VERSION ""

NS_ :

BS_:

BU_: MCTM_LS TIM_LS EOCM2cp_K2_LS EOCM2cp_K1_LS ADIMa_LS BCM_LS SAM_SR_LS SAM_SL_LS SAM_PR_LS SAM_PL_LS CGM3a_LS Dummy_LS VICM_LS ECC_LS PEPS_LS AOS_LS SDM_PR_LS AOS2_LS DLM_LS SCCM_2_LS SCCM_1_LS UPA_LS ADIMb_LS

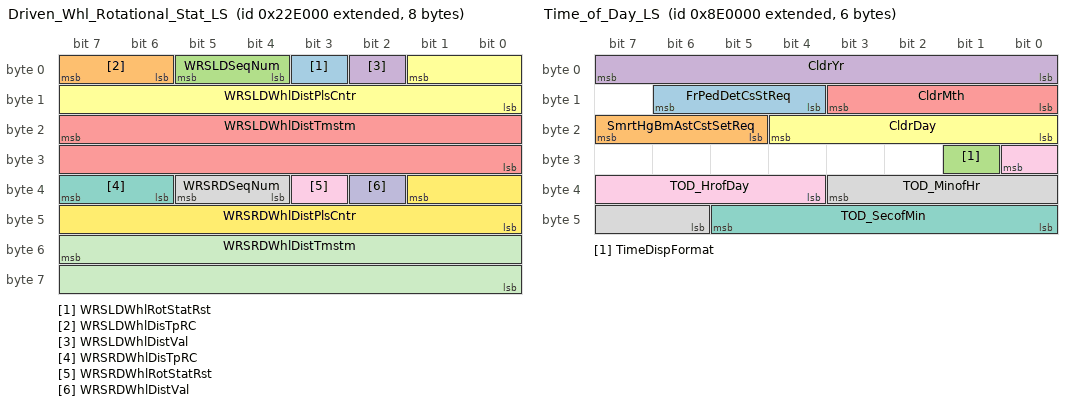
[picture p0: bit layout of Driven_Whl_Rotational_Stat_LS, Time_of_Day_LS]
BO_ 2149769216 Driven_Whl_Rotational_Stat_LS: 8 BCM_LS
 SG_ WRSLDWhlRotStatRst : 3|1@0+ (1,0) [0|1] ""  CGM3a_LS,UPA_LS
 SG_ WRSLDWhlDisTpRC : 7|2@0+ (1,0) [0|3] "counts"  CGM3a_LS,UPA_LS
 SG_ WRSLDSeqNum : 5|2@0+ (1,0) [0|3] "counts"  CGM3a_LS,UPA_LS
 SG_ WRSLDWhlDistVal : 2|1@0+ (1,0) [0|1] ""  CGM3a_LS,UPA_LS
 SG_ WRSLDWhlDistTmstm : 23|16@0+ (1,0) [0|65535] "counts"  CGM3a_LS,UPA_LS
 SG_ WRSLDWhlDistPlsCntr : 1|10@0+ (1,0) [0|1023] "counts"  CGM3a_LS,UPA_LS
 SG_ WRSRDWhlDisTpRC : 39|2@0+ (1,0) [0|3] "counts"  CGM3a_LS,UPA_LS
 SG_ WRSRDSeqNum : 37|2@0+ (1,0) [0|3] "counts"  CGM3a_LS,UPA_LS
 SG_ WRSRDWhlRotStatRst : 35|1@0+ (1,0) [0|1] ""  CGM3a_LS,UPA_LS
 SG_ WRSRDWhlDistVal : 34|1@0+ (1,0) [0|1] ""  CGM3a_LS,UPA_LS
 SG_ WRSRDWhlDistTmstm : 55|16@0+ (1,0) [0|65535] "counts"  CGM3a_LS,UPA_LS
 SG_ WRSRDWhlDistPlsCntr : 33|10@0+ (1,0) [0|1023] "counts"  CGM3a_LS,UPA_LS

BO_ 2156789760 Time_of_Day_LS: 6 CGM3a_LS
 SG_ FrPedDetCsStReq : 14|3@0+ (1,0) [0|7] ""  EOCM2cp_K1_LS
 SG_ SmrtHgBmAstCstSetReq : 23|3@0+ (1,0) [0|7] ""  EOCM2cp_K2_LS
 SG_ TimeDispFormat : 25|1@0+ (1,0) [0|1] ""  VICM_LS,EOCM2cp_K1_LS
 SG_ CldrYr : 7|8@0+ (1,2000) [2000|2255] "year"  EOCM2cp_K1_LS,VICM_LS,BCM_LS
 SG_ CldrMth : 11|4@0+ (1,0) [0|15] ""  EOCM2cp_K1_LS,ECC_LS,VICM_LS,BCM_LS
 SG_ CldrDay : 20|5@0+ (1,0) [0|31] "days"  EOCM2cp_K1_LS,ECC_LS,VICM_LS,BCM_LS
 SG_ TOD_SecofMin : 45|6@0+ (1,0) [0|63] "s"  VICM_LS,EOCM2cp_K1_LS,ECC_LS,BCM_LS
 SG_ TOD_MinofHr : 35|6@0+ (1,0) [0|63] "min"  VICM_LS,EOCM2cp_K1_LS,ECC_LS,BCM_LS
 SG_ TOD_HrofDay : 24|5@0+ (1,0) [0|31] "hr"  VICM_LS,EOCM2cp_K1_LS,ECC_LS,BCM_LS

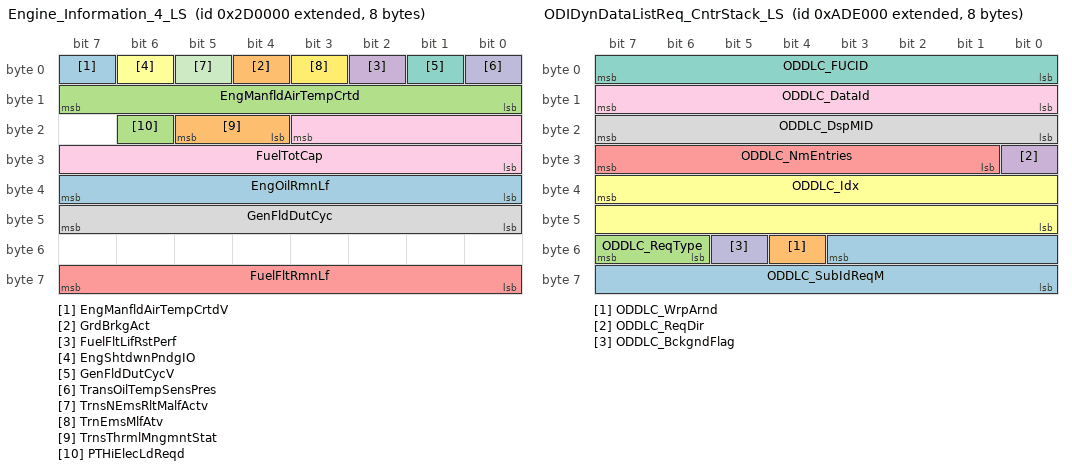
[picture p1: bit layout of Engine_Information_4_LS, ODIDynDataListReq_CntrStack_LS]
BO_ 2150432768 Engine_Information_4_LS: 8 BCM_LS
 SG_ EngManfldAirTempCrtdV : 7|1@0+ (1,0) [0|1] ""  CGM3a_LS,ECC_LS
 SG_ GrdBrkgAct : 4|1@0+ (1,0) [0|1] ""  CGM3a_LS
 SG_ EngManfldAirTempCrtd : 15|8@0+ (1,-40) [-40|215] "deg C"  CGM3a_LS,ECC_LS
 SG_ FuelFltLifRstPerf : 2|1@0+ (1,0) [0|1] ""  CGM3a_LS
 SG_ FuelFltRmnLf : 63|8@0+ (0.392157,0) [0|100.000035] "%"  CGM3a_LS
 SG_ EngShtdwnPndgIO : 6|1@0+ (1,0) [0|1] ""  CGM3a_LS
 SG_ GenFldDutCycV : 1|1@0+ (1,0) [0|1] ""  CGM3a_LS,ECC_LS
 SG_ GenFldDutCyc : 47|8@0+ (0.392157,0) [0|100.000035] "%"  CGM3a_LS,ECC_LS
 SG_ FuelTotCap : 19|12@0+ (0.125,0) [0|511.875] "liters"  CGM3a_LS
 SG_ TransOilTempSensPres : 0|1@0+ (1,0) [0|1] ""  CGM3a_LS
 SG_ TrnsNEmsRltMalfActv : 5|1@0+ (1,0) [0|1] ""  CGM3a_LS
 SG_ TrnEmsMlfAtv : 3|1@0+ (1,0) [0|1] ""  CGM3a_LS
 SG_ EngOilRmnLf : 39|8@0+ (0.392157,0) [0|100.000035] "%"  CGM3a_LS
 SG_ TrnsThrmlMngmntStat : 21|2@0+ (1,0) [0|3] ""  CGM3a_LS
 SG_ PTHiElecLdReqd : 22|1@0+ (1,0) [0|1] ""  CGM3a_LS,ECC_LS

BO_ 2155298816 Tire_Pressure_Sensor_Prog_Req_LS: 1 CGM3a_LS
 SG_ TrPrsMntrTrLdRstRqstd : 2|2@0+ (1,0) [0|3] ""  BCM_LS
 SG_ TrPrsSnsProgEvntRqd : 0|1@0+ (1,0) [0|1] ""  BCM_LS

BO_ 2158878720 ODIDynDataListReq_CntrStack_LS: 8 CGM3a_LS
 SG_ ODDLC_SubIdReqM : 51|12@0+ (1,0) [0|4095] ""  BCM_LS,CGM3a_LS
 SG_ ODDLC_WrpArnd : 52|1@0+ (1,0) [0|1] ""  BCM_LS,CGM3a_LS
 SG_ ODDLC_ReqType : 55|2@0+ (1,0) [0|3] ""  BCM_LS,CGM3a_LS
 SG_ ODDLC_ReqDir : 24|1@0+ (1,0) [0|1] ""  BCM_LS,CGM3a_LS
 SG_ ODDLC_NmEntries : 31|7@0+ (1,0) [0|127] ""  BCM_LS,CGM3a_LS
 SG_ ODDLC_Idx : 39|16@0+ (1,0) [0|65535] ""  BCM_LS,CGM3a_LS
 SG_ ODDLC_FUCID : 7|8@0+ (1,0) [0|255] ""  BCM_LS,CGM3a_LS
 SG_ ODDLC_DspMID : 23|8@0+ (1,0) [0|255] ""  BCM_LS,CGM3a_LS
 SG_ ODDLC_DataId : 15|8@0+ (1,0) [0|255] ""  BCM_LS,CGM3a_LS
 SG_ ODDLC_BckgndFlag : 53|1@0+ (1,0) [0|1] ""  BCM_LS,CGM3a_LS

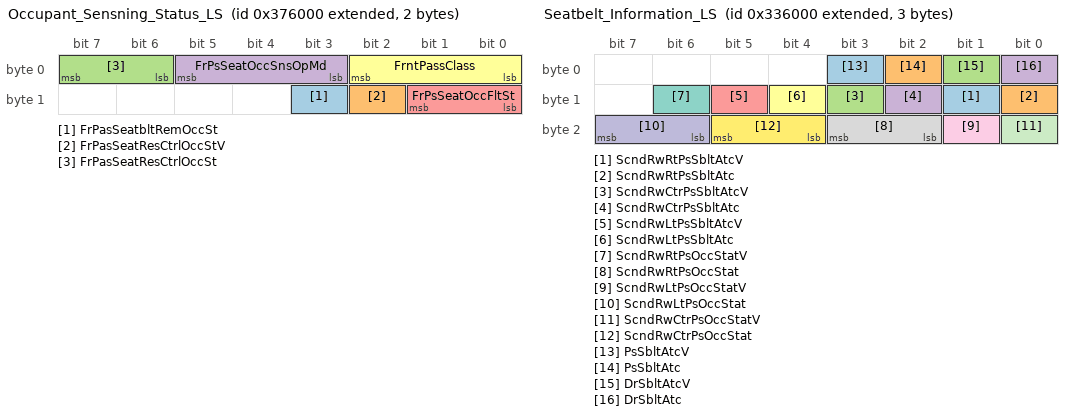
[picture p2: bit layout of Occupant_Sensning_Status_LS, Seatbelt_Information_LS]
BO_ 2151112704 Occupant_Sensning_Status_LS: 2 AOS_LS
 SG_ FrPasSeatbltRemOccSt : 11|1@0+ (1,0) [0|1] ""  MCTM_LS,CGM3a_LS,ADIMb_LS,SDM_PR_LS
 SG_ FrPasSeatResCtrlOccStV : 10|1@0+ (1,0) [0|1] ""  MCTM_LS,CGM3a_LS,ECC_LS,SDM_PR_LS
 SG_ FrPasSeatResCtrlOccSt : 7|2@0+ (1,0) [0|3] ""  MCTM_LS,CGM3a_LS,ECC_LS,SDM_PR_LS
 SG_ FrPsSeatOccSnsOpMd : 5|3@0+ (1,0) [0|7] "N/A"  CGM3a_LS,SDM_PR_LS
 SG_ FrPsSeatOccFltSt : 9|2@0+ (1,0) [0|3] "N/A"  MCTM_LS,CGM3a_LS,SDM_PR_LS
 SG_ FrntPassClass : 2|3@0+ (1,0) [0|7] ""  MCTM_LS,CGM3a_LS,SDM_PR_LS

BO_ 1367 UUDT_Resp_From_ADIMa_LS: 8 ADIMa_LS
 SG_ DgnInf_LS557 : 7|64@0+ (1,0) [0|1.84467440737096E+019] ""  CGM3a_LS

BO_ 2153947136 Remote_Reflash_Stat_LS: 1 BCM_LS
 SG_ RmtRflshMdAct : 7|1@0+ (1,0) [0|1] ""  CGM3a_LS

BO_ 2153938944 Remote_Reflash_Req_LS: 1 CGM3a_LS
 SG_ RmtRflshMdReqtd : 7|1@0+ (1,0) [0|1] ""  BCM_LS

BO_ 2028 USDT_Resp_From_VICM_LS: 8 VICM_LS
 SG_ DgnInf : 7|64@0+ (1,0) [0|1.84467440737096E+019] ""  CGM3a_LS

BO_ 2150662144 Environment_Id_Resp_3_LS: 3 CGM3a_LS
 SG_ EnvIdRsp3 : 7|16@0+ (1,0) [0|65535] ""  BCM_LS
 SG_ EnvIdRspSt3 : 17|2@0+ (1,0) [0|3] ""  BCM_LS

BO_ 2150653952 Environment_Id_Resp_2_LS: 3 ECC_LS
 SG_ EnvIdRspSt2 : 17|2@0+ (1,0) [0|3] ""  CGM3a_LS,BCM_LS
 SG_ EnvIdRsp2 : 7|16@0+ (1,0) [0|65535] ""  CGM3a_LS,BCM_LS

BO_ 2150850560 Seatbelt_Information_LS: 3 SDM_PR_LS
 SG_ ScndRwRtPsSbltAtcV : 9|1@0+ (1,0) [0|1] ""  ADIMa_LS,MCTM_LS,EOCM2cp_K2_LS,ADIMb_LS,BCM_LS,ECC_LS,CGM3a_LS
 SG_ ScndRwRtPsSbltAtc : 8|1@0+ (1,0) [0|1] ""  ADIMa_LS,MCTM_LS,EOCM2cp_K2_LS,ADIMb_LS,BCM_LS,ECC_LS,CGM3a_LS
 SG_ ScndRwCtrPsSbltAtcV : 11|1@0+ (1,0) [0|1] ""  ADIMa_LS,MCTM_LS,EOCM2cp_K2_LS,ADIMb_LS,BCM_LS,ECC_LS,CGM3a_LS
 SG_ ScndRwCtrPsSbltAtc : 10|1@0+ (1,0) [0|1] ""  ADIMa_LS,MCTM_LS,EOCM2cp_K2_LS,ADIMb_LS,BCM_LS,ECC_LS,CGM3a_LS
 SG_ ScndRwLtPsSbltAtcV : 13|1@0+ (1,0) [0|1] ""  ADIMa_LS,MCTM_LS,EOCM2cp_K2_LS,ADIMb_LS,BCM_LS,ECC_LS,CGM3a_LS
 SG_ ScndRwLtPsSbltAtc : 12|1@0+ (1,0) [0|1] ""  ADIMa_LS,MCTM_LS,EOCM2cp_K2_LS,ADIMb_LS,BCM_LS,ECC_LS,CGM3a_LS
 SG_ ScndRwRtPsOccStatV : 14|1@0+ (1,0) [0|1] ""  ADIMa_LS,ADIMb_LS,MCTM_LS,CGM3a_LS
 SG_ ScndRwRtPsOccStat : 19|2@0+ (1,0) [0|3] ""  ADIMa_LS,ADIMb_LS,MCTM_LS,CGM3a_LS
 SG_ ScndRwLtPsOccStatV : 17|1@0+ (1,0) [0|1] ""  ADIMa_LS,ADIMb_LS,MCTM_LS,CGM3a_LS
 SG_ ScndRwLtPsOccStat : 23|2@0+ (1,0) [0|3] ""  ADIMa_LS,ADIMb_LS,MCTM_LS,CGM3a_LS
 SG_ ScndRwCtrPsOccStatV : 16|1@0+ (1,0) [0|1] ""  ADIMa_LS,ADIMb_LS,MCTM_LS,CGM3a_LS
 SG_ ScndRwCtrPsOccStat : 21|2@0+ (1,0) [0|3] ""  ADIMa_LS,ADIMb_LS,MCTM_LS,CGM3a_LS
 SG_ PsSbltAtcV : 3|1@0+ (1,0) [0|1] ""  ADIMa_LS,ADIMb_LS,MCTM_LS,CGM3a_LS,ECC_LS,BCM_LS,AOS_LS
 SG_ PsSbltAtc : 2|1@0+ (1,0) [0|1] ""  ADIMa_LS,ADIMb_LS,MCTM_LS,CGM3a_LS,ECC_LS,BCM_LS,AOS_LS
 SG_ DrSbltAtcV : 1|1@0+ (1,0) [0|1] ""  AOS2_LS,ADIMa_LS,ADIMb_LS,MCTM_LS,CGM3a_LS,BCM_LS
 SG_ DrSbltAtc : 0|1@0+ (1,0) [0|1] ""  AOS2_LS,ADIMa_LS,ADIMb_LS,MCTM_LS,CGM3a_LS,BCM_LS

BO_ 2154938368 Fob_Programming_Mode_Status_LS: 1 BCM_LS
 SG_ FobProgMdStat : 1|2@0+ (1,0) [0|3] ""  CGM3a_LS

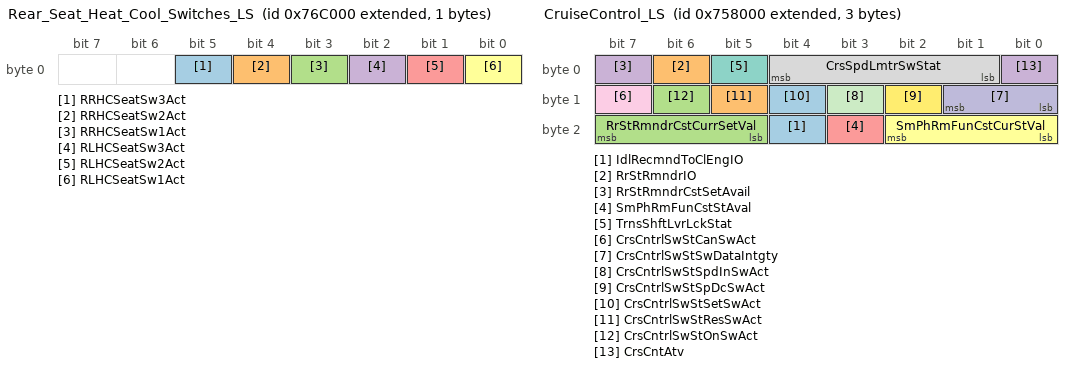
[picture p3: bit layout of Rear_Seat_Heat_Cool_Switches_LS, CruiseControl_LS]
BO_ 2155266048 Rear_Seat_Heat_Cool_Switches_LS: 1 ECC_LS
 SG_ RRHCSeatSw3Act : 5|1@0+ (1,0) [0|1] ""  CGM3a_LS,BCM_LS
 SG_ RRHCSeatSw2Act : 4|1@0+ (1,0) [0|1] ""  CGM3a_LS,BCM_LS
 SG_ RRHCSeatSw1Act : 3|1@0+ (1,0) [0|1] ""  CGM3a_LS,BCM_LS
 SG_ RLHCSeatSw3Act : 2|1@0+ (1,0) [0|1] ""  CGM3a_LS,BCM_LS
 SG_ RLHCSeatSw2Act : 1|1@0+ (1,0) [0|1] ""  CGM3a_LS,BCM_LS
 SG_ RLHCSeatSw1Act : 0|1@0+ (1,0) [0|1] ""  CGM3a_LS,BCM_LS

BO_ 2155249664 Rear_Seat_Heat_Cool_Control_LS: 4 BCM_LS
 SG_ RRHCSMInd3 : 8|1@0+ (1,0) [0|1] ""  CGM3a_LS,BCM_LS,ECC_LS
 SG_ RRHCSMInd2 : 9|1@0+ (1,0) [0|1] ""  CGM3a_LS,BCM_LS,ECC_LS
 SG_ RRHCSMInd1 : 10|1@0+ (1,0) [0|1] ""  CGM3a_LS,BCM_LS,ECC_LS
 SG_ RRHCSMIndReq : 12|2@0+ (1,0) [0|3] ""  CGM3a_LS,BCM_LS,ECC_LS
 SG_ RRHCSLSeatLev5 : 24|1@0+ (1,0) [0|1] ""  CGM3a_LS,BCM_LS,ECC_LS
 SG_ RRHCSLSeatLev4 : 25|1@0+ (1,0) [0|1] ""  CGM3a_LS,BCM_LS,ECC_LS
 SG_ RRHCSLSeatLev3 : 26|1@0+ (1,0) [0|1] ""  CGM3a_LS,BCM_LS,ECC_LS
 SG_ RRHCSLSeatLev2 : 27|1@0+ (1,0) [0|1] ""  CGM3a_LS,BCM_LS,ECC_LS
 SG_ RRHCSLSeatLev1 : 28|1@0+ (1,0) [0|1] ""  CGM3a_LS,BCM_LS,ECC_LS
 SG_ RRHCSLIndReq : 30|2@0+ (1,0) [0|3] ""  CGM3a_LS,BCM_LS,ECC_LS
 SG_ RLHCSMInd3 : 0|1@0+ (1,0) [0|1] ""  CGM3a_LS,BCM_LS,ECC_LS
 SG_ RLHCSMInd2 : 1|1@0+ (1,0) [0|1] ""  CGM3a_LS,BCM_LS,ECC_LS
 SG_ RLHCSMInd1 : 2|1@0+ (1,0) [0|1] ""  CGM3a_LS,BCM_LS,ECC_LS
 SG_ RLHCSMIndReq : 4|2@0+ (1,0) [0|3] ""  CGM3a_LS,BCM_LS,ECC_LS
 SG_ RLHCSLSeatLev5 : 16|1@0+ (1,0) [0|1] ""  CGM3a_LS,BCM_LS,ECC_LS
 SG_ RLHCSLSeatLev4 : 17|1@0+ (1,0) [0|1] ""  CGM3a_LS,BCM_LS,ECC_LS
 SG_ RLHCSLSeatLev3 : 18|1@0+ (1,0) [0|1] ""  CGM3a_LS,BCM_LS,ECC_LS
 SG_ RLHCSLSeatLev2 : 19|1@0+ (1,0) [0|1] ""  CGM3a_LS,BCM_LS,ECC_LS
 SG_ RLHCSLSeatLev1 : 20|1@0+ (1,0) [0|1] ""  CGM3a_LS,BCM_LS,ECC_LS
 SG_ RLHCSLIndReq : 22|2@0+ (1,0) [0|3] ""  CGM3a_LS,BCM_LS,ECC_LS

BO_ 2155184128 CruiseControl_LS: 3 BCM_LS
 SG_ IdlRecmndToClEngIO : 20|1@0+ (1,0) [0|1] ""  CGM3a_LS
 SG_ RrStRmndrIO : 6|1@0+ (1,0) [0|1] ""  CGM3a_LS
 SG_ RrStRmndrCstCurrSetVal : 23|3@0+ (1,0) [0|7] ""  CGM3a_LS
 SG_ RrStRmndrCstSetAvail : 7|1@0+ (1,0) [0|1] ""  CGM3a_LS
 SG_ SmPhRmFunCstStAval : 19|1@0+ (1,0) [0|1] ""  CGM3a_LS
 SG_ SmPhRmFunCstCurStVal : 18|3@0+ (1,0) [0|7] ""  CGM3a_LS
 SG_ TrnsShftLvrLckStat : 5|1@0+ (1,0) [0|1] ""  CGM3a_LS
 SG_ CrsSpdLmtrSwStat : 4|4@0+ (1,0) [0|15] ""  CGM3a_LS,SDM_PR_LS
 SG_ CrsCntrlSwStCanSwAct : 15|1@0+ (1,0) [0|1] ""  CGM3a_LS,SDM_PR_LS
 SG_ CrsCntrlSwStSwDataIntgty : 9|2@0+ (1,0) [0|3] ""  CGM3a_LS,SDM_PR_LS
 SG_ CrsCntrlSwStSpdInSwAct : 11|1@0+ (1,0) [0|1] ""  CGM3a_LS,SDM_PR_LS
 SG_ CrsCntrlSwStSpDcSwAct : 10|1@0+ (1,0) [0|1] ""  CGM3a_LS,SDM_PR_LS
 SG_ CrsCntrlSwStSetSwAct : 12|1@0+ (1,0) [0|1] ""  CGM3a_LS,SDM_PR_LS
 SG_ CrsCntrlSwStResSwAct : 13|1@0+ (1,0) [0|1] ""  CGM3a_LS,SDM_PR_LS
 SG_ CrsCntrlSwStOnSwAct : 14|1@0+ (1,0) [0|1] ""  CGM3a_LS,SDM_PR_LS
 SG_ CrsCntAtv : 0|1@0+ (1,0) [0|1] ""  CGM3a_LS,SDM_PR_LS

BO_ 2155167744 Power_Mode_Info_LS: 3 BCM_LS
 SG_ ShftToNtrlIO : 1|1@0+ (1,0) [0|1] ""  SAM_SR_LS,SAM_SL_LS,SAM_PR_LS,SAM_PL_LS,CGM3a_LS
 SG_ AppPrkBrkIO : 12|1@0+ (1,0) [0|1] ""  SAM_SR_LS,SAM_SL_LS,SAM_PR_LS,SAM_PL_LS,CGM3a_LS
 SG_ NRmtDtctdRstrtAllwd : 20|1@0+ (1,0) [0|1] ""  SAM_SR_LS,SAM_SL_LS,SAM_PR_LS,SAM_PL_LS,CGM3a_LS
 SG_ NRmtDtdPsCluRstIO : 13|1@0+ (1,0) [0|1] ""  SAM_SR_LS,SAM_SL_LS,SAM_PR_LS,SAM_PL_LS,CGM3a_LS
 SG_ SecPwrMdPshBtnAtv : 3|1@0+ (1,0) [0|1] ""  SAM_SR_LS,SAM_SL_LS,SAM_PR_LS,SAM_PL_LS,CGM3a_LS,PEPS_LS
 SG_ TSLgMdPwrCtOWAtv : 19|1@0+ (1,0) [0|1] ""  SAM_SR_LS,SAM_SL_LS,SAM_PR_LS,SAM_PL_LS,CGM3a_LS
 SG_ PrsBtnAgnTTrnEngOffIO : 18|1@0+ (1,0) [0|1] ""  SAM_SR_LS,SAM_SL_LS,SAM_PR_LS,SAM_PL_LS,CGM3a_LS
 SG_ NRmtDtdPsBrkRstIO : 17|1@0+ (1,0) [0|1] ""  SAM_SR_LS,SAM_SL_LS,SAM_PR_LS,SAM_PL_LS,CGM3a_LS
 SG_ NoReDetInOn : 16|1@0+ (1,0) [0|1] ""  SAM_SR_LS,SAM_SL_LS,SAM_PR_LS,SAM_PL_LS,CGM3a_LS
 SG_ ApplyCltPdlIO : 15|1@0+ (1,0) [0|1] ""  SAM_SR_LS,SAM_SL_LS,SAM_PR_LS,SAM_PL_LS,CGM3a_LS
 SG_ VehMovState : 10|3@0+ (1,0) [0|7] ""  SAM_SR_LS,SAM_SL_LS,SAM_PR_LS,SAM_PL_LS,PEPS_LS,CGM3a_LS,MCTM_LS,UPA_LS
 SG_ TrStLgMdAtv : 7|1@0+ (1,0) [0|1] ""  SAM_SR_LS,SAM_SL_LS,SAM_PR_LS,SAM_PL_LS,AOS2_LS,SCCM_2_LS,SCCM_1_LS,CGM3a_LS,TIM_LS,PEPS_LS,AOS_LS,SDM_PR_LS,UPA_LS,ECC_LS
 SG_ TransModInactIO : 5|1@0+ (1,0) [0|1] ""  SAM_SR_LS,SAM_SL_LS,SAM_PR_LS,SAM_PL_LS,CGM3a_LS
 SG_ TransModActIO : 4|1@0+ (1,0) [0|1] ""  SAM_SR_LS,SAM_SL_LS,SAM_PR_LS,SAM_PL_LS,CGM3a_LS
 SG_ ApplyBrkPdlIO : 14|1@0+ (1,0) [0|1] ""  SAM_SR_LS,SAM_SL_LS,SAM_PR_LS,SAM_PL_LS,CGM3a_LS
 SG_ Ky_IdDevPr : 2|1@0+ (1,0) [0|1] ""  SAM_SR_LS,SAM_SL_LS,SAM_PR_LS,SAM_PL_LS,CGM3a_LS
 SG_ KylsStrtUseTxPckIO : 6|1@0+ (1,0) [0|1] ""  SAM_SR_LS,SAM_SL_LS,SAM_PR_LS,SAM_PL_LS,CGM3a_LS
 SG_ ShftPrkIO : 0|1@0+ (1,0) [0|1] ""  SAM_SR_LS,SAM_SL_LS,SAM_PR_LS,SAM_PL_LS,CGM3a_LS

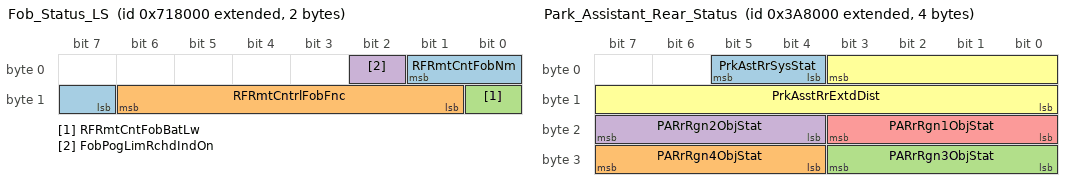
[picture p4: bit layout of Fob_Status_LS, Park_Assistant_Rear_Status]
BO_ 2154921984 Fob_Status_LS: 2 BCM_LS
 SG_ RFRmtCntFobNm : 1|3@0+ (1,0) [0|7] ""  CGM3a_LS,PEPS_LS,VICM_LS
 SG_ RFRmtCntrlFobFnc : 14|6@0+ (1,0) [0|63] ""  CGM3a_LS,PEPS_LS,VICM_LS
 SG_ RFRmtCntFobBatLw : 8|1@0+ (1,0) [0|1] ""  CGM3a_LS,PEPS_LS,VICM_LS
 SG_ FobPogLimRchdIndOn : 2|1@0+ (1,0) [0|1] ""  CGM3a_LS

BO_ 2151317504 Park_Assistant_Rear_Status: 4 UPA_LS
 SG_ PrkAstRrSysStat : 5|2@0+ (1,0) [0|3] ""  CGM3a_LS
 SG_ PARrRgn4ObjStat : 31|4@0+ (1,0) [0|15] ""  CGM3a_LS
 SG_ PARrRgn3ObjStat : 27|4@0+ (1,0) [0|15] ""  CGM3a_LS
 SG_ PARrRgn2ObjStat : 23|4@0+ (1,0) [0|15] ""  CGM3a_LS
 SG_ PARrRgn1ObjStat : 19|4@0+ (1,0) [0|15] ""  CGM3a_LS
 SG_ PrkAsstRrExtdDist : 3|12@0+ (0.01,0) [0|40.95] "m"  CGM3a_LS

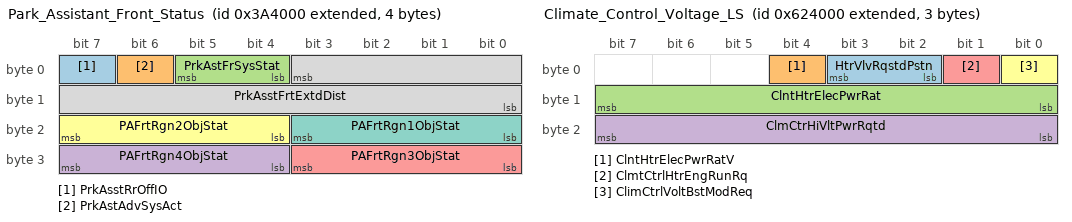
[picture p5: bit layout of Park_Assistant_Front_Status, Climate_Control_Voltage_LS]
BO_ 2151301120 Park_Assistant_Front_Status: 4 UPA_LS
 SG_ PrkAsstRrOffIO : 7|1@0+ (1,0) [0|1] "" Vector__XXX
 SG_ PrkAstAdvSysAct : 6|1@0+ (1,0) [0|1] ""  CGM3a_LS,BCM_LS,EOCM2cp_K2_LS
 SG_ PrkAstFrSysStat : 5|2@0+ (1,0) [0|3] ""  CGM3a_LS,EOCM2cp_K2_LS
 SG_ PAFrtRgn4ObjStat : 31|4@0+ (1,0) [0|15] ""  CGM3a_LS,EOCM2cp_K2_LS
 SG_ PAFrtRgn3ObjStat : 27|4@0+ (1,0) [0|15] ""  CGM3a_LS,EOCM2cp_K2_LS
 SG_ PAFrtRgn2ObjStat : 23|4@0+ (1,0) [0|15] ""  CGM3a_LS,EOCM2cp_K2_LS
 SG_ PAFrtRgn1ObjStat : 19|4@0+ (1,0) [0|15] ""  CGM3a_LS,EOCM2cp_K2_LS
 SG_ PrkAsstFrtExtdDist : 3|12@0+ (0.01,0) [0|40.95] "m"  CGM3a_LS,EOCM2cp_K2_LS

BO_ 2153922560 Climate_Control_Voltage_LS: 3 ECC_LS
 SG_ HtrVlvRqstdPstn : 3|2@0+ (1,0) [0|3] ""  CGM3a_LS,VICM_LS
 SG_ ClntHtrElecPwrRatV : 4|1@0+ (1,0) [0|1] ""  DLM_LS,CGM3a_LS,VICM_LS
 SG_ ClntHtrElecPwrRat : 15|8@0+ (0.04,0) [0|10.2] "kW"  DLM_LS,CGM3a_LS,VICM_LS
 SG_ ClmCtrHiVltPwrRqtd : 23|8@0+ (0.1,0) [0|25.5] "kW"  CGM3a_LS,VICM_LS
 SG_ ClmtCtrlHtrEngRunRq : 1|1@0+ (1,0) [0|1] ""  CGM3a_LS,BCM_LS
 SG_ ClimCtrlVoltBstModReq : 0|1@0+ (1,0) [0|1] ""  CGM3a_LS,BCM_LS

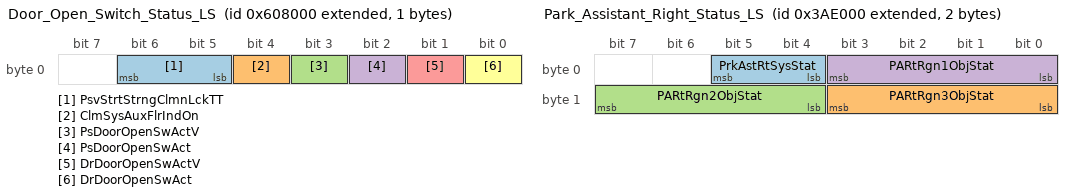
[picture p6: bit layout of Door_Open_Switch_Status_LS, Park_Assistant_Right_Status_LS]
BO_ 2153807872 Door_Open_Switch_Status_LS: 1 PEPS_LS
 SG_ PsvStrtStrngClmnLckTT : 6|2@0+ (1,0) [0|3] ""  ADIMa_LS,ADIMb_LS,CGM3a_LS
 SG_ ClmSysAuxFlrIndOn : 4|1@0+ (1,0) [0|1] ""  ADIMa_LS,ADIMb_LS,CGM3a_LS
 SG_ PsDoorOpenSwActV : 3|1@0+ (1,0) [0|1] ""  ADIMa_LS,ADIMb_LS,CGM3a_LS,BCM_LS
 SG_ PsDoorOpenSwAct : 2|1@0+ (1,0) [0|1] ""  ADIMa_LS,ADIMb_LS,CGM3a_LS,BCM_LS
 SG_ DrDoorOpenSwActV : 1|1@0+ (1,0) [0|1] ""  ADIMa_LS,ADIMb_LS,CGM3a_LS,BCM_LS
 SG_ DrDoorOpenSwAct : 0|1@0+ (1,0) [0|1] ""  ADIMa_LS,ADIMb_LS,CGM3a_LS,BCM_LS

BO_ 2151399424 Wash_Level_LS: 1 CGM3a_LS
 SG_ WshFldLw : 0|1@0+ (1,0) [0|1] ""  BCM_LS

BO_ 1359 UUDT_Resp_From_ADIMb_LS: 8 ADIMb_LS
 SG_ DgnInf_LS54F : 7|64@0+ (1,0) [0|1.84467440737096E+019] ""  CGM3a_LS

BO_ 2154733568 Power_Door_Status_LS: 6 BCM_LS
 SG_ LRPwrDrPosPlsblityFltAct : 33|1@0+ (1,0) [0|1] ""  CGM3a_LS
 SG_ LFPwrDrPosPlsblityFltAct : 34|1@0+ (1,0) [0|1] ""  ADIMb_LS,CGM3a_LS
 SG_ LFPwrDrPos : 46|7@0+ (0.78,0) [0|100] ""  ADIMb_LS,CGM3a_LS
 SG_ LFPwrDrInMtn : 35|1@0+ (1,0) [0|1] ""  ADIMb_LS,CGM3a_LS
 SG_ LFDrOpen : 47|1@0+ (1,0) [0|1] ""  ADIMb_LS,CGM3a_LS
 SG_ DrClsgMtrLFStllDtd : 8|1@0+ (1,0) [0|1] ""  CGM3a_LS
 SG_ RRDrOpen : 32|1@0+ (1,0) [0|1] ""  CGM3a_LS,ADIMb_LS
 SG_ LRDrOpen : 31|1@0+ (1,0) [0|1] ""  CGM3a_LS,ADIMb_LS
 SG_ RFDrOpen : 30|1@0+ (1,0) [0|1] ""  CGM3a_LS,ADIMb_LS
 SG_ RRPwrDrPosPlsblityFltAct : 16|1@0+ (1,0) [0|1] ""  CGM3a_LS,ADIMb_LS
 SG_ RFPwrDrPosPlsblityFltACt : 0|1@0+ (1,0) [0|1] ""  CGM3a_LS,ADIMb_LS
 SG_ RRPwrDrPos : 23|7@0+ (0.78,0) [0|100] ""  CGM3a_LS,ADIMb_LS
 SG_ LRPwrDrPos : 15|7@0+ (0.78,0) [0|100] ""  CGM3a_LS,ADIMb_LS
 SG_ RFPwrDrPos : 7|7@0+ (0.78,0) [0|100] ""  CGM3a_LS,ADIMb_LS
 SG_ RRPwrDrInMtn : 29|1@0+ (1,0) [0|1] ""  CGM3a_LS,ADIMb_LS
 SG_ LRPwrDrInMtn : 28|1@0+ (1,0) [0|1] ""  CGM3a_LS,ADIMb_LS
 SG_ RFPwrDrInMtn : 27|1@0+ (1,0) [0|1] ""  CGM3a_LS,ADIMb_LS
 SG_ DrClsgMtrRRStllDtd : 26|1@0+ (1,0) [0|1] ""  CGM3a_LS,ADIMb_LS
 SG_ DrClsgMtrLRStllDtd : 25|1@0+ (1,0) [0|1] ""  CGM3a_LS,ADIMb_LS
 SG_ DrClsgMtrRLStllDtd : 24|1@0+ (1,0) [0|1] ""  CGM3a_LS,ADIMb_LS

BO_ 2151342080 Park_Assistant_Right_Status_LS: 2 UPA_LS
 SG_ PrkAstRtSysStat : 5|2@0+ (1,0) [0|3] ""  CGM3a_LS
 SG_ PARtRgn3ObjStat : 11|4@0+ (1,0) [0|15] ""  CGM3a_LS
 SG_ PARtRgn2ObjStat : 15|4@0+ (1,0) [0|15] ""  CGM3a_LS
 SG_ PARtRgn1ObjStat : 3|4@0+ (1,0) [0|15] ""  CGM3a_LS

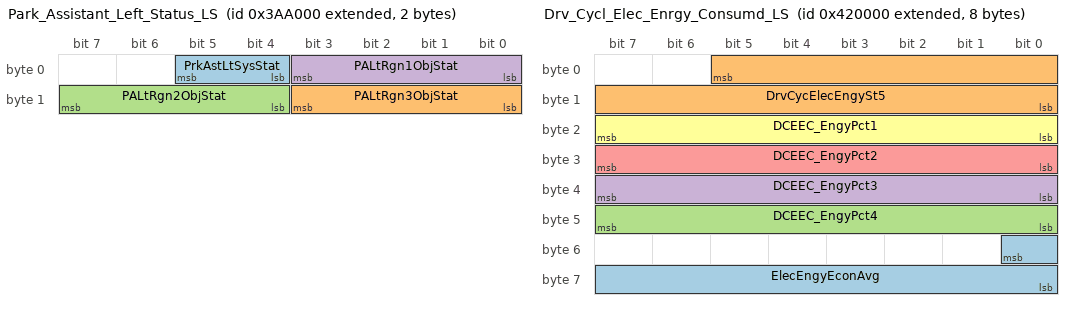
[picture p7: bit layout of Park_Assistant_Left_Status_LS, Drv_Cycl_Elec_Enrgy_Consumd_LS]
BO_ 2151325696 Park_Assistant_Left_Status_LS: 2 UPA_LS
 SG_ PrkAstLtSysStat : 5|2@0+ (1,0) [0|3] ""  CGM3a_LS
 SG_ PALtRgn3ObjStat : 11|4@0+ (1,0) [0|15] ""  CGM3a_LS
 SG_ PALtRgn2ObjStat : 15|4@0+ (1,0) [0|15] ""  CGM3a_LS
 SG_ PALtRgn1ObjStat : 3|4@0+ (1,0) [0|15] ""  CGM3a_LS

BO_ 2151809024 Drv_Cycl_Elec_Enrgy_Consumd_LS: 8 VICM_LS
 SG_ ElecEngyEconAvg : 48|9@0+ (0.1,0) [0|51.1] ""  CGM3a_LS
 SG_ DrvCycElecEngySt5 : 5|14@0+ (0.36,0) [0|5897.88] "MJ"  CGM3a_LS
 SG_ DCEEC_EngyPct4 : 47|8@0+ (0.392157,0) [0|100.000035] "%"  CGM3a_LS
 SG_ DCEEC_EngyPct3 : 39|8@0+ (0.392157,0) [0|100.000035] "%"  CGM3a_LS
 SG_ DCEEC_EngyPct2 : 31|8@0+ (0.392157,0) [0|100.000035] "%"  CGM3a_LS
 SG_ DCEEC_EngyPct1 : 23|8@0+ (0.392157,0) [0|100.000035] "%"  CGM3a_LS

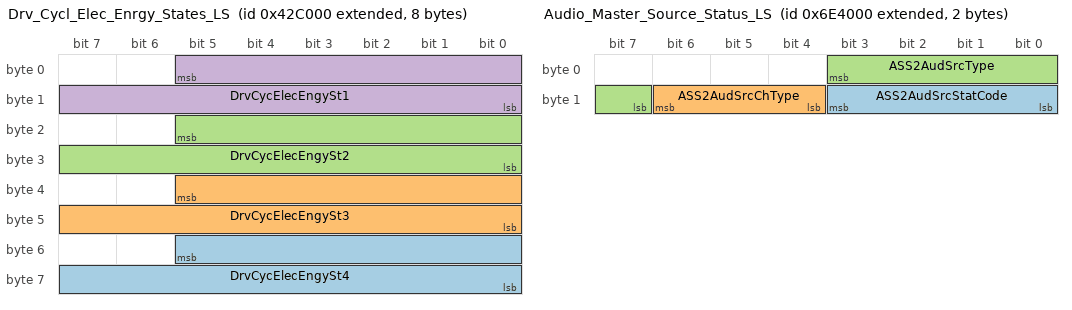
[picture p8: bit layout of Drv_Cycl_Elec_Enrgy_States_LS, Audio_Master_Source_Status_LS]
BO_ 2151858176 Drv_Cycl_Elec_Enrgy_States_LS: 8 VICM_LS
 SG_ DrvCycElecEngySt4 : 53|14@0+ (0.36,0) [0|5897.88] "MJ"  CGM3a_LS
 SG_ DrvCycElecEngySt3 : 37|14@0+ (0.36,0) [0|5897.88] "MJ"  CGM3a_LS
 SG_ DrvCycElecEngySt2 : 21|14@0+ (0.36,0) [0|5897.88] "MJ"  CGM3a_LS
 SG_ DrvCycElecEngySt1 : 5|14@0+ (0.36,0) [0|5897.88] "MJ"  CGM3a_LS

BO_ 2150547456 HMI_Hybrid_Vehicle_Status_LS: 8 VICM_LS
 SG_ HVDpltnMdCnfdcTrndg : 47|8@0- (0.787402,0) [-100.787456|100.000054] "%"  CGM3a_LS
 SG_ OffBrdHVCVehPwrLvl : 55|2@0+ (1,0) [0|3] ""  CGM3a_LS
 SG_ OffBrdHVCVehPwrDrtd : 26|1@0+ (1,0) [0|1] ""  CGM3a_LS
 SG_ OffBrdHVCVehCplrLkd : 16|1@0+ (1,0) [0|1] ""  CGM3a_LS
 SG_ OffBrdHVBlkChrgCmp : 37|1@0+ (1,0) [0|1] ""  CGM3a_LS
 SG_ OBHVBCCT_MinofHr : 61|6@0+ (1,0) [0|63] ""  CGM3a_LS
 SG_ OBHVBCCT_HrofDay : 50|5@0+ (1,0) [0|31] ""  CGM3a_LS
 SG_ OBHVBCCT_DayofWk : 53|3@0+ (1,0) [0|7] ""  CGM3a_LS
 SG_ ElecPrplsnMtrOvrSpdIO : 38|1@0+ (1,0) [0|1] ""  CGM3a_LS
 SG_ HVBatOutOfEnrgyInd : 36|3@0+ (1,0) [0|7] ""  CGM3a_LS
 SG_ CntrsOpnUndrTmpIO : 7|1@0+ (1,0) [0|1] ""  CGM3a_LS
 SG_ HVBatCntctrsOpnIO : 39|1@0+ (1,0) [0|1] ""  CGM3a_LS
 SG_ GrnAudQueReq : 4|1@0+ (1,0) [0|1] ""  CGM3a_LS
 SG_ SvcHybChrgSysIO : 5|1@0+ (1,0) [0|1] ""  CGM3a_LS
 SG_ HVChrgrSysStat : 29|3@0+ (1,0) [0|7] ""  CGM3a_LS
 SG_ HVChrgrCplrStat : 31|2@0+ (1,0) [0|3] ""  CGM3a_LS
 SG_ HVBatLimDTmpInd : 25|2@0+ (1,0) [0|3] ""  CGM3a_LS
 SG_ HVBatChrgCrdConnIO : 6|1@0+ (1,0) [0|1] ""  CGM3a_LS,BCM_LS
 SG_ VehChrgMdSt : 3|3@0+ (1,0) [0|7] ""  CGM3a_LS
 SG_ HVDpltnMdRng : 0|16@0+ (0.015625,0) [0|1023.984375] "km"  CGM3a_LS,BCM_LS
 SG_ ChgrSysAdblIndReq : 33|2@0+ (1,0) [0|3] ""  CGM3a_LS,BCM_LS

BO_ 2154708992 Audio_Master_Source_Status_LS: 2 CGM3a_LS
 SG_ ASS2AudSrcStatCode : 11|4@0+ (1,0) [0|15] ""  ECC_LS
 SG_ ASS2AudSrcChType : 14|3@0+ (1,0) [0|7] ""  ECC_LS
 SG_ ASS2AudSrcType : 3|5@0+ (1,0) [0|31] ""  ECC_LS

BO_ 2154471424 Rear_Closure_Ajar_Switch_Status: 1 BCM_LS
 SG_ RrClsrSnwLdIO : 1|1@0+ (1,0) [0|1] ""  CGM3a_LS
 SG_ RrClosAjarSwAct : 0|1@0+ (1,0) [0|1] ""  TIM_LS,CGM3a_LS,MCTM_LS,ECC_LS,PEPS_LS,BCM_LS

BO_ 2158796800 ODIIndication_LS: 8 ECC_LS
 SG_ ODII_ODIInd55 : 57|1@0+ (1,0) [0|1] ""  CGM3a_LS,MCTM_LS
 SG_ ODII_ODIInd54 : 58|1@0+ (1,0) [0|1] ""  CGM3a_LS,MCTM_LS
 SG_ ODII_ODIInd53 : 59|1@0+ (1,0) [0|1] ""  CGM3a_LS,MCTM_LS
 SG_ ODII_ODIInd52 : 60|1@0+ (1,0) [0|1] ""  CGM3a_LS,MCTM_LS
 SG_ ODII_ODIInd51 : 61|1@0+ (1,0) [0|1] ""  CGM3a_LS,MCTM_LS
 SG_ ODII_ODIInd50 : 62|1@0+ (1,0) [0|1] ""  CGM3a_LS,MCTM_LS
 SG_ ODII_ODIInd27 : 37|1@0+ (1,0) [0|1] ""  CGM3a_LS,MCTM_LS
 SG_ ODII_ODIInd26 : 38|1@0+ (1,0) [0|1] ""  CGM3a_LS,MCTM_LS
 SG_ ODII_ODIInd25 : 39|1@0+ (1,0) [0|1] ""  CGM3a_LS,MCTM_LS
 SG_ ODII_ODIInd24 : 24|1@0+ (1,0) [0|1] ""  CGM3a_LS,MCTM_LS
 SG_ ODII_ODIInd23 : 25|1@0+ (1,0) [0|1] ""  CGM3a_LS,MCTM_LS
 SG_ ODII_ODIInd22 : 26|1@0+ (1,0) [0|1] ""  CGM3a_LS,MCTM_LS
 SG_ ODII_ODIInd21 : 27|1@0+ (1,0) [0|1] ""  CGM3a_LS,MCTM_LS
 SG_ ODII_ODIInd20 : 28|1@0+ (1,0) [0|1] ""  CGM3a_LS,MCTM_LS
 SG_ ODII_ODIInd19 : 29|1@0+ (1,0) [0|1] ""  CGM3a_LS,MCTM_LS
 SG_ ODII_ODIInd18 : 30|1@0+ (1,0) [0|1] ""  CGM3a_LS,MCTM_LS
 SG_ ODII_ODIInd17 : 31|1@0+ (1,0) [0|1] ""  CGM3a_LS,MCTM_LS
 SG_ ODII_ODIInd16 : 16|1@0+ (1,0) [0|1] ""  CGM3a_LS,MCTM_LS
 SG_ ODII_ODIInd15 : 17|1@0+ (1,0) [0|1] ""  CGM3a_LS,MCTM_LS
 SG_ ODII_ODIInd14 : 18|1@0+ (1,0) [0|1] ""  CGM3a_LS,MCTM_LS
 SG_ ODII_ODIInd13 : 19|1@0+ (1,0) [0|1] ""  CGM3a_LS,MCTM_LS
 SG_ ODII_ODIInd12 : 20|1@0+ (1,0) [0|1] ""  CGM3a_LS,MCTM_LS
 SG_ ODII_ODIInd11 : 21|1@0+ (1,0) [0|1] ""  CGM3a_LS,MCTM_LS
 SG_ ODII_ODIInd10 : 22|1@0+ (1,0) [0|1] ""  CGM3a_LS,MCTM_LS
 SG_ ODII_ODIInd9 : 23|1@0+ (1,0) [0|1] ""  CGM3a_LS,MCTM_LS
 SG_ ODII_ODIInd8 : 8|1@0+ (1,0) [0|1] ""  CGM3a_LS,MCTM_LS
 SG_ ODII_ODIInd7 : 9|1@0+ (1,0) [0|1] ""  CGM3a_LS,MCTM_LS
 SG_ ODII_ODIInd6 : 10|1@0+ (1,0) [0|1] ""  CGM3a_LS,MCTM_LS
 SG_ ODII_ODIInd5 : 11|1@0+ (1,0) [0|1] ""  CGM3a_LS,MCTM_LS
 SG_ ODII_ODIInd4 : 12|1@0+ (1,0) [0|1] ""  CGM3a_LS,MCTM_LS
 SG_ ODII_ODIInd3 : 13|1@0+ (1,0) [0|1] ""  CGM3a_LS,MCTM_LS
 SG_ ODII_ODIInd2 : 14|1@0+ (1,0) [0|1] ""  CGM3a_LS,MCTM_LS
 SG_ ODII_ODIInd1 : 15|1@0+ (1,0) [0|1] ""  CGM3a_LS,MCTM_LS
 SG_ ODII_ODIInd56 : 56|1@0+ (1,0) [0|1] ""  CGM3a_LS,MCTM_LS
 SG_ ODII_ODIInd49 : 63|1@0+ (1,0) [0|1] ""  CGM3a_LS,MCTM_LS
 SG_ ODII_ODIInd48 : 48|1@0+ (1,0) [0|1] ""  CGM3a_LS,MCTM_LS
 SG_ ODII_ODIInd47 : 49|1@0+ (1,0) [0|1] ""  CGM3a_LS,MCTM_LS
 SG_ ODII_ODIInd46 : 50|1@0+ (1,0) [0|1] ""  CGM3a_LS,MCTM_LS
 SG_ ODII_ODIInd45 : 51|1@0+ (1,0) [0|1] ""  CGM3a_LS,MCTM_LS
 SG_ ODII_ODIInd44 : 52|1@0+ (1,0) [0|1] ""  CGM3a_LS,MCTM_LS
 SG_ ODII_ODIInd43 : 53|1@0+ (1,0) [0|1] ""  CGM3a_LS,MCTM_LS
 SG_ ODII_ODIInd42 : 54|1@0+ (1,0) [0|1] ""  CGM3a_LS,MCTM_LS
 SG_ ODII_ODIInd41 : 55|1@0+ (1,0) [0|1] ""  CGM3a_LS,MCTM_LS
 SG_ ODII_ODIInd40 : 40|1@0+ (1,0) [0|1] ""  CGM3a_LS,MCTM_LS
 SG_ ODII_ODIInd39 : 41|1@0+ (1,0) [0|1] ""  CGM3a_LS,MCTM_LS
 SG_ ODII_ODIInd38 : 42|1@0+ (1,0) [0|1] ""  CGM3a_LS,MCTM_LS
 SG_ ODII_ODIInd37 : 43|1@0+ (1,0) [0|1] ""  CGM3a_LS,MCTM_LS
 SG_ ODII_ODIInd36 : 44|1@0+ (1,0) [0|1] ""  CGM3a_LS,MCTM_LS
 SG_ ODII_ODIInd35 : 45|1@0+ (1,0) [0|1] ""  CGM3a_LS,MCTM_LS
 SG_ ODII_ODIInd34 : 46|1@0+ (1,0) [0|1] ""  CGM3a_LS,MCTM_LS
 SG_ ODII_ODIInd33 : 47|1@0+ (1,0) [0|1] ""  CGM3a_LS,MCTM_LS
 SG_ ODII_ODIInd32 : 32|1@0+ (1,0) [0|1] ""  CGM3a_LS,MCTM_LS
 SG_ ODII_ODIInd31 : 33|1@0+ (1,0) [0|1] ""  CGM3a_LS,MCTM_LS
 SG_ ODII_ODIInd30 : 34|1@0+ (1,0) [0|1] ""  CGM3a_LS,MCTM_LS
 SG_ ODII_ODIInd29 : 35|1@0+ (1,0) [0|1] ""  CGM3a_LS,MCTM_LS
 SG_ ODII_ODIInd28 : 36|1@0+ (1,0) [0|1] ""  CGM3a_LS,MCTM_LS
 SG_ ODII_FUCID : 7|8@0+ (1,0) [0|255] ""  CGM3a_LS,MCTM_LS

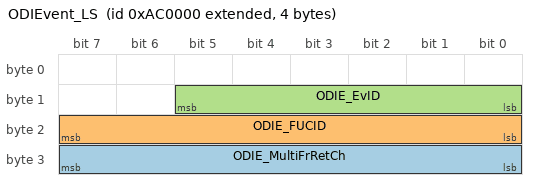
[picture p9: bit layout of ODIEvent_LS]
BO_ 2158755840 ODIEvent_LS: 4 ECC_LS
 SG_ ODIE_MultiFrRetCh : 31|8@0+ (1,0) [0|255] ""  CGM3a_LS,MCTM_LS
 SG_ ODIE_FUCID : 23|8@0+ (1,0) [0|255] ""  CGM3a_LS,MCTM_LS
 SG_ ODIE_EvID : 13|6@0+ (1,0) [0|63] ""  CGM3a_LS,MCTM_LS

BO_TX_BU_ 2158878720 : MCTM_LS,CGM3a_LS;
BO_TX_BU_ 2155266048 : BCM_LS,ECC_LS;
BO_TX_BU_ 2151317504 : EOCM2cp_K2_LS,UPA_LS;
BO_TX_BU_ 2158796800 : CGM3a_LS,EOCM2cp_K2_LS,UPA_LS,BCM_LS,ECC_LS;
BO_TX_BU_ 2158755840 : BCM_LS,CGM3a_LS,ECC_LS;
CM_ BO_ 2158878720 "LAP: Signalerna är inte riktigt kodade!!!        ODI";
CM_ SG_ 2158878720 ODDLC_SubIdReqM "ODI-The number of list entries, starting at the Index, to send";
CM_ SG_ 2158878720 ODDLC_WrpArnd "ODI-Boolean that shall be set to true if the list shall wrap around.";
CM_ SG_ 2158878720 ODDLC_ReqType "ODI - Type of Request";
CM_ SG_ 2158878720 ODDLC_ReqDir "ODI-Boolean that shall be set to true if req down, set to false if set to up";
CM_ SG_ 2158878720 ODDLC_NmEntries "ODI-The number of list entries, starting at the Index, to send";
CM_ SG_ 2158878720 ODDLC_Idx "ODI-The index within the remote FU’s list at which to start sending data";
CM_ SG_ 2158878720 ODDLC_FUCID "ODI - Primary ID of Functional Unit in FU Database";
CM_ SG_ 2158878720 ODDLC_DspMID "ODI - ID that identifies the display requesting the data.  See detailed requirements in ODI GMLAN Protocol.";
CM_ SG_ 2158878720 ODDLC_DataId "ODI-Data Id for the dynamic list";
CM_ SG_ 2158878720 ODDLC_BckgndFlag "ODI-Informs FU as to priority of response.
Applies to all DataIds in the message.
$0=Immediate response required
$1=Background response";
CM_ SG_ 2151112704 FrPsSeatOccSnsOpMd "TBD";
CM_ SG_ 2151112704 FrPsSeatOccFltSt "TBD";
CM_ SG_ 2155167744 NRmtDtdPsBrkRstIO "Used to display notification to the driver that they do not have the fob in the vehicle when they pressed the off button.  Gives the driver a chance to obtain the fob before shutting off the car.";
CM_ SG_ 2151317504 PARrRgn4ObjStat "Regions are segments across the width of the vehicle (X coordinate).  Zones are distances from the vehicle (Y coordinate).";
CM_ SG_ 2151317504 PARrRgn3ObjStat "Regions are segments across the width of the vehicle (X coordinate).  Zones are distances from the vehicle (Y coordinate).";
CM_ SG_ 2151317504 PARrRgn2ObjStat "Regions are segments across the width of the vehicle (X coordinate).  Zones are distances from the vehicle (Y coordinate).";
CM_ SG_ 2151317504 PARrRgn1ObjStat "Regions are segments across the width of the vehicle (X coordinate).  Zones are distances from the vehicle (Y coordinate).";
CM_ SG_ 2151301120 PAFrtRgn4ObjStat "Regions are segments across the width of the vehicle (X coordinate).  Zones are distances from the vehicle (Y coordinate).";
CM_ SG_ 2151301120 PAFrtRgn3ObjStat "Regions are segments across the width of the vehicle (X coordinate).  Zones are distances from the vehicle (Y coordinate).";
CM_ SG_ 2151301120 PAFrtRgn2ObjStat "Regions are segments across the width of the vehicle (X coordinate).  Zones are distances from the vehicle (Y coordinate).";
CM_ SG_ 2151301120 PAFrtRgn1ObjStat "Regions are segments across the width of the vehicle (X coordinate).  Zones are distances from the vehicle (Y coordinate).";
CM_ BO_ 2153807872 "LAP: Open Switch ???";
CM_ BO_ 2154471424 "LAP: varför mappad i två olika VD'n?";
CM_ SG_ 2158796800 ODII_FUCID "ODI - Primary ID of Functional Unit in FU Database";
CM_ SG_ 2158755840 ODIE_FUCID "ODI - Primary ID of Functional Unit in FU Database";
CM_ SG_ 2158755840 ODIE_EvID "EventID within FUClass";
BA_DEF_ SG_  "VNSigPrimaryTriggering" ENUM  "No","Yes";
BA_DEF_ SG_  "VNSigRemoteDiagnostics" ENUM  "No","Yes";
BA_DEF_ SG_  "VNSigInfotainment" ENUM  "No","Yes";
BA_DEF_ SG_  "VNSigParkedVehicle" ENUM  "No","Yes";
BA_DEF_ SG_  "VNSigIntermediate" ENUM  "No","Yes";
BA_DEF_ SG_  "VNSigUnused_4" ENUM  "No","Yes";
BA_DEF_ SG_  "SignalType" STRING ;
BA_DEF_ SG_  "PacketOrder" INT 0 65535;
BA_DEF_ SG_  "SignalLongName" STRING ;
BA_DEF_ SG_  "GenSigStartValue" INT 0 65535;
BA_DEF_ SG_  "VNSigDiagnostic" ENUM  "No","Yes";
BA_DEF_ SG_  "VNSigAllNodes" ENUM  "No","Yes";
BA_DEF_ SG_  "GenSigDeltaValue" INT 0 0;
BA_DEF_ SG_  "GenSigSendType" ENUM  "not used","not used","not used","not used","not used","not used","not used","NoSigSendType","not used","not used","OnAnyChange","OnChangeIfActive","OnDelta";
BA_DEF_ SG_  "GenSigSendOnInit" ENUM  "Not Initialized","Application","Handler";
BA_DEF_ BO_  "AppGenMsgCycleTime" INT 0 0;
BA_DEF_ BO_  "TpTxIndex" INT 0 99;
BA_DEF_ BO_  "GenMsgILSupport" ENUM  "No","Yes";
BA_DEF_ BO_  "TpApplType" STRING ;
BA_DEF_ BO_  "Prio" INT 0 7;
BA_DEF_ BO_  "MessageSubnet" ENUM  "LS","HS","CE","PE","HV","FO","LE","HE2","PHS","PCE","DLCLS","DLCHS","DLCCE","DLCFO";
BA_DEF_ BO_  "GenMsgMandatoryToSupervision" ENUM  "No","Yes";
BA_DEF_ BO_  "DiagState" ENUM  "No","Yes";
BA_DEF_ BO_  "GenMsgStartDelayTime" INT 0 100000;
BA_DEF_ BO_  "GenMsgDelayTime" INT 0 100000;
BA_DEF_ BO_  "GenMsgCycleTime" INT 0 100000;
BA_DEF_ BO_  "GenMsgCycleTimeFast" INT 0 100000;
BA_DEF_ BO_  "GenMsgSendType" ENUM  "cyclicX","spontanX","cyclicIfActiveX","spontanWithDelay","cyclicAndSpontanX","cyclicAndSpontanWithDelay","spontanWithRepitition","cyclicIfActiveAndSpontanWD";
BA_DEF_ BO_  "DiagResponse" ENUM  "No","Yes";
BA_DEF_ BO_  "DiagRequest" ENUM  "No","Yes";
BA_DEF_ BO_  "NmMessage" ENUM  "No","Yes";
BA_DEF_REL_ BU_SG_REL_  "GenSigSuprvRespComment" STRING ;
BA_DEF_REL_ BU_SG_REL_  "GenSigVBitResp" ENUM  "No","Yes";
BA_DEF_REL_ BU_SG_REL_  "GenSigVBitRespComment" STRING ;
BA_DEF_REL_ BU_SG_REL_  "GenSigVDAFailComment" STRING ;
BA_DEF_REL_ BU_SG_REL_  "GenSigVDAFailResp" ENUM  "No","Yes";
BA_DEF_REL_ BU_SG_REL_  "GenSigRxStartValue" STRING ;
BA_DEF_REL_ BU_SG_REL_  "GenSigSuprvRespSubValue" INT 0 65535;
BA_DEF_REL_ BU_SG_REL_  "GenSigSuprvResp" ENUM  "None","Notify App","Substitute Default";
BA_DEF_REL_ BU_SG_REL_  "GenSigTimeoutMsg" HEX 0 268435455;
BA_DEF_REL_ BU_SG_REL_  "GenSigTimeoutTime" INT 0 15000;
BA_DEF_DEF_  "VNSigPrimaryTriggering" "No";
BA_DEF_DEF_  "VNSigRemoteDiagnostics" "No";
BA_DEF_DEF_  "VNSigInfotainment" "No";
BA_DEF_DEF_  "VNSigParkedVehicle" "No";
BA_DEF_DEF_  "VNSigIntermediate" "No";
BA_DEF_DEF_  "VNSigUnused_4" "No";
BA_DEF_DEF_  "SignalType" "";
BA_DEF_DEF_  "PacketOrder" 0;
BA_DEF_DEF_  "SignalLongName" "";
BA_DEF_DEF_  "GenSigStartValue" 0;
BA_DEF_DEF_  "VNSigDiagnostic" "No";
BA_DEF_DEF_  "VNSigAllNodes" "No";
BA_DEF_DEF_  "GenSigDeltaValue" 0;
BA_DEF_DEF_  "GenSigSendType" "NoSigSendType";
BA_DEF_DEF_  "GenSigSendOnInit" "Not Initialized";
BA_DEF_DEF_  "AppGenMsgCycleTime" 0;
BA_DEF_DEF_  "TpTxIndex" 0;
BA_DEF_DEF_  "GenMsgILSupport" "Yes";
BA_DEF_DEF_  "TpApplType" "";
BA_DEF_DEF_  "Prio" 4;
BA_DEF_DEF_  "MessageSubnet" "LS";
BA_DEF_DEF_  "GenMsgMandatoryToSupervision" "No";
BA_DEF_DEF_  "DiagState" "No";
BA_DEF_DEF_  "GenMsgStartDelayTime" 0;
BA_DEF_DEF_  "GenMsgDelayTime" 0;
BA_DEF_DEF_  "GenMsgCycleTime" 0;
BA_DEF_DEF_  "GenMsgCycleTimeFast" 0;
BA_DEF_DEF_  "GenMsgSendType" "spontanX";
BA_DEF_DEF_  "DiagResponse" "No";
BA_DEF_DEF_  "DiagRequest" "No";
BA_DEF_DEF_  "NmMessage" "No";
BA_DEF_DEF_REL_ "GenSigSuprvRespComment" "";
BA_DEF_DEF_REL_ "GenSigVBitResp" "No";
BA_DEF_DEF_REL_ "GenSigVBitRespComment" "";
BA_DEF_DEF_REL_ "GenSigVDAFailComment" "";
BA_DEF_DEF_REL_ "GenSigVDAFailResp" "No";
BA_DEF_DEF_REL_ "GenSigRxStartValue" "";
BA_DEF_DEF_REL_ "GenSigSuprvRespSubValue" 0;
BA_DEF_DEF_REL_ "GenSigSuprvResp" "None";
BA_DEF_DEF_REL_ "GenSigTimeoutMsg" 0;
BA_DEF_DEF_REL_ "GenSigTimeoutTime" 0;
BA_ "GenMsgStartDelayTime" BO_ 2149769216 130;
BA_ "GenMsgCycleTime" BO_ 2149769216 200;
BA_ "GenMsgSendType" BO_ 2149769216 0;
BA_ "GenMsgDelayTime" BO_ 2156789760 100;
BA_ "GenMsgStartDelayTime" BO_ 2150432768 150;
BA_ "GenMsgCycleTime" BO_ 2150432768 500;
BA_ "GenMsgSendType" BO_ 2150432768 0;
BA_ "GenMsgDelayTime" BO_ 2155298816 100;
BA_ "GenMsgDelayTime" BO_ 2158878720 20;
BA_ "GenMsgDelayTime" BO_ 2151112704 100;
BA_ "GenMsgILSupport" BO_ 1367 0;
BA_ "TpApplType" BO_ 1367 "DiagUUDTResponse";
BA_ "Prio" BO_ 1367 0;
BA_ "GenMsgDelayTime" BO_ 2153947136 100;
BA_ "GenMsgDelayTime" BO_ 2153938944 100;
BA_ "Prio" BO_ 2028 0;
BA_ "DiagResponse" BO_ 2028 1;
BA_ "GenMsgDelayTime" BO_ 2150662144 100;
BA_ "GenMsgDelayTime" BO_ 2150653952 100;
BA_ "GenMsgDelayTime" BO_ 2150850560 100;
BA_ "GenMsgDelayTime" BO_ 2154938368 100;
BA_ "GenMsgDelayTime" BO_ 2155266048 100;
BA_ "GenMsgDelayTime" BO_ 2155249664 100;
BA_ "GenMsgDelayTime" BO_ 2155184128 100;
BA_ "GenMsgDelayTime" BO_ 2155167744 100;
BA_ "Prio" BO_ 2154921984 3;
BA_ "GenMsgDelayTime" BO_ 2154921984 100;
BA_ "GenMsgDelayTime" BO_ 2151317504 100;
BA_ "GenMsgDelayTime" BO_ 2151301120 100;
BA_ "GenMsgDelayTime" BO_ 2153922560 100;
BA_ "Prio" BO_ 2153807872 3;
BA_ "GenMsgDelayTime" BO_ 2153807872 100;
BA_ "GenMsgDelayTime" BO_ 2151399424 100;
BA_ "GenMsgILSupport" BO_ 1359 0;
BA_ "TpApplType" BO_ 1359 "DiagUUDTResponse";
BA_ "Prio" BO_ 1359 0;
BA_ "GenMsgCycleTime" BO_ 2154733568 250;
BA_ "GenMsgSendType" BO_ 2154733568 0;
BA_ "GenMsgDelayTime" BO_ 2151342080 100;
BA_ "GenMsgDelayTime" BO_ 2151325696 100;
BA_ "GenMsgDelayTime" BO_ 2151809024 100;
BA_ "GenMsgDelayTime" BO_ 2151858176 100;
BA_ "GenMsgDelayTime" BO_ 2150547456 100;
BA_ "GenMsgDelayTime" BO_ 2154708992 200;
BA_ "Prio" BO_ 2154471424 3;
BA_ "GenMsgDelayTime" BO_ 2154471424 100;
BA_ "GenMsgDelayTime" BO_ 2158796800 100;
BA_ "GenMsgDelayTime" BO_ 2158755840 100;
BA_ "SignalType" SG_ 2149769216 WRSLDWhlRotStatRst "BLN";
BA_ "PacketOrder" SG_ 2149769216 WRSLDWhlRotStatRst 3;
BA_ "SignalLongName" SG_ 2149769216 WRSLDWhlRotStatRst "Wheel Rotational Status Left Driven : Wheel Rotational Status Reset Occurred";
BA_ "VNSigAllNodes" SG_ 2149769216 WRSLDWhlRotStatRst 1;
BA_ "SignalType" SG_ 2149769216 WRSLDWhlDisTpRC "UNM";
BA_ "PacketOrder" SG_ 2149769216 WRSLDWhlDisTpRC 1;
BA_ "SignalLongName" SG_ 2149769216 WRSLDWhlDisTpRC "Wheel Rotational Status Left Driven : Wheel Distance Timestamp Rollover Counter";
BA_ "VNSigAllNodes" SG_ 2149769216 WRSLDWhlDisTpRC 1;
BA_ "SignalType" SG_ 2149769216 WRSLDSeqNum "UNM";
BA_ "PacketOrder" SG_ 2149769216 WRSLDSeqNum 2;
BA_ "SignalLongName" SG_ 2149769216 WRSLDSeqNum "Wheel Rotational Status Left Driven : Sequence Number";
BA_ "VNSigAllNodes" SG_ 2149769216 WRSLDSeqNum 1;
BA_ "SignalType" SG_ 2149769216 WRSLDWhlDistVal "ENM";
BA_ "PacketOrder" SG_ 2149769216 WRSLDWhlDistVal 4;
BA_ "SignalLongName" SG_ 2149769216 WRSLDWhlDistVal "Wheel Rotational Status Left Driven : Wheel Distance Validity";
BA_ "VNSigAllNodes" SG_ 2149769216 WRSLDWhlDistVal 1;
BA_ "SignalType" SG_ 2149769216 WRSLDWhlDistTmstm "UNM";
BA_ "PacketOrder" SG_ 2149769216 WRSLDWhlDistTmstm 6;
BA_ "SignalLongName" SG_ 2149769216 WRSLDWhlDistTmstm "Wheel Rotational Status Left Driven : Wheel Distance Timestamp";
BA_ "VNSigAllNodes" SG_ 2149769216 WRSLDWhlDistTmstm 1;
BA_ "SignalType" SG_ 2149769216 WRSLDWhlDistPlsCntr "UNM";
BA_ "PacketOrder" SG_ 2149769216 WRSLDWhlDistPlsCntr 5;
BA_ "SignalLongName" SG_ 2149769216 WRSLDWhlDistPlsCntr "Wheel Rotational Status Left Driven : Wheel Distance Pulse Counter";
BA_ "VNSigAllNodes" SG_ 2149769216 WRSLDWhlDistPlsCntr 1;
BA_ "SignalType" SG_ 2149769216 WRSRDWhlDisTpRC "UNM";
BA_ "PacketOrder" SG_ 2149769216 WRSRDWhlDisTpRC 1;
BA_ "SignalLongName" SG_ 2149769216 WRSRDWhlDisTpRC "Wheel Rotational Status Right Driven : Wheel Distance Timestamp Rollover Counter";
BA_ "VNSigAllNodes" SG_ 2149769216 WRSRDWhlDisTpRC 1;
BA_ "SignalType" SG_ 2149769216 WRSRDSeqNum "UNM";
BA_ "PacketOrder" SG_ 2149769216 WRSRDSeqNum 2;
BA_ "SignalLongName" SG_ 2149769216 WRSRDSeqNum "Wheel Rotational Status Right Driven : Sequence Number";
BA_ "VNSigAllNodes" SG_ 2149769216 WRSRDSeqNum 1;
BA_ "SignalType" SG_ 2149769216 WRSRDWhlRotStatRst "BLN";
BA_ "PacketOrder" SG_ 2149769216 WRSRDWhlRotStatRst 3;
BA_ "SignalLongName" SG_ 2149769216 WRSRDWhlRotStatRst "Wheel Rotational Status Right Driven : Wheel Rotational Status Reset Occurred";
BA_ "VNSigAllNodes" SG_ 2149769216 WRSRDWhlRotStatRst 1;
BA_ "SignalType" SG_ 2149769216 WRSRDWhlDistVal "ENM";
BA_ "PacketOrder" SG_ 2149769216 WRSRDWhlDistVal 4;
BA_ "SignalLongName" SG_ 2149769216 WRSRDWhlDistVal "Wheel Rotational Status Right Driven : Wheel Distance Validity";
BA_ "VNSigAllNodes" SG_ 2149769216 WRSRDWhlDistVal 1;
BA_ "SignalType" SG_ 2149769216 WRSRDWhlDistTmstm "UNM";
BA_ "PacketOrder" SG_ 2149769216 WRSRDWhlDistTmstm 6;
BA_ "SignalLongName" SG_ 2149769216 WRSRDWhlDistTmstm "Wheel Rotational Status Right Driven : Wheel Distance Timestamp";
BA_ "VNSigAllNodes" SG_ 2149769216 WRSRDWhlDistTmstm 1;
BA_ "SignalType" SG_ 2149769216 WRSRDWhlDistPlsCntr "UNM";
BA_ "PacketOrder" SG_ 2149769216 WRSRDWhlDistPlsCntr 5;
BA_ "SignalLongName" SG_ 2149769216 WRSRDWhlDistPlsCntr "Wheel Rotational Status Right Driven : Wheel Distance Pulse Counter";
BA_ "VNSigAllNodes" SG_ 2149769216 WRSRDWhlDistPlsCntr 1;
BA_ "GenSigSendType" SG_ 2156789760 FrPedDetCsStReq 10;
BA_ "SignalType" SG_ 2156789760 FrPedDetCsStReq "ENM";
BA_ "SignalLongName" SG_ 2156789760 FrPedDetCsStReq "Front Pedestrian Detection Customization Setting Request";
BA_ "VNSigAllNodes" SG_ 2156789760 FrPedDetCsStReq 1;
BA_ "GenSigSendType" SG_ 2156789760 SmrtHgBmAstCstSetReq 10;
BA_ "SignalType" SG_ 2156789760 SmrtHgBmAstCstSetReq "ENM";
BA_ "SignalLongName" SG_ 2156789760 SmrtHgBmAstCstSetReq "Smart High Beam Assist Customization Setting Request";
BA_ "VNSigAllNodes" SG_ 2156789760 SmrtHgBmAstCstSetReq 1;
BA_ "GenSigSendType" SG_ 2156789760 TimeDispFormat 10;
BA_ "GenSigSendOnInit" SG_ 2156789760 TimeDispFormat 1;
BA_ "VNSigInfotainment" SG_ 2156789760 TimeDispFormat 1;
BA_ "SignalType" SG_ 2156789760 TimeDispFormat "ENM";
BA_ "SignalLongName" SG_ 2156789760 TimeDispFormat "Time Display Format";
BA_ "VNSigAllNodes" SG_ 2156789760 TimeDispFormat 1;
BA_ "GenSigDeltaValue" SG_ 2156789760 CldrYr 1;
BA_ "GenSigSendType" SG_ 2156789760 CldrYr 12;
BA_ "GenSigSendOnInit" SG_ 2156789760 CldrYr 1;
BA_ "VNSigInfotainment" SG_ 2156789760 CldrYr 1;
BA_ "SignalType" SG_ 2156789760 CldrYr "UNM";
BA_ "SignalLongName" SG_ 2156789760 CldrYr "Calendar Year";
BA_ "VNSigAllNodes" SG_ 2156789760 CldrYr 1;
BA_ "GenSigSendType" SG_ 2156789760 CldrMth 10;
BA_ "GenSigSendOnInit" SG_ 2156789760 CldrMth 1;
BA_ "VNSigInfotainment" SG_ 2156789760 CldrMth 1;
BA_ "SignalType" SG_ 2156789760 CldrMth "ENM";
BA_ "SignalLongName" SG_ 2156789760 CldrMth "Calendar Month";
BA_ "VNSigAllNodes" SG_ 2156789760 CldrMth 1;
BA_ "GenSigDeltaValue" SG_ 2156789760 CldrDay 1;
BA_ "GenSigSendType" SG_ 2156789760 CldrDay 12;
BA_ "GenSigSendOnInit" SG_ 2156789760 CldrDay 1;
BA_ "VNSigInfotainment" SG_ 2156789760 CldrDay 1;
BA_ "SignalType" SG_ 2156789760 CldrDay "UNM";
BA_ "SignalLongName" SG_ 2156789760 CldrDay "Calendar Day";
BA_ "VNSigAllNodes" SG_ 2156789760 CldrDay 1;
BA_ "GenSigDeltaValue" SG_ 2156789760 TOD_SecofMin 1;
BA_ "GenSigSendType" SG_ 2156789760 TOD_SecofMin 12;
BA_ "GenSigSendOnInit" SG_ 2156789760 TOD_SecofMin 1;
BA_ "VNSigInfotainment" SG_ 2156789760 TOD_SecofMin 1;
BA_ "SignalType" SG_ 2156789760 TOD_SecofMin "UNM";
BA_ "PacketOrder" SG_ 2156789760 TOD_SecofMin 3;
BA_ "SignalLongName" SG_ 2156789760 TOD_SecofMin "Time of Day : Seconds of Minute";
BA_ "VNSigAllNodes" SG_ 2156789760 TOD_SecofMin 1;
BA_ "GenSigDeltaValue" SG_ 2156789760 TOD_MinofHr 1;
BA_ "GenSigSendType" SG_ 2156789760 TOD_MinofHr 12;
BA_ "GenSigSendOnInit" SG_ 2156789760 TOD_MinofHr 1;
BA_ "VNSigInfotainment" SG_ 2156789760 TOD_MinofHr 1;
BA_ "SignalType" SG_ 2156789760 TOD_MinofHr "UNM";
BA_ "PacketOrder" SG_ 2156789760 TOD_MinofHr 2;
BA_ "SignalLongName" SG_ 2156789760 TOD_MinofHr "Time of Day : Minute of Hour";
BA_ "VNSigAllNodes" SG_ 2156789760 TOD_MinofHr 1;
BA_ "GenSigDeltaValue" SG_ 2156789760 TOD_HrofDay 1;
BA_ "GenSigSendType" SG_ 2156789760 TOD_HrofDay 12;
BA_ "GenSigSendOnInit" SG_ 2156789760 TOD_HrofDay 1;
BA_ "VNSigInfotainment" SG_ 2156789760 TOD_HrofDay 1;
BA_ "SignalType" SG_ 2156789760 TOD_HrofDay "UNM";
BA_ "PacketOrder" SG_ 2156789760 TOD_HrofDay 1;
BA_ "SignalLongName" SG_ 2156789760 TOD_HrofDay "Time of Day : Hour of Day";
BA_ "VNSigAllNodes" SG_ 2156789760 TOD_HrofDay 1;
BA_ "SignalType" SG_ 2150432768 EngManfldAirTempCrtdV "ENM";
BA_ "SignalLongName" SG_ 2150432768 EngManfldAirTempCrtdV "Engine Manifold Air Temperature Corrected Validity";
BA_ "VNSigAllNodes" SG_ 2150432768 EngManfldAirTempCrtdV 1;
BA_ "SignalType" SG_ 2150432768 GrdBrkgAct "BLN";
BA_ "SignalLongName" SG_ 2150432768 GrdBrkgAct "Grade Braking Active";
BA_ "VNSigAllNodes" SG_ 2150432768 GrdBrkgAct 1;
BA_ "SignalType" SG_ 2150432768 EngManfldAirTempCrtd "UNM";
BA_ "SignalLongName" SG_ 2150432768 EngManfldAirTempCrtd "Engine Manifold Air Temperature Corrected";
BA_ "VNSigAllNodes" SG_ 2150432768 EngManfldAirTempCrtd 1;
BA_ "SignalType" SG_ 2150432768 FuelFltLifRstPerf "BLN";
BA_ "SignalLongName" SG_ 2150432768 FuelFltLifRstPerf "Fuel Filter Life Reset Performed";
BA_ "VNSigAllNodes" SG_ 2150432768 FuelFltLifRstPerf 1;
BA_ "SignalType" SG_ 2150432768 FuelFltRmnLf "UNM";
BA_ "SignalLongName" SG_ 2150432768 FuelFltRmnLf "Fuel Filter Remaining Life";
BA_ "VNSigAllNodes" SG_ 2150432768 FuelFltRmnLf 1;
BA_ "SignalType" SG_ 2150432768 EngShtdwnPndgIO "BLN";
BA_ "SignalLongName" SG_ 2150432768 EngShtdwnPndgIO "Engine Shutdown Pending Indication On";
BA_ "VNSigAllNodes" SG_ 2150432768 EngShtdwnPndgIO 1;
BA_ "SignalType" SG_ 2150432768 GenFldDutCycV "ENM";
BA_ "SignalLongName" SG_ 2150432768 GenFldDutCycV "Generator Field Duty Cycle Validity";
BA_ "VNSigAllNodes" SG_ 2150432768 GenFldDutCycV 1;
BA_ "SignalType" SG_ 2150432768 GenFldDutCyc "UNM";
BA_ "SignalLongName" SG_ 2150432768 GenFldDutCyc "Generator Field Duty Cycle";
BA_ "VNSigAllNodes" SG_ 2150432768 GenFldDutCyc 1;
BA_ "GenSigSendOnInit" SG_ 2150432768 FuelTotCap 1;
BA_ "SignalType" SG_ 2150432768 FuelTotCap "UNM";
BA_ "SignalLongName" SG_ 2150432768 FuelTotCap "Fuel Total Capacity";
BA_ "VNSigAllNodes" SG_ 2150432768 FuelTotCap 1;
BA_ "SignalType" SG_ 2150432768 TransOilTempSensPres "BLN";
BA_ "SignalLongName" SG_ 2150432768 TransOilTempSensPres "Transmission Oil Temperature Sensor Present";
BA_ "VNSigAllNodes" SG_ 2150432768 TransOilTempSensPres 1;
BA_ "SignalType" SG_ 2150432768 TrnsNEmsRltMalfActv "BLN";
BA_ "SignalLongName" SG_ 2150432768 TrnsNEmsRltMalfActv "Transmission Non Emissions Related Malfunction Active";
BA_ "VNSigAllNodes" SG_ 2150432768 TrnsNEmsRltMalfActv 1;
BA_ "SignalType" SG_ 2150432768 TrnEmsMlfAtv "BLN";
BA_ "SignalLongName" SG_ 2150432768 TrnEmsMlfAtv "Transmission Emissions Related Malfunction Active";
BA_ "VNSigAllNodes" SG_ 2150432768 TrnEmsMlfAtv 1;
BA_ "SignalType" SG_ 2150432768 EngOilRmnLf "UNM";
BA_ "SignalLongName" SG_ 2150432768 EngOilRmnLf "Engine Oil Remaining Life";
BA_ "VNSigAllNodes" SG_ 2150432768 EngOilRmnLf 1;
BA_ "SignalType" SG_ 2150432768 TrnsThrmlMngmntStat "ENM";
BA_ "SignalLongName" SG_ 2150432768 TrnsThrmlMngmntStat "Transmission Thermal Management Status";
BA_ "VNSigAllNodes" SG_ 2150432768 TrnsThrmlMngmntStat 1;
BA_ "SignalType" SG_ 2150432768 PTHiElecLdReqd "BLN";
BA_ "SignalLongName" SG_ 2150432768 PTHiElecLdReqd "Powertrain High Electrical Load Requested";
BA_ "VNSigAllNodes" SG_ 2150432768 PTHiElecLdReqd 1;
BA_ "GenSigSendType" SG_ 2155298816 TrPrsMntrTrLdRstRqstd 10;
BA_ "SignalType" SG_ 2155298816 TrPrsMntrTrLdRstRqstd "ENM";
BA_ "SignalLongName" SG_ 2155298816 TrPrsMntrTrLdRstRqstd "Tire Pressure Monitoring Tire Loading Reset Requested";
BA_ "VNSigAllNodes" SG_ 2155298816 TrPrsMntrTrLdRstRqstd 1;
BA_ "GenSigSendType" SG_ 2155298816 TrPrsSnsProgEvntRqd 10;
BA_ "GenSigSendOnInit" SG_ 2155298816 TrPrsSnsProgEvntRqd 2;
BA_ "SignalType" SG_ 2155298816 TrPrsSnsProgEvntRqd "BLN";
BA_ "SignalLongName" SG_ 2155298816 TrPrsSnsProgEvntRqd "Tire Pressure Sensor Programming Event Requested";
BA_ "VNSigAllNodes" SG_ 2155298816 TrPrsSnsProgEvntRqd 1;
BA_ "GenSigDeltaValue" SG_ 2158878720 ODDLC_SubIdReqM 1;
BA_ "GenSigSendType" SG_ 2158878720 ODDLC_SubIdReqM 12;
BA_ "VNSigInfotainment" SG_ 2158878720 ODDLC_SubIdReqM 1;
BA_ "SignalType" SG_ 2158878720 ODDLC_SubIdReqM "UNM";
BA_ "PacketOrder" SG_ 2158878720 ODDLC_SubIdReqM 10;
BA_ "SignalLongName" SG_ 2158878720 ODDLC_SubIdReqM "Open Display Interface Dynamic Data List Request CenterStack : Sub Id Request Mask";
BA_ "VNSigAllNodes" SG_ 2158878720 ODDLC_SubIdReqM 1;
BA_ "GenSigSendType" SG_ 2158878720 ODDLC_WrpArnd 10;
BA_ "VNSigInfotainment" SG_ 2158878720 ODDLC_WrpArnd 1;
BA_ "SignalType" SG_ 2158878720 ODDLC_WrpArnd "BLN";
BA_ "PacketOrder" SG_ 2158878720 ODDLC_WrpArnd 9;
BA_ "SignalLongName" SG_ 2158878720 ODDLC_WrpArnd "Open Display Interface Dynamic Data List Request CenterStack : Wrap Around";
BA_ "VNSigAllNodes" SG_ 2158878720 ODDLC_WrpArnd 1;
BA_ "GenSigSendType" SG_ 2158878720 ODDLC_ReqType 10;
BA_ "VNSigInfotainment" SG_ 2158878720 ODDLC_ReqType 1;
BA_ "SignalType" SG_ 2158878720 ODDLC_ReqType "ENM";
BA_ "PacketOrder" SG_ 2158878720 ODDLC_ReqType 7;
BA_ "SignalLongName" SG_ 2158878720 ODDLC_ReqType "Open Display Interface Dynamic Data List Request CenterStack : Request Type";
BA_ "VNSigAllNodes" SG_ 2158878720 ODDLC_ReqType 1;
BA_ "GenSigSendType" SG_ 2158878720 ODDLC_ReqDir 10;
BA_ "VNSigInfotainment" SG_ 2158878720 ODDLC_ReqDir 1;
BA_ "SignalType" SG_ 2158878720 ODDLC_ReqDir "BLN";
BA_ "PacketOrder" SG_ 2158878720 ODDLC_ReqDir 5;
BA_ "SignalLongName" SG_ 2158878720 ODDLC_ReqDir "Open Display Interface Dynamic Data List Request CenterStack : Req Direction";
BA_ "VNSigAllNodes" SG_ 2158878720 ODDLC_ReqDir 1;
BA_ "GenSigDeltaValue" SG_ 2158878720 ODDLC_NmEntries 1;
BA_ "GenSigSendType" SG_ 2158878720 ODDLC_NmEntries 12;
BA_ "VNSigInfotainment" SG_ 2158878720 ODDLC_NmEntries 1;
BA_ "SignalType" SG_ 2158878720 ODDLC_NmEntries "UNM";
BA_ "PacketOrder" SG_ 2158878720 ODDLC_NmEntries 4;
BA_ "SignalLongName" SG_ 2158878720 ODDLC_NmEntries "Open Display Interface Dynamic Data List Request CenterStack : Num Entries";
BA_ "VNSigAllNodes" SG_ 2158878720 ODDLC_NmEntries 1;
BA_ "GenSigDeltaValue" SG_ 2158878720 ODDLC_Idx 1;
BA_ "GenSigSendType" SG_ 2158878720 ODDLC_Idx 12;
BA_ "VNSigInfotainment" SG_ 2158878720 ODDLC_Idx 1;
BA_ "SignalType" SG_ 2158878720 ODDLC_Idx "UNM";
BA_ "PacketOrder" SG_ 2158878720 ODDLC_Idx 6;
BA_ "SignalLongName" SG_ 2158878720 ODDLC_Idx "Open Display Interface Dynamic Data List Request CenterStack : Index";
BA_ "VNSigAllNodes" SG_ 2158878720 ODDLC_Idx 1;
BA_ "GenSigDeltaValue" SG_ 2158878720 ODDLC_FUCID 1;
BA_ "GenSigSendType" SG_ 2158878720 ODDLC_FUCID 12;
BA_ "VNSigInfotainment" SG_ 2158878720 ODDLC_FUCID 1;
BA_ "SignalType" SG_ 2158878720 ODDLC_FUCID "UNM";
BA_ "PacketOrder" SG_ 2158878720 ODDLC_FUCID 1;
BA_ "SignalLongName" SG_ 2158878720 ODDLC_FUCID "Open Display Interface Dynamic Data List Request CenterStack : Functional Unit Class ID";
BA_ "VNSigAllNodes" SG_ 2158878720 ODDLC_FUCID 1;
BA_ "GenSigSendType" SG_ 2158878720 ODDLC_DspMID 10;
BA_ "VNSigInfotainment" SG_ 2158878720 ODDLC_DspMID 1;
BA_ "SignalType" SG_ 2158878720 ODDLC_DspMID "ENM";
BA_ "PacketOrder" SG_ 2158878720 ODDLC_DspMID 3;
BA_ "SignalLongName" SG_ 2158878720 ODDLC_DspMID "Open Display Interface Dynamic Data List Request CenterStack : Display Mask Id";
BA_ "VNSigAllNodes" SG_ 2158878720 ODDLC_DspMID 1;
BA_ "GenSigDeltaValue" SG_ 2158878720 ODDLC_DataId 1;
BA_ "GenSigSendType" SG_ 2158878720 ODDLC_DataId 12;
BA_ "VNSigInfotainment" SG_ 2158878720 ODDLC_DataId 1;
BA_ "SignalType" SG_ 2158878720 ODDLC_DataId "UNM";
BA_ "PacketOrder" SG_ 2158878720 ODDLC_DataId 2;
BA_ "SignalLongName" SG_ 2158878720 ODDLC_DataId "Open Display Interface Dynamic Data List Request CenterStack : Data Id";
BA_ "VNSigAllNodes" SG_ 2158878720 ODDLC_DataId 1;
BA_ "GenSigSendType" SG_ 2158878720 ODDLC_BckgndFlag 10;
BA_ "VNSigInfotainment" SG_ 2158878720 ODDLC_BckgndFlag 1;
BA_ "SignalType" SG_ 2158878720 ODDLC_BckgndFlag "ENM";
BA_ "PacketOrder" SG_ 2158878720 ODDLC_BckgndFlag 8;
BA_ "SignalLongName" SG_ 2158878720 ODDLC_BckgndFlag "Open Display Interface Dynamic Data List Request CenterStack : Background Flag";
BA_ "VNSigAllNodes" SG_ 2158878720 ODDLC_BckgndFlag 1;
BA_ "GenSigSendType" SG_ 2151112704 FrPasSeatbltRemOccSt 10;
BA_ "GenSigSendOnInit" SG_ 2151112704 FrPasSeatbltRemOccSt 2;
BA_ "SignalType" SG_ 2151112704 FrPasSeatbltRemOccSt "ENM";
BA_ "SignalLongName" SG_ 2151112704 FrPasSeatbltRemOccSt "Front Passenger Seatbelt Reminder Occupancy Status";
BA_ "VNSigAllNodes" SG_ 2151112704 FrPasSeatbltRemOccSt 1;
BA_ "GenSigSendType" SG_ 2151112704 FrPasSeatResCtrlOccStV 10;
BA_ "GenSigSendOnInit" SG_ 2151112704 FrPasSeatResCtrlOccStV 2;
BA_ "SignalType" SG_ 2151112704 FrPasSeatResCtrlOccStV "ENM";
BA_ "SignalLongName" SG_ 2151112704 FrPasSeatResCtrlOccStV "Front Passenger Seat Restraint Control Occupancy Status Validity";
BA_ "VNSigAllNodes" SG_ 2151112704 FrPasSeatResCtrlOccStV 1;
BA_ "GenSigSendType" SG_ 2151112704 FrPasSeatResCtrlOccSt 10;
BA_ "GenSigSendOnInit" SG_ 2151112704 FrPasSeatResCtrlOccSt 2;
BA_ "SignalType" SG_ 2151112704 FrPasSeatResCtrlOccSt "ENM";
BA_ "SignalLongName" SG_ 2151112704 FrPasSeatResCtrlOccSt "Front Passenger Seat Restraint Control Occupancy Status";
BA_ "VNSigAllNodes" SG_ 2151112704 FrPasSeatResCtrlOccSt 1;
BA_ "GenSigSendType" SG_ 2151112704 FrPsSeatOccSnsOpMd 10;
BA_ "GenSigSendOnInit" SG_ 2151112704 FrPsSeatOccSnsOpMd 2;
BA_ "SignalType" SG_ 2151112704 FrPsSeatOccSnsOpMd "ENM";
BA_ "SignalLongName" SG_ 2151112704 FrPsSeatOccSnsOpMd "Front Passenger Seat Occupancy Sensing Operating Mode";
BA_ "VNSigAllNodes" SG_ 2151112704 FrPsSeatOccSnsOpMd 1;
BA_ "GenSigSendType" SG_ 2151112704 FrPsSeatOccFltSt 10;
BA_ "GenSigSendOnInit" SG_ 2151112704 FrPsSeatOccFltSt 2;
BA_ "SignalType" SG_ 2151112704 FrPsSeatOccFltSt "ENM";
BA_ "SignalLongName" SG_ 2151112704 FrPsSeatOccFltSt "Front Passenger Seat Occupancy Fault Status";
BA_ "VNSigAllNodes" SG_ 2151112704 FrPsSeatOccFltSt 1;
BA_ "GenSigSendType" SG_ 2151112704 FrntPassClass 10;
BA_ "GenSigSendOnInit" SG_ 2151112704 FrntPassClass 2;
BA_ "SignalType" SG_ 2151112704 FrntPassClass "ENM";
BA_ "SignalLongName" SG_ 2151112704 FrntPassClass "Front Passenger Classification";
BA_ "VNSigAllNodes" SG_ 2151112704 FrntPassClass 1;
BA_ "SignalType" SG_ 1367 DgnInf_LS557 "UNM";
BA_ "SignalLongName" SG_ 1367 DgnInf_LS557 "Diagnostic Information LS557";
BA_ "VNSigDiagnostic" SG_ 1367 DgnInf_LS557 1;
BA_ "VNSigAllNodes" SG_ 1367 DgnInf_LS557 1;
BA_ "GenSigSendType" SG_ 2153947136 RmtRflshMdAct 10;
BA_ "VNSigRemoteDiagnostics" SG_ 2153947136 RmtRflshMdAct 1;
BA_ "SignalType" SG_ 2153947136 RmtRflshMdAct "BLN";
BA_ "SignalLongName" SG_ 2153947136 RmtRflshMdAct "Remote Reflash Mode Active";
BA_ "VNSigAllNodes" SG_ 2153947136 RmtRflshMdAct 1;
BA_ "GenSigSendType" SG_ 2153938944 RmtRflshMdReqtd 10;
BA_ "VNSigRemoteDiagnostics" SG_ 2153938944 RmtRflshMdReqtd 1;
BA_ "SignalType" SG_ 2153938944 RmtRflshMdReqtd "BLN";
BA_ "SignalLongName" SG_ 2153938944 RmtRflshMdReqtd "Remote Reflash Mode Requested";
BA_ "VNSigAllNodes" SG_ 2153938944 RmtRflshMdReqtd 1;
BA_ "SignalType" SG_ 2028 DgnInf "UNM";
BA_ "SignalLongName" SG_ 2028 DgnInf "Diagnostic Information";
BA_ "VNSigDiagnostic" SG_ 2028 DgnInf 1;
BA_ "VNSigAllNodes" SG_ 2028 DgnInf 1;
BA_ "GenSigDeltaValue" SG_ 2150662144 EnvIdRsp3 1;
BA_ "GenSigSendType" SG_ 2150662144 EnvIdRsp3 12;
BA_ "SignalType" SG_ 2150662144 EnvIdRsp3 "UNM";
BA_ "SignalLongName" SG_ 2150662144 EnvIdRsp3 "Environment Identification Response 3";
BA_ "VNSigAllNodes" SG_ 2150662144 EnvIdRsp3 1;
BA_ "GenSigSendType" SG_ 2150662144 EnvIdRspSt3 10;
BA_ "SignalType" SG_ 2150662144 EnvIdRspSt3 "ENM";
BA_ "SignalLongName" SG_ 2150662144 EnvIdRspSt3 "Environment Identification Response Status 3";
BA_ "VNSigAllNodes" SG_ 2150662144 EnvIdRspSt3 1;
BA_ "GenSigSendType" SG_ 2150653952 EnvIdRspSt2 10;
BA_ "SignalType" SG_ 2150653952 EnvIdRspSt2 "ENM";
BA_ "SignalLongName" SG_ 2150653952 EnvIdRspSt2 "Environment Identification Response Status 2";
BA_ "VNSigAllNodes" SG_ 2150653952 EnvIdRspSt2 1;
BA_ "GenSigDeltaValue" SG_ 2150653952 EnvIdRsp2 1;
BA_ "GenSigSendType" SG_ 2150653952 EnvIdRsp2 12;
BA_ "SignalType" SG_ 2150653952 EnvIdRsp2 "UNM";
BA_ "SignalLongName" SG_ 2150653952 EnvIdRsp2 "Environment Identification Response 2";
BA_ "VNSigAllNodes" SG_ 2150653952 EnvIdRsp2 1;
BA_ "GenSigSendType" SG_ 2150850560 ScndRwRtPsSbltAtcV 10;
BA_ "GenSigSendOnInit" SG_ 2150850560 ScndRwRtPsSbltAtcV 2;
BA_ "SignalType" SG_ 2150850560 ScndRwRtPsSbltAtcV "ENM";
BA_ "SignalLongName" SG_ 2150850560 ScndRwRtPsSbltAtcV "Second Row Right Passenger Seatbelt Attached Validity";
BA_ "VNSigAllNodes" SG_ 2150850560 ScndRwRtPsSbltAtcV 1;
BA_ "GenSigSendType" SG_ 2150850560 ScndRwRtPsSbltAtc 10;
BA_ "GenSigSendOnInit" SG_ 2150850560 ScndRwRtPsSbltAtc 2;
BA_ "SignalType" SG_ 2150850560 ScndRwRtPsSbltAtc "BLN";
BA_ "SignalLongName" SG_ 2150850560 ScndRwRtPsSbltAtc "Second Row Right Passenger Seatbelt Attached";
BA_ "VNSigAllNodes" SG_ 2150850560 ScndRwRtPsSbltAtc 1;
BA_ "GenSigSendType" SG_ 2150850560 ScndRwCtrPsSbltAtcV 10;
BA_ "GenSigSendOnInit" SG_ 2150850560 ScndRwCtrPsSbltAtcV 2;
BA_ "SignalType" SG_ 2150850560 ScndRwCtrPsSbltAtcV "ENM";
BA_ "SignalLongName" SG_ 2150850560 ScndRwCtrPsSbltAtcV "Second Row Center Passenger Seatbelt Attached Validity";
BA_ "VNSigAllNodes" SG_ 2150850560 ScndRwCtrPsSbltAtcV 1;
BA_ "GenSigSendType" SG_ 2150850560 ScndRwCtrPsSbltAtc 10;
BA_ "GenSigSendOnInit" SG_ 2150850560 ScndRwCtrPsSbltAtc 2;
BA_ "SignalType" SG_ 2150850560 ScndRwCtrPsSbltAtc "BLN";
BA_ "SignalLongName" SG_ 2150850560 ScndRwCtrPsSbltAtc "Second Row Center Passenger Seatbelt Attached";
BA_ "VNSigAllNodes" SG_ 2150850560 ScndRwCtrPsSbltAtc 1;
BA_ "GenSigSendType" SG_ 2150850560 ScndRwLtPsSbltAtcV 10;
BA_ "GenSigSendOnInit" SG_ 2150850560 ScndRwLtPsSbltAtcV 2;
BA_ "SignalType" SG_ 2150850560 ScndRwLtPsSbltAtcV "ENM";
BA_ "SignalLongName" SG_ 2150850560 ScndRwLtPsSbltAtcV "Second Row Left Passenger Seatbelt Attached Validity";
BA_ "VNSigAllNodes" SG_ 2150850560 ScndRwLtPsSbltAtcV 1;
BA_ "GenSigSendType" SG_ 2150850560 ScndRwLtPsSbltAtc 10;
BA_ "GenSigSendOnInit" SG_ 2150850560 ScndRwLtPsSbltAtc 2;
BA_ "SignalType" SG_ 2150850560 ScndRwLtPsSbltAtc "BLN";
BA_ "SignalLongName" SG_ 2150850560 ScndRwLtPsSbltAtc "Second Row Left Passenger Seatbelt Attached";
BA_ "VNSigAllNodes" SG_ 2150850560 ScndRwLtPsSbltAtc 1;
BA_ "GenSigSendType" SG_ 2150850560 ScndRwRtPsOccStatV 10;
BA_ "GenSigSendOnInit" SG_ 2150850560 ScndRwRtPsOccStatV 2;
BA_ "SignalType" SG_ 2150850560 ScndRwRtPsOccStatV "ENM";
BA_ "SignalLongName" SG_ 2150850560 ScndRwRtPsOccStatV "Second Row Right Passenger Occupancy Status Validity";
BA_ "VNSigAllNodes" SG_ 2150850560 ScndRwRtPsOccStatV 1;
BA_ "GenSigSendType" SG_ 2150850560 ScndRwRtPsOccStat 10;
BA_ "GenSigSendOnInit" SG_ 2150850560 ScndRwRtPsOccStat 2;
BA_ "SignalType" SG_ 2150850560 ScndRwRtPsOccStat "ENM";
BA_ "SignalLongName" SG_ 2150850560 ScndRwRtPsOccStat "Second Row Right Passenger Occupancy Status";
BA_ "VNSigAllNodes" SG_ 2150850560 ScndRwRtPsOccStat 1;
BA_ "GenSigSendType" SG_ 2150850560 ScndRwLtPsOccStatV 10;
BA_ "GenSigSendOnInit" SG_ 2150850560 ScndRwLtPsOccStatV 2;
BA_ "SignalType" SG_ 2150850560 ScndRwLtPsOccStatV "ENM";
BA_ "SignalLongName" SG_ 2150850560 ScndRwLtPsOccStatV "Second Row Left Passenger Occupancy Status Validity";
BA_ "VNSigAllNodes" SG_ 2150850560 ScndRwLtPsOccStatV 1;
BA_ "GenSigSendType" SG_ 2150850560 ScndRwLtPsOccStat 10;
BA_ "GenSigSendOnInit" SG_ 2150850560 ScndRwLtPsOccStat 2;
BA_ "SignalType" SG_ 2150850560 ScndRwLtPsOccStat "ENM";
BA_ "SignalLongName" SG_ 2150850560 ScndRwLtPsOccStat "Second Row Left Passenger Occupancy Status";
BA_ "VNSigAllNodes" SG_ 2150850560 ScndRwLtPsOccStat 1;
BA_ "GenSigSendType" SG_ 2150850560 ScndRwCtrPsOccStatV 10;
BA_ "GenSigSendOnInit" SG_ 2150850560 ScndRwCtrPsOccStatV 2;
BA_ "SignalType" SG_ 2150850560 ScndRwCtrPsOccStatV "ENM";
BA_ "SignalLongName" SG_ 2150850560 ScndRwCtrPsOccStatV "Second Row Center Passenger Occupancy Status Validity";
BA_ "VNSigAllNodes" SG_ 2150850560 ScndRwCtrPsOccStatV 1;
BA_ "GenSigSendType" SG_ 2150850560 ScndRwCtrPsOccStat 10;
BA_ "GenSigSendOnInit" SG_ 2150850560 ScndRwCtrPsOccStat 2;
BA_ "SignalType" SG_ 2150850560 ScndRwCtrPsOccStat "ENM";
BA_ "SignalLongName" SG_ 2150850560 ScndRwCtrPsOccStat "Second Row Center Passenger Occupancy Status";
BA_ "VNSigAllNodes" SG_ 2150850560 ScndRwCtrPsOccStat 1;
BA_ "GenSigSendType" SG_ 2150850560 PsSbltAtcV 10;
BA_ "GenSigSendOnInit" SG_ 2150850560 PsSbltAtcV 2;
BA_ "SignalType" SG_ 2150850560 PsSbltAtcV "ENM";
BA_ "SignalLongName" SG_ 2150850560 PsSbltAtcV "Passenger Seatbelt Attached Validity";
BA_ "VNSigAllNodes" SG_ 2150850560 PsSbltAtcV 1;
BA_ "GenSigSendType" SG_ 2150850560 PsSbltAtc 10;
BA_ "GenSigSendOnInit" SG_ 2150850560 PsSbltAtc 2;
BA_ "SignalType" SG_ 2150850560 PsSbltAtc "BLN";
BA_ "SignalLongName" SG_ 2150850560 PsSbltAtc "Passenger Seatbelt Attached";
BA_ "VNSigAllNodes" SG_ 2150850560 PsSbltAtc 1;
BA_ "GenSigSendType" SG_ 2150850560 DrSbltAtcV 10;
BA_ "SignalType" SG_ 2150850560 DrSbltAtcV "ENM";
BA_ "SignalLongName" SG_ 2150850560 DrSbltAtcV "Driver Seatbelt Attached Validity";
BA_ "VNSigAllNodes" SG_ 2150850560 DrSbltAtcV 1;
BA_ "GenSigSendType" SG_ 2150850560 DrSbltAtc 10;
BA_ "SignalType" SG_ 2150850560 DrSbltAtc "BLN";
BA_ "SignalLongName" SG_ 2150850560 DrSbltAtc "Driver Seatbelt Attached";
BA_ "VNSigAllNodes" SG_ 2150850560 DrSbltAtc 1;
BA_ "GenSigSendType" SG_ 2154938368 FobProgMdStat 10;
BA_ "SignalType" SG_ 2154938368 FobProgMdStat "ENM";
BA_ "SignalLongName" SG_ 2154938368 FobProgMdStat "Fob Programming Mode Status";
BA_ "VNSigAllNodes" SG_ 2154938368 FobProgMdStat 1;
BA_ "GenSigSendType" SG_ 2155266048 RRHCSeatSw3Act 10;
BA_ "GenSigSendOnInit" SG_ 2155266048 RRHCSeatSw3Act 2;
BA_ "SignalType" SG_ 2155266048 RRHCSeatSw3Act "BLN";
BA_ "SignalLongName" SG_ 2155266048 RRHCSeatSw3Act "Rear Right Heated/Cooled Seat Switch #3 Active";
BA_ "VNSigAllNodes" SG_ 2155266048 RRHCSeatSw3Act 1;
BA_ "GenSigSendType" SG_ 2155266048 RRHCSeatSw2Act 10;
BA_ "GenSigSendOnInit" SG_ 2155266048 RRHCSeatSw2Act 2;
BA_ "SignalType" SG_ 2155266048 RRHCSeatSw2Act "BLN";
BA_ "SignalLongName" SG_ 2155266048 RRHCSeatSw2Act "Rear Right Heated/Cooled Seat Switch #2 Active";
BA_ "VNSigAllNodes" SG_ 2155266048 RRHCSeatSw2Act 1;
BA_ "GenSigSendType" SG_ 2155266048 RRHCSeatSw1Act 10;
BA_ "GenSigSendOnInit" SG_ 2155266048 RRHCSeatSw1Act 2;
BA_ "SignalType" SG_ 2155266048 RRHCSeatSw1Act "BLN";
BA_ "SignalLongName" SG_ 2155266048 RRHCSeatSw1Act "Rear Right Heated/Cooled Seat Switch #1 Active";
BA_ "VNSigAllNodes" SG_ 2155266048 RRHCSeatSw1Act 1;
BA_ "GenSigSendType" SG_ 2155266048 RLHCSeatSw3Act 10;
BA_ "GenSigSendOnInit" SG_ 2155266048 RLHCSeatSw3Act 2;
BA_ "SignalType" SG_ 2155266048 RLHCSeatSw3Act "BLN";
BA_ "SignalLongName" SG_ 2155266048 RLHCSeatSw3Act "Rear Left Heated/Cooled Seat Switch #3 Active";
BA_ "VNSigAllNodes" SG_ 2155266048 RLHCSeatSw3Act 1;
BA_ "GenSigSendType" SG_ 2155266048 RLHCSeatSw2Act 10;
BA_ "GenSigSendOnInit" SG_ 2155266048 RLHCSeatSw2Act 2;
BA_ "SignalType" SG_ 2155266048 RLHCSeatSw2Act "BLN";
BA_ "SignalLongName" SG_ 2155266048 RLHCSeatSw2Act "Rear Left Heated/Cooled Seat Switch #2 Active";
BA_ "VNSigAllNodes" SG_ 2155266048 RLHCSeatSw2Act 1;
BA_ "GenSigSendType" SG_ 2155266048 RLHCSeatSw1Act 10;
BA_ "GenSigSendOnInit" SG_ 2155266048 RLHCSeatSw1Act 2;
BA_ "SignalType" SG_ 2155266048 RLHCSeatSw1Act "BLN";
BA_ "SignalLongName" SG_ 2155266048 RLHCSeatSw1Act "Rear Left Heated/Cooled Seat Switch #1 Active";
BA_ "VNSigAllNodes" SG_ 2155266048 RLHCSeatSw1Act 1;
BA_ "GenSigSendType" SG_ 2155249664 RRHCSMInd3 10;
BA_ "GenSigSendOnInit" SG_ 2155249664 RRHCSMInd3 1;
BA_ "SignalType" SG_ 2155249664 RRHCSMInd3 "BLN";
BA_ "PacketOrder" SG_ 2155249664 RRHCSMInd3 4;
BA_ "SignalLongName" SG_ 2155249664 RRHCSMInd3 "Rear Right Heated/Cooled Seat Mode Indication Control : Seat Mode Indication 3";
BA_ "VNSigAllNodes" SG_ 2155249664 RRHCSMInd3 1;
BA_ "GenSigSendType" SG_ 2155249664 RRHCSMInd2 10;
BA_ "GenSigSendOnInit" SG_ 2155249664 RRHCSMInd2 1;
BA_ "SignalType" SG_ 2155249664 RRHCSMInd2 "BLN";
BA_ "PacketOrder" SG_ 2155249664 RRHCSMInd2 3;
BA_ "SignalLongName" SG_ 2155249664 RRHCSMInd2 "Rear Right Heated/Cooled Seat Mode Indication Control : Seat Mode Indication 2";
BA_ "VNSigAllNodes" SG_ 2155249664 RRHCSMInd2 1;
BA_ "GenSigSendType" SG_ 2155249664 RRHCSMInd1 10;
BA_ "GenSigSendOnInit" SG_ 2155249664 RRHCSMInd1 1;
BA_ "SignalType" SG_ 2155249664 RRHCSMInd1 "BLN";
BA_ "PacketOrder" SG_ 2155249664 RRHCSMInd1 2;
BA_ "SignalLongName" SG_ 2155249664 RRHCSMInd1 "Rear Right Heated/Cooled Seat Mode Indication Control : Seat Mode Indication 1";
BA_ "VNSigAllNodes" SG_ 2155249664 RRHCSMInd1 1;
BA_ "GenSigSendType" SG_ 2155249664 RRHCSMIndReq 10;
BA_ "GenSigSendOnInit" SG_ 2155249664 RRHCSMIndReq 1;
BA_ "SignalType" SG_ 2155249664 RRHCSMIndReq "ENM";
BA_ "PacketOrder" SG_ 2155249664 RRHCSMIndReq 1;
BA_ "SignalLongName" SG_ 2155249664 RRHCSMIndReq "Rear Right Heated/Cooled Seat Mode Indication Control : Indication Request";
BA_ "VNSigAllNodes" SG_ 2155249664 RRHCSMIndReq 1;
BA_ "GenSigSendType" SG_ 2155249664 RRHCSLSeatLev5 10;
BA_ "GenSigSendOnInit" SG_ 2155249664 RRHCSLSeatLev5 1;
BA_ "SignalType" SG_ 2155249664 RRHCSLSeatLev5 "BLN";
BA_ "PacketOrder" SG_ 2155249664 RRHCSLSeatLev5 6;
BA_ "SignalLongName" SG_ 2155249664 RRHCSLSeatLev5 "Rear Right Heated/Cooled Seat Level Indication Control : Seat Level 5";
BA_ "VNSigAllNodes" SG_ 2155249664 RRHCSLSeatLev5 1;
BA_ "GenSigSendType" SG_ 2155249664 RRHCSLSeatLev4 10;
BA_ "GenSigSendOnInit" SG_ 2155249664 RRHCSLSeatLev4 1;
BA_ "SignalType" SG_ 2155249664 RRHCSLSeatLev4 "BLN";
BA_ "PacketOrder" SG_ 2155249664 RRHCSLSeatLev4 5;
BA_ "SignalLongName" SG_ 2155249664 RRHCSLSeatLev4 "Rear Right Heated/Cooled Seat Level Indication Control : Seat Level 4";
BA_ "VNSigAllNodes" SG_ 2155249664 RRHCSLSeatLev4 1;
BA_ "GenSigSendType" SG_ 2155249664 RRHCSLSeatLev3 10;
BA_ "GenSigSendOnInit" SG_ 2155249664 RRHCSLSeatLev3 1;
BA_ "SignalType" SG_ 2155249664 RRHCSLSeatLev3 "BLN";
BA_ "PacketOrder" SG_ 2155249664 RRHCSLSeatLev3 4;
BA_ "SignalLongName" SG_ 2155249664 RRHCSLSeatLev3 "Rear Right Heated/Cooled Seat Level Indication Control : Seat Level 3";
BA_ "VNSigAllNodes" SG_ 2155249664 RRHCSLSeatLev3 1;
BA_ "GenSigSendType" SG_ 2155249664 RRHCSLSeatLev2 10;
BA_ "GenSigSendOnInit" SG_ 2155249664 RRHCSLSeatLev2 1;
BA_ "SignalType" SG_ 2155249664 RRHCSLSeatLev2 "BLN";
BA_ "PacketOrder" SG_ 2155249664 RRHCSLSeatLev2 3;
BA_ "SignalLongName" SG_ 2155249664 RRHCSLSeatLev2 "Rear Right Heated/Cooled Seat Level Indication Control : Seat Level 2";
BA_ "VNSigAllNodes" SG_ 2155249664 RRHCSLSeatLev2 1;
BA_ "GenSigSendType" SG_ 2155249664 RRHCSLSeatLev1 10;
BA_ "GenSigSendOnInit" SG_ 2155249664 RRHCSLSeatLev1 1;
BA_ "SignalType" SG_ 2155249664 RRHCSLSeatLev1 "BLN";
BA_ "PacketOrder" SG_ 2155249664 RRHCSLSeatLev1 2;
BA_ "SignalLongName" SG_ 2155249664 RRHCSLSeatLev1 "Rear Right Heated/Cooled Seat Level Indication Control : Seat Level 1";
BA_ "VNSigAllNodes" SG_ 2155249664 RRHCSLSeatLev1 1;
BA_ "GenSigSendType" SG_ 2155249664 RRHCSLIndReq 10;
BA_ "GenSigSendOnInit" SG_ 2155249664 RRHCSLIndReq 1;
BA_ "SignalType" SG_ 2155249664 RRHCSLIndReq "ENM";
BA_ "PacketOrder" SG_ 2155249664 RRHCSLIndReq 1;
BA_ "SignalLongName" SG_ 2155249664 RRHCSLIndReq "Rear Right Heated/Cooled Seat Level Indication Control : Indication Request";
BA_ "VNSigAllNodes" SG_ 2155249664 RRHCSLIndReq 1;
BA_ "GenSigSendType" SG_ 2155249664 RLHCSMInd3 10;
BA_ "GenSigSendOnInit" SG_ 2155249664 RLHCSMInd3 1;
BA_ "SignalType" SG_ 2155249664 RLHCSMInd3 "BLN";
BA_ "PacketOrder" SG_ 2155249664 RLHCSMInd3 4;
BA_ "SignalLongName" SG_ 2155249664 RLHCSMInd3 "Rear Left Heated/Cooled Seat Mode Indication Control : Seat Mode Indication 3";
BA_ "VNSigAllNodes" SG_ 2155249664 RLHCSMInd3 1;
BA_ "GenSigSendType" SG_ 2155249664 RLHCSMInd2 10;
BA_ "GenSigSendOnInit" SG_ 2155249664 RLHCSMInd2 1;
BA_ "SignalType" SG_ 2155249664 RLHCSMInd2 "BLN";
BA_ "PacketOrder" SG_ 2155249664 RLHCSMInd2 3;
BA_ "SignalLongName" SG_ 2155249664 RLHCSMInd2 "Rear Left Heated/Cooled Seat Mode Indication Control : Seat Mode Indication 2";
BA_ "VNSigAllNodes" SG_ 2155249664 RLHCSMInd2 1;
BA_ "GenSigSendType" SG_ 2155249664 RLHCSMInd1 10;
BA_ "GenSigSendOnInit" SG_ 2155249664 RLHCSMInd1 1;
BA_ "SignalType" SG_ 2155249664 RLHCSMInd1 "BLN";
BA_ "PacketOrder" SG_ 2155249664 RLHCSMInd1 2;
BA_ "SignalLongName" SG_ 2155249664 RLHCSMInd1 "Rear Left Heated/Cooled Seat Mode Indication Control : Seat Mode Indication 1";
BA_ "VNSigAllNodes" SG_ 2155249664 RLHCSMInd1 1;
BA_ "GenSigSendType" SG_ 2155249664 RLHCSMIndReq 10;
BA_ "GenSigSendOnInit" SG_ 2155249664 RLHCSMIndReq 1;
BA_ "SignalType" SG_ 2155249664 RLHCSMIndReq "ENM";
BA_ "PacketOrder" SG_ 2155249664 RLHCSMIndReq 1;
BA_ "SignalLongName" SG_ 2155249664 RLHCSMIndReq "Rear Left Heated/Cooled Seat Mode Indication Control : Indication Request";
BA_ "VNSigAllNodes" SG_ 2155249664 RLHCSMIndReq 1;
BA_ "GenSigSendType" SG_ 2155249664 RLHCSLSeatLev5 10;
BA_ "GenSigSendOnInit" SG_ 2155249664 RLHCSLSeatLev5 1;
BA_ "SignalType" SG_ 2155249664 RLHCSLSeatLev5 "BLN";
BA_ "PacketOrder" SG_ 2155249664 RLHCSLSeatLev5 6;
BA_ "SignalLongName" SG_ 2155249664 RLHCSLSeatLev5 "Rear Left Heated/Cooled Seat Level Indication Control : Seat Level 5";
BA_ "VNSigAllNodes" SG_ 2155249664 RLHCSLSeatLev5 1;
BA_ "GenSigSendType" SG_ 2155249664 RLHCSLSeatLev4 10;
BA_ "GenSigSendOnInit" SG_ 2155249664 RLHCSLSeatLev4 1;
BA_ "SignalType" SG_ 2155249664 RLHCSLSeatLev4 "BLN";
BA_ "PacketOrder" SG_ 2155249664 RLHCSLSeatLev4 5;
BA_ "SignalLongName" SG_ 2155249664 RLHCSLSeatLev4 "Rear Left Heated/Cooled Seat Level Indication Control : Seat Level 4";
BA_ "VNSigAllNodes" SG_ 2155249664 RLHCSLSeatLev4 1;
BA_ "GenSigSendType" SG_ 2155249664 RLHCSLSeatLev3 10;
BA_ "GenSigSendOnInit" SG_ 2155249664 RLHCSLSeatLev3 1;
BA_ "SignalType" SG_ 2155249664 RLHCSLSeatLev3 "BLN";
BA_ "PacketOrder" SG_ 2155249664 RLHCSLSeatLev3 4;
BA_ "SignalLongName" SG_ 2155249664 RLHCSLSeatLev3 "Rear Left Heated/Cooled Seat Level Indication Control : Seat Level 3";
BA_ "VNSigAllNodes" SG_ 2155249664 RLHCSLSeatLev3 1;
BA_ "GenSigSendType" SG_ 2155249664 RLHCSLSeatLev2 10;
BA_ "GenSigSendOnInit" SG_ 2155249664 RLHCSLSeatLev2 1;
BA_ "SignalType" SG_ 2155249664 RLHCSLSeatLev2 "BLN";
BA_ "PacketOrder" SG_ 2155249664 RLHCSLSeatLev2 3;
BA_ "SignalLongName" SG_ 2155249664 RLHCSLSeatLev2 "Rear Left Heated/Cooled Seat Level Indication Control : Seat Level 2";
BA_ "VNSigAllNodes" SG_ 2155249664 RLHCSLSeatLev2 1;
BA_ "GenSigSendType" SG_ 2155249664 RLHCSLSeatLev1 10;
BA_ "GenSigSendOnInit" SG_ 2155249664 RLHCSLSeatLev1 1;
BA_ "SignalType" SG_ 2155249664 RLHCSLSeatLev1 "BLN";
BA_ "PacketOrder" SG_ 2155249664 RLHCSLSeatLev1 2;
BA_ "SignalLongName" SG_ 2155249664 RLHCSLSeatLev1 "Rear Left Heated/Cooled Seat Level Indication Control : Seat Level 1";
BA_ "VNSigAllNodes" SG_ 2155249664 RLHCSLSeatLev1 1;
BA_ "GenSigSendType" SG_ 2155249664 RLHCSLIndReq 10;
BA_ "GenSigSendOnInit" SG_ 2155249664 RLHCSLIndReq 1;
BA_ "SignalType" SG_ 2155249664 RLHCSLIndReq "ENM";
BA_ "PacketOrder" SG_ 2155249664 RLHCSLIndReq 1;
BA_ "SignalLongName" SG_ 2155249664 RLHCSLIndReq "Rear Left Heated/Cooled Seat Level Indication Control : Indication Request";
BA_ "VNSigAllNodes" SG_ 2155249664 RLHCSLIndReq 1;
BA_ "GenSigSendType" SG_ 2155184128 IdlRecmndToClEngIO 10;
BA_ "SignalType" SG_ 2155184128 IdlRecmndToClEngIO "BLN";
BA_ "SignalLongName" SG_ 2155184128 IdlRecmndToClEngIO "Idle Recommended to Cool Engine Indication On";
BA_ "VNSigAllNodes" SG_ 2155184128 IdlRecmndToClEngIO 1;
BA_ "GenSigSendType" SG_ 2155184128 RrStRmndrIO 10;
BA_ "GenSigSendOnInit" SG_ 2155184128 RrStRmndrIO 2;
BA_ "SignalType" SG_ 2155184128 RrStRmndrIO "BLN";
BA_ "SignalLongName" SG_ 2155184128 RrStRmndrIO "Rear Seat Reminder Indication On";
BA_ "VNSigAllNodes" SG_ 2155184128 RrStRmndrIO 1;
BA_ "GenSigSendType" SG_ 2155184128 RrStRmndrCstCurrSetVal 10;
BA_ "GenSigSendOnInit" SG_ 2155184128 RrStRmndrCstCurrSetVal 2;
BA_ "SignalType" SG_ 2155184128 RrStRmndrCstCurrSetVal "ENM";
BA_ "SignalLongName" SG_ 2155184128 RrStRmndrCstCurrSetVal "Rear Seat Reminder Customization Current Setting Value";
BA_ "VNSigAllNodes" SG_ 2155184128 RrStRmndrCstCurrSetVal 1;
BA_ "GenSigSendType" SG_ 2155184128 RrStRmndrCstSetAvail 10;
BA_ "GenSigSendOnInit" SG_ 2155184128 RrStRmndrCstSetAvail 2;
BA_ "SignalType" SG_ 2155184128 RrStRmndrCstSetAvail "BLN";
BA_ "SignalLongName" SG_ 2155184128 RrStRmndrCstSetAvail "Rear Seat Reminder Customization Setting Available";
BA_ "VNSigAllNodes" SG_ 2155184128 RrStRmndrCstSetAvail 1;
BA_ "GenSigSendType" SG_ 2155184128 SmPhRmFunCstStAval 10;
BA_ "GenSigSendOnInit" SG_ 2155184128 SmPhRmFunCstStAval 2;
BA_ "VNSigInfotainment" SG_ 2155184128 SmPhRmFunCstStAval 1;
BA_ "SignalType" SG_ 2155184128 SmPhRmFunCstStAval "BLN";
BA_ "SignalLongName" SG_ 2155184128 SmPhRmFunCstStAval "Smart Phone Remote Function Customization Setting Available";
BA_ "VNSigAllNodes" SG_ 2155184128 SmPhRmFunCstStAval 1;
BA_ "GenSigSendType" SG_ 2155184128 SmPhRmFunCstCurStVal 10;
BA_ "GenSigSendOnInit" SG_ 2155184128 SmPhRmFunCstCurStVal 2;
BA_ "VNSigInfotainment" SG_ 2155184128 SmPhRmFunCstCurStVal 1;
BA_ "SignalType" SG_ 2155184128 SmPhRmFunCstCurStVal "ENM";
BA_ "SignalLongName" SG_ 2155184128 SmPhRmFunCstCurStVal "Smart Phone Remote Function Customization Current Setting Value";
BA_ "VNSigAllNodes" SG_ 2155184128 SmPhRmFunCstCurStVal 1;
BA_ "GenSigSendType" SG_ 2155184128 TrnsShftLvrLckStat 10;
BA_ "SignalType" SG_ 2155184128 TrnsShftLvrLckStat "ENM";
BA_ "SignalLongName" SG_ 2155184128 TrnsShftLvrLckStat "Transmission Shift Lever Lock Status";
BA_ "VNSigAllNodes" SG_ 2155184128 TrnsShftLvrLckStat 1;
BA_ "GenSigSendType" SG_ 2155184128 CrsSpdLmtrSwStat 10;
BA_ "SignalType" SG_ 2155184128 CrsSpdLmtrSwStat "ENM";
BA_ "SignalLongName" SG_ 2155184128 CrsSpdLmtrSwStat "Cruise and Speed Limiter Switch Status";
BA_ "VNSigAllNodes" SG_ 2155184128 CrsSpdLmtrSwStat 1;
BA_ "GenSigSendType" SG_ 2155184128 CrsCntrlSwStCanSwAct 10;
BA_ "GenSigSendOnInit" SG_ 2155184128 CrsCntrlSwStCanSwAct 2;
BA_ "SignalType" SG_ 2155184128 CrsCntrlSwStCanSwAct "BLN";
BA_ "PacketOrder" SG_ 2155184128 CrsCntrlSwStCanSwAct 1;
BA_ "SignalLongName" SG_ 2155184128 CrsCntrlSwStCanSwAct "Cruise Control Switch Status : Cancel Switch Active";
BA_ "VNSigAllNodes" SG_ 2155184128 CrsCntrlSwStCanSwAct 1;
BA_ "GenSigSendType" SG_ 2155184128 CrsCntrlSwStSwDataIntgty 10;
BA_ "GenSigSendOnInit" SG_ 2155184128 CrsCntrlSwStSwDataIntgty 2;
BA_ "SignalType" SG_ 2155184128 CrsCntrlSwStSwDataIntgty "ENM";
BA_ "PacketOrder" SG_ 2155184128 CrsCntrlSwStSwDataIntgty 7;
BA_ "SignalLongName" SG_ 2155184128 CrsCntrlSwStSwDataIntgty "Cruise Control Switch Status : Switch Data Integrity";
BA_ "VNSigAllNodes" SG_ 2155184128 CrsCntrlSwStSwDataIntgty 1;
BA_ "GenSigSendType" SG_ 2155184128 CrsCntrlSwStSpdInSwAct 10;
BA_ "GenSigSendOnInit" SG_ 2155184128 CrsCntrlSwStSpdInSwAct 2;
BA_ "SignalType" SG_ 2155184128 CrsCntrlSwStSpdInSwAct "BLN";
BA_ "PacketOrder" SG_ 2155184128 CrsCntrlSwStSpdInSwAct 5;
BA_ "SignalLongName" SG_ 2155184128 CrsCntrlSwStSpdInSwAct "Cruise Control Switch Status : Speed Increase Switch Active";
BA_ "VNSigAllNodes" SG_ 2155184128 CrsCntrlSwStSpdInSwAct 1;
BA_ "GenSigSendType" SG_ 2155184128 CrsCntrlSwStSpDcSwAct 10;
BA_ "GenSigSendOnInit" SG_ 2155184128 CrsCntrlSwStSpDcSwAct 2;
BA_ "SignalType" SG_ 2155184128 CrsCntrlSwStSpDcSwAct "BLN";
BA_ "PacketOrder" SG_ 2155184128 CrsCntrlSwStSpDcSwAct 6;
BA_ "SignalLongName" SG_ 2155184128 CrsCntrlSwStSpDcSwAct "Cruise Control Switch Status : Speed Decrease Switch Active";
BA_ "VNSigAllNodes" SG_ 2155184128 CrsCntrlSwStSpDcSwAct 1;
BA_ "GenSigSendType" SG_ 2155184128 CrsCntrlSwStSetSwAct 10;
BA_ "GenSigSendOnInit" SG_ 2155184128 CrsCntrlSwStSetSwAct 2;
BA_ "SignalType" SG_ 2155184128 CrsCntrlSwStSetSwAct "BLN";
BA_ "PacketOrder" SG_ 2155184128 CrsCntrlSwStSetSwAct 4;
BA_ "SignalLongName" SG_ 2155184128 CrsCntrlSwStSetSwAct "Cruise Control Switch Status : Set Switch Active";
BA_ "VNSigAllNodes" SG_ 2155184128 CrsCntrlSwStSetSwAct 1;
BA_ "GenSigSendType" SG_ 2155184128 CrsCntrlSwStResSwAct 10;
BA_ "GenSigSendOnInit" SG_ 2155184128 CrsCntrlSwStResSwAct 2;
BA_ "SignalType" SG_ 2155184128 CrsCntrlSwStResSwAct "BLN";
BA_ "PacketOrder" SG_ 2155184128 CrsCntrlSwStResSwAct 3;
BA_ "SignalLongName" SG_ 2155184128 CrsCntrlSwStResSwAct "Cruise Control Switch Status : Resume Switch Active";
BA_ "VNSigAllNodes" SG_ 2155184128 CrsCntrlSwStResSwAct 1;
BA_ "GenSigSendType" SG_ 2155184128 CrsCntrlSwStOnSwAct 10;
BA_ "GenSigSendOnInit" SG_ 2155184128 CrsCntrlSwStOnSwAct 2;
BA_ "SignalType" SG_ 2155184128 CrsCntrlSwStOnSwAct "BLN";
BA_ "PacketOrder" SG_ 2155184128 CrsCntrlSwStOnSwAct 2;
BA_ "SignalLongName" SG_ 2155184128 CrsCntrlSwStOnSwAct "Cruise Control Switch Status : On Switch Active";
BA_ "VNSigAllNodes" SG_ 2155184128 CrsCntrlSwStOnSwAct 1;
BA_ "GenSigSendType" SG_ 2155184128 CrsCntAtv 10;
BA_ "GenSigSendOnInit" SG_ 2155184128 CrsCntAtv 2;
BA_ "SignalType" SG_ 2155184128 CrsCntAtv "BLN";
BA_ "SignalLongName" SG_ 2155184128 CrsCntAtv "Cruise Control Active";
BA_ "VNSigAllNodes" SG_ 2155184128 CrsCntAtv 1;
BA_ "GenSigSendType" SG_ 2155167744 ShftToNtrlIO 10;
BA_ "SignalType" SG_ 2155167744 ShftToNtrlIO "BLN";
BA_ "SignalLongName" SG_ 2155167744 ShftToNtrlIO "Shift to Neutral Indication On";
BA_ "VNSigAllNodes" SG_ 2155167744 ShftToNtrlIO 1;
BA_ "GenSigSendType" SG_ 2155167744 AppPrkBrkIO 10;
BA_ "SignalType" SG_ 2155167744 AppPrkBrkIO "BLN";
BA_ "SignalLongName" SG_ 2155167744 AppPrkBrkIO "Apply Park Brake Indication On";
BA_ "VNSigAllNodes" SG_ 2155167744 AppPrkBrkIO 1;
BA_ "GenSigSendType" SG_ 2155167744 NRmtDtctdRstrtAllwd 10;
BA_ "SignalType" SG_ 2155167744 NRmtDtctdRstrtAllwd "BLN";
BA_ "SignalLongName" SG_ 2155167744 NRmtDtctdRstrtAllwd "No Remote Detected Restart Allowed";
BA_ "VNSigAllNodes" SG_ 2155167744 NRmtDtctdRstrtAllwd 1;
BA_ "GenSigSendType" SG_ 2155167744 NRmtDtdPsCluRstIO 10;
BA_ "SignalType" SG_ 2155167744 NRmtDtdPsCluRstIO "BLN";
BA_ "SignalLongName" SG_ 2155167744 NRmtDtdPsCluRstIO "No Remote Detected Press Clutch to Restart Indicator On";
BA_ "VNSigAllNodes" SG_ 2155167744 NRmtDtdPsCluRstIO 1;
BA_ "GenSigSendType" SG_ 2155167744 SecPwrMdPshBtnAtv 10;
BA_ "SignalType" SG_ 2155167744 SecPwrMdPshBtnAtv "BLN";
BA_ "SignalLongName" SG_ 2155167744 SecPwrMdPshBtnAtv "Secondary Power Mode Pushbutton Active";
BA_ "VNSigAllNodes" SG_ 2155167744 SecPwrMdPshBtnAtv 1;
BA_ "GenSigSendType" SG_ 2155167744 TSLgMdPwrCtOWAtv 10;
BA_ "SignalType" SG_ 2155167744 TSLgMdPwrCtOWAtv "BLN";
BA_ "SignalLongName" SG_ 2155167744 TSLgMdPwrCtOWAtv "Transport Storage Logistic Mode Power Cut Off Warning Active";
BA_ "VNSigAllNodes" SG_ 2155167744 TSLgMdPwrCtOWAtv 1;
BA_ "GenSigSendType" SG_ 2155167744 PrsBtnAgnTTrnEngOffIO 10;
BA_ "SignalType" SG_ 2155167744 PrsBtnAgnTTrnEngOffIO "BLN";
BA_ "SignalLongName" SG_ 2155167744 PrsBtnAgnTTrnEngOffIO "Press Button Again to Turn Engine Off Indicator On";
BA_ "VNSigAllNodes" SG_ 2155167744 PrsBtnAgnTTrnEngOffIO 1;
BA_ "GenSigSendType" SG_ 2155167744 NRmtDtdPsBrkRstIO 10;
BA_ "SignalType" SG_ 2155167744 NRmtDtdPsBrkRstIO "BLN";
BA_ "SignalLongName" SG_ 2155167744 NRmtDtdPsBrkRstIO "No Remote Detected Press Brake to Restart Indicator On";
BA_ "VNSigAllNodes" SG_ 2155167744 NRmtDtdPsBrkRstIO 1;
BA_ "GenSigSendType" SG_ 2155167744 NoReDetInOn 10;
BA_ "SignalType" SG_ 2155167744 NoReDetInOn "BLN";
BA_ "SignalLongName" SG_ 2155167744 NoReDetInOn "No Remote Detected Indication On";
BA_ "VNSigAllNodes" SG_ 2155167744 NoReDetInOn 1;
BA_ "GenSigSendType" SG_ 2155167744 ApplyCltPdlIO 10;
BA_ "SignalType" SG_ 2155167744 ApplyCltPdlIO "BLN";
BA_ "SignalLongName" SG_ 2155167744 ApplyCltPdlIO "Apply Clutch Pedal Indication On";
BA_ "VNSigAllNodes" SG_ 2155167744 ApplyCltPdlIO 1;
BA_ "GenSigSendType" SG_ 2155167744 VehMovState 10;
BA_ "GenSigSendOnInit" SG_ 2155167744 VehMovState 1;
BA_ "SignalType" SG_ 2155167744 VehMovState "ENM";
BA_ "SignalLongName" SG_ 2155167744 VehMovState "Vehicle Movement State";
BA_ "VNSigAllNodes" SG_ 2155167744 VehMovState 1;
BA_ "GenSigSendType" SG_ 2155167744 TrStLgMdAtv 10;
BA_ "GenSigSendOnInit" SG_ 2155167744 TrStLgMdAtv 1;
BA_ "VNSigInfotainment" SG_ 2155167744 TrStLgMdAtv 1;
BA_ "SignalType" SG_ 2155167744 TrStLgMdAtv "BLN";
BA_ "SignalLongName" SG_ 2155167744 TrStLgMdAtv "Transport Storage Logistic Mode Active";
BA_ "VNSigAllNodes" SG_ 2155167744 TrStLgMdAtv 1;
BA_ "GenSigSendType" SG_ 2155167744 TransModInactIO 10;
BA_ "SignalType" SG_ 2155167744 TransModInactIO "BLN";
BA_ "SignalLongName" SG_ 2155167744 TransModInactIO "Transport Mode Inactive Indication On";
BA_ "VNSigAllNodes" SG_ 2155167744 TransModInactIO 1;
BA_ "GenSigSendType" SG_ 2155167744 TransModActIO 10;
BA_ "SignalType" SG_ 2155167744 TransModActIO "BLN";
BA_ "SignalLongName" SG_ 2155167744 TransModActIO "Transport Mode Active Indication On";
BA_ "VNSigAllNodes" SG_ 2155167744 TransModActIO 1;
BA_ "GenSigSendType" SG_ 2155167744 ApplyBrkPdlIO 10;
BA_ "SignalType" SG_ 2155167744 ApplyBrkPdlIO "BLN";
BA_ "SignalLongName" SG_ 2155167744 ApplyBrkPdlIO "Apply Brake Pedal Indication On";
BA_ "VNSigAllNodes" SG_ 2155167744 ApplyBrkPdlIO 1;
BA_ "GenSigSendType" SG_ 2155167744 Ky_IdDevPr 10;
BA_ "GenSigSendOnInit" SG_ 2155167744 Ky_IdDevPr 1;
BA_ "VNSigInfotainment" SG_ 2155167744 Ky_IdDevPr 1;
BA_ "VNSigIntermediate" SG_ 2155167744 Ky_IdDevPr 1;
BA_ "SignalType" SG_ 2155167744 Ky_IdDevPr "BLN";
BA_ "SignalLongName" SG_ 2155167744 Ky_IdDevPr "Key / Identification Device Present";
BA_ "VNSigAllNodes" SG_ 2155167744 Ky_IdDevPr 1;
BA_ "GenSigSendType" SG_ 2155167744 KylsStrtUseTxPckIO 10;
BA_ "SignalType" SG_ 2155167744 KylsStrtUseTxPckIO "BLN";
BA_ "SignalLongName" SG_ 2155167744 KylsStrtUseTxPckIO "Keyless Start Use Transmitter Pocket Indication On";
BA_ "VNSigAllNodes" SG_ 2155167744 KylsStrtUseTxPckIO 1;
BA_ "GenSigSendType" SG_ 2155167744 ShftPrkIO 10;
BA_ "SignalType" SG_ 2155167744 ShftPrkIO "BLN";
BA_ "SignalLongName" SG_ 2155167744 ShftPrkIO "Shift to Park Indication On";
BA_ "VNSigAllNodes" SG_ 2155167744 ShftPrkIO 1;
BA_ "GenSigSendType" SG_ 2154921984 RFRmtCntFobNm 10;
BA_ "SignalType" SG_ 2154921984 RFRmtCntFobNm "ENM";
BA_ "PacketOrder" SG_ 2154921984 RFRmtCntFobNm 1;
BA_ "SignalLongName" SG_ 2154921984 RFRmtCntFobNm "RFA Function : Remote Control Fob Number";
BA_ "VNSigAllNodes" SG_ 2154921984 RFRmtCntFobNm 1;
BA_ "GenSigSendType" SG_ 2154921984 RFRmtCntrlFobFnc 10;
BA_ "SignalType" SG_ 2154921984 RFRmtCntrlFobFnc "ENM";
BA_ "PacketOrder" SG_ 2154921984 RFRmtCntrlFobFnc 2;
BA_ "SignalLongName" SG_ 2154921984 RFRmtCntrlFobFnc "RFA Function : Remote Control Fob Function";
BA_ "VNSigAllNodes" SG_ 2154921984 RFRmtCntrlFobFnc 1;
BA_ "GenSigSendType" SG_ 2154921984 RFRmtCntFobBatLw 10;
BA_ "SignalType" SG_ 2154921984 RFRmtCntFobBatLw "BLN";
BA_ "PacketOrder" SG_ 2154921984 RFRmtCntFobBatLw 3;
BA_ "SignalLongName" SG_ 2154921984 RFRmtCntFobBatLw "RFA Function : Remote Control Fob Battery Low";
BA_ "VNSigAllNodes" SG_ 2154921984 RFRmtCntFobBatLw 1;
BA_ "GenSigSendType" SG_ 2154921984 FobPogLimRchdIndOn 10;
BA_ "SignalType" SG_ 2154921984 FobPogLimRchdIndOn "BLN";
BA_ "SignalLongName" SG_ 2154921984 FobPogLimRchdIndOn "Fob Programming Limit Reached Indication On";
BA_ "VNSigAllNodes" SG_ 2154921984 FobPogLimRchdIndOn 1;
BA_ "GenSigSendType" SG_ 2151317504 PrkAstRrSysStat 10;
BA_ "SignalType" SG_ 2151317504 PrkAstRrSysStat "ENM";
BA_ "SignalLongName" SG_ 2151317504 PrkAstRrSysStat "Parking Assistance Rear System Status";
BA_ "VNSigAllNodes" SG_ 2151317504 PrkAstRrSysStat 1;
BA_ "GenSigSendType" SG_ 2151317504 PARrRgn4ObjStat 10;
BA_ "SignalType" SG_ 2151317504 PARrRgn4ObjStat "ENM";
BA_ "SignalLongName" SG_ 2151317504 PARrRgn4ObjStat "Parking Assistance Rear Region 4 Object Status";
BA_ "VNSigAllNodes" SG_ 2151317504 PARrRgn4ObjStat 1;
BA_ "GenSigSendType" SG_ 2151317504 PARrRgn3ObjStat 10;
BA_ "SignalType" SG_ 2151317504 PARrRgn3ObjStat "ENM";
BA_ "SignalLongName" SG_ 2151317504 PARrRgn3ObjStat "Parking Assistance Rear Region 3 Object Status";
BA_ "VNSigAllNodes" SG_ 2151317504 PARrRgn3ObjStat 1;
BA_ "GenSigSendType" SG_ 2151317504 PARrRgn2ObjStat 10;
BA_ "SignalType" SG_ 2151317504 PARrRgn2ObjStat "ENM";
BA_ "SignalLongName" SG_ 2151317504 PARrRgn2ObjStat "Parking Assistance Rear Region 2 Object Status";
BA_ "VNSigAllNodes" SG_ 2151317504 PARrRgn2ObjStat 1;
BA_ "GenSigSendType" SG_ 2151317504 PARrRgn1ObjStat 10;
BA_ "SignalType" SG_ 2151317504 PARrRgn1ObjStat "ENM";
BA_ "SignalLongName" SG_ 2151317504 PARrRgn1ObjStat "Parking Assistance Rear Region 1 Object Status";
BA_ "VNSigAllNodes" SG_ 2151317504 PARrRgn1ObjStat 1;
BA_ "GenSigDeltaValue" SG_ 2151317504 PrkAsstRrExtdDist 1;
BA_ "GenSigSendType" SG_ 2151317504 PrkAsstRrExtdDist 12;
BA_ "SignalType" SG_ 2151317504 PrkAsstRrExtdDist "UNM";
BA_ "SignalLongName" SG_ 2151317504 PrkAsstRrExtdDist "Parking Assistance Rear Extended Distance";
BA_ "VNSigAllNodes" SG_ 2151317504 PrkAsstRrExtdDist 1;
BA_ "SignalType" SG_ 2151301120 PrkAsstRrOffIO "BLN";
BA_ "SignalLongName" SG_ 2151301120 PrkAsstRrOffIO "Parking Assistance Rear Off Indication On";
BA_ "VNSigAllNodes" SG_ 2151301120 PrkAsstRrOffIO 1;
BA_ "GenSigSendType" SG_ 2151301120 PrkAstAdvSysAct 10;
BA_ "SignalType" SG_ 2151301120 PrkAstAdvSysAct "BLN";
BA_ "SignalLongName" SG_ 2151301120 PrkAstAdvSysAct "Parking Assistance Advanced  System Active";
BA_ "VNSigAllNodes" SG_ 2151301120 PrkAstAdvSysAct 1;
BA_ "GenSigSendType" SG_ 2151301120 PrkAstFrSysStat 10;
BA_ "GenSigSendOnInit" SG_ 2151301120 PrkAstFrSysStat 2;
BA_ "SignalType" SG_ 2151301120 PrkAstFrSysStat "ENM";
BA_ "SignalLongName" SG_ 2151301120 PrkAstFrSysStat "Parking Assistance Front System Status";
BA_ "VNSigAllNodes" SG_ 2151301120 PrkAstFrSysStat 1;
BA_ "GenSigSendType" SG_ 2151301120 PAFrtRgn4ObjStat 10;
BA_ "SignalType" SG_ 2151301120 PAFrtRgn4ObjStat "ENM";
BA_ "SignalLongName" SG_ 2151301120 PAFrtRgn4ObjStat "Parking Assistance Front Region 4 Object Status";
BA_ "VNSigAllNodes" SG_ 2151301120 PAFrtRgn4ObjStat 1;
BA_ "GenSigSendType" SG_ 2151301120 PAFrtRgn3ObjStat 10;
BA_ "SignalType" SG_ 2151301120 PAFrtRgn3ObjStat "ENM";
BA_ "SignalLongName" SG_ 2151301120 PAFrtRgn3ObjStat "Parking Assistance Front Region 3 Object Status";
BA_ "VNSigAllNodes" SG_ 2151301120 PAFrtRgn3ObjStat 1;
BA_ "GenSigSendType" SG_ 2151301120 PAFrtRgn2ObjStat 10;
BA_ "SignalType" SG_ 2151301120 PAFrtRgn2ObjStat "ENM";
BA_ "SignalLongName" SG_ 2151301120 PAFrtRgn2ObjStat "Parking Assistance Front Region 2 Object Status";
BA_ "VNSigAllNodes" SG_ 2151301120 PAFrtRgn2ObjStat 1;
BA_ "GenSigSendType" SG_ 2151301120 PAFrtRgn1ObjStat 10;
BA_ "SignalType" SG_ 2151301120 PAFrtRgn1ObjStat "ENM";
BA_ "SignalLongName" SG_ 2151301120 PAFrtRgn1ObjStat "Parking Assistance Front Region 1 Object Status";
BA_ "VNSigAllNodes" SG_ 2151301120 PAFrtRgn1ObjStat 1;
BA_ "GenSigDeltaValue" SG_ 2151301120 PrkAsstFrtExtdDist 1;
BA_ "GenSigSendType" SG_ 2151301120 PrkAsstFrtExtdDist 12;
BA_ "SignalType" SG_ 2151301120 PrkAsstFrtExtdDist "UNM";
BA_ "SignalLongName" SG_ 2151301120 PrkAsstFrtExtdDist "Parking Assistance Front Extended Distance";
BA_ "VNSigAllNodes" SG_ 2151301120 PrkAsstFrtExtdDist 1;
BA_ "GenSigSendType" SG_ 2153922560 HtrVlvRqstdPstn 10;
BA_ "SignalType" SG_ 2153922560 HtrVlvRqstdPstn "ENM";
BA_ "SignalLongName" SG_ 2153922560 HtrVlvRqstdPstn "Heater Valve Requested Position";
BA_ "VNSigAllNodes" SG_ 2153922560 HtrVlvRqstdPstn 1;
BA_ "GenSigSendType" SG_ 2153922560 ClntHtrElecPwrRatV 10;
BA_ "SignalType" SG_ 2153922560 ClntHtrElecPwrRatV "ENM";
BA_ "SignalLongName" SG_ 2153922560 ClntHtrElecPwrRatV "Coolant Heater Electrical Power Rationalized Validity";
BA_ "VNSigAllNodes" SG_ 2153922560 ClntHtrElecPwrRatV 1;
BA_ "GenSigDeltaValue" SG_ 2153922560 ClntHtrElecPwrRat 1;
BA_ "GenSigSendType" SG_ 2153922560 ClntHtrElecPwrRat 12;
BA_ "SignalType" SG_ 2153922560 ClntHtrElecPwrRat "UNM";
BA_ "SignalLongName" SG_ 2153922560 ClntHtrElecPwrRat "Coolant Heater Electrical Power Rationalized";
BA_ "VNSigAllNodes" SG_ 2153922560 ClntHtrElecPwrRat 1;
BA_ "GenSigDeltaValue" SG_ 2153922560 ClmCtrHiVltPwrRqtd 1;
BA_ "GenSigSendType" SG_ 2153922560 ClmCtrHiVltPwrRqtd 12;
BA_ "GenSigSendOnInit" SG_ 2153922560 ClmCtrHiVltPwrRqtd 1;
BA_ "SignalType" SG_ 2153922560 ClmCtrHiVltPwrRqtd "UNM";
BA_ "SignalLongName" SG_ 2153922560 ClmCtrHiVltPwrRqtd "Climate Control High Voltage Power Requested";
BA_ "VNSigAllNodes" SG_ 2153922560 ClmCtrHiVltPwrRqtd 1;
BA_ "GenSigSendType" SG_ 2153922560 ClmtCtrlHtrEngRunRq 10;
BA_ "SignalType" SG_ 2153922560 ClmtCtrlHtrEngRunRq "ENM";
BA_ "SignalLongName" SG_ 2153922560 ClmtCtrlHtrEngRunRq "Climate Control Heater Engine Run Request";
BA_ "VNSigAllNodes" SG_ 2153922560 ClmtCtrlHtrEngRunRq 1;
BA_ "GenSigSendType" SG_ 2153922560 ClimCtrlVoltBstModReq 10;
BA_ "GenSigSendOnInit" SG_ 2153922560 ClimCtrlVoltBstModReq 1;
BA_ "SignalType" SG_ 2153922560 ClimCtrlVoltBstModReq "BLN";
BA_ "SignalLongName" SG_ 2153922560 ClimCtrlVoltBstModReq "Climate Control Voltage Boost Mode Requested";
BA_ "VNSigAllNodes" SG_ 2153922560 ClimCtrlVoltBstModReq 1;
BA_ "GenSigSendType" SG_ 2153807872 PsvStrtStrngClmnLckTT 10;
BA_ "SignalType" SG_ 2153807872 PsvStrtStrngClmnLckTT "ENM";
BA_ "SignalLongName" SG_ 2153807872 PsvStrtStrngClmnLckTT "Passive Start Steering Column Lock Telltale";
BA_ "VNSigAllNodes" SG_ 2153807872 PsvStrtStrngClmnLckTT 1;
BA_ "GenSigSendType" SG_ 2153807872 ClmSysAuxFlrIndOn 10;
BA_ "SignalType" SG_ 2153807872 ClmSysAuxFlrIndOn "BLN";
BA_ "SignalLongName" SG_ 2153807872 ClmSysAuxFlrIndOn "Column System Auxiliary Failure Indication On";
BA_ "VNSigAllNodes" SG_ 2153807872 ClmSysAuxFlrIndOn 1;
BA_ "GenSigSendType" SG_ 2153807872 PsDoorOpenSwActV 10;
BA_ "SignalType" SG_ 2153807872 PsDoorOpenSwActV "ENM";
BA_ "SignalLongName" SG_ 2153807872 PsDoorOpenSwActV "Passenger Door Open Switch Active Validity";
BA_ "VNSigAllNodes" SG_ 2153807872 PsDoorOpenSwActV 1;
BA_ "GenSigSendType" SG_ 2153807872 PsDoorOpenSwAct 10;
BA_ "GenSigSendOnInit" SG_ 2153807872 PsDoorOpenSwAct 1;
BA_ "SignalType" SG_ 2153807872 PsDoorOpenSwAct "BLN";
BA_ "SignalLongName" SG_ 2153807872 PsDoorOpenSwAct "Passenger Door Open Switch Active";
BA_ "VNSigAllNodes" SG_ 2153807872 PsDoorOpenSwAct 1;
BA_ "GenSigSendType" SG_ 2153807872 DrDoorOpenSwActV 10;
BA_ "SignalType" SG_ 2153807872 DrDoorOpenSwActV "ENM";
BA_ "SignalLongName" SG_ 2153807872 DrDoorOpenSwActV "Driver Door Open Switch Active Validity";
BA_ "VNSigAllNodes" SG_ 2153807872 DrDoorOpenSwActV 1;
BA_ "GenSigSendType" SG_ 2153807872 DrDoorOpenSwAct 10;
BA_ "GenSigSendOnInit" SG_ 2153807872 DrDoorOpenSwAct 1;
BA_ "SignalType" SG_ 2153807872 DrDoorOpenSwAct "BLN";
BA_ "SignalLongName" SG_ 2153807872 DrDoorOpenSwAct "Driver Door Open Switch Active";
BA_ "VNSigAllNodes" SG_ 2153807872 DrDoorOpenSwAct 1;
BA_ "GenSigSendType" SG_ 2151399424 WshFldLw 10;
BA_ "GenSigSendOnInit" SG_ 2151399424 WshFldLw 1;
BA_ "SignalType" SG_ 2151399424 WshFldLw "BLN";
BA_ "SignalLongName" SG_ 2151399424 WshFldLw "Washer Fluid Low";
BA_ "VNSigAllNodes" SG_ 2151399424 WshFldLw 1;
BA_ "SignalType" SG_ 1359 DgnInf_LS54F "UNM";
BA_ "SignalLongName" SG_ 1359 DgnInf_LS54F "Diagnostic Information LS54F";
BA_ "VNSigDiagnostic" SG_ 1359 DgnInf_LS54F 1;
BA_ "VNSigAllNodes" SG_ 1359 DgnInf_LS54F 1;
BA_ "SignalType" SG_ 2154733568 LRPwrDrPosPlsblityFltAct "BLN";
BA_ "SignalLongName" SG_ 2154733568 LRPwrDrPosPlsblityFltAct "Left Rear Power Door Position Plausibility Fault";
BA_ "VNSigAllNodes" SG_ 2154733568 LRPwrDrPosPlsblityFltAct 1;
BA_ "SignalType" SG_ 2154733568 LFPwrDrPosPlsblityFltAct "BLN";
BA_ "SignalLongName" SG_ 2154733568 LFPwrDrPosPlsblityFltAct "Left Front Power Door Position Plausibility Fault";
BA_ "VNSigAllNodes" SG_ 2154733568 LFPwrDrPosPlsblityFltAct 1;
BA_ "SignalType" SG_ 2154733568 LFPwrDrPos "UNM";
BA_ "SignalLongName" SG_ 2154733568 LFPwrDrPos "Left Front Power Door Position";
BA_ "VNSigAllNodes" SG_ 2154733568 LFPwrDrPos 1;
BA_ "SignalType" SG_ 2154733568 LFPwrDrInMtn "BLN";
BA_ "SignalLongName" SG_ 2154733568 LFPwrDrInMtn "Left Front Power Door In Motion";
BA_ "VNSigAllNodes" SG_ 2154733568 LFPwrDrInMtn 1;
BA_ "SignalType" SG_ 2154733568 LFDrOpen "BLN";
BA_ "SignalLongName" SG_ 2154733568 LFDrOpen "Left Front Door Open";
BA_ "VNSigAllNodes" SG_ 2154733568 LFDrOpen 1;
BA_ "SignalType" SG_ 2154733568 DrClsgMtrLFStllDtd "BLN";
BA_ "SignalLongName" SG_ 2154733568 DrClsgMtrLFStllDtd "Door Closing Motor Left Front Stall Detected";
BA_ "VNSigAllNodes" SG_ 2154733568 DrClsgMtrLFStllDtd 1;
BA_ "SignalType" SG_ 2154733568 RRDrOpen "BLN";
BA_ "SignalLongName" SG_ 2154733568 RRDrOpen "Right Rear Door Open";
BA_ "VNSigAllNodes" SG_ 2154733568 RRDrOpen 1;
BA_ "SignalType" SG_ 2154733568 LRDrOpen "BLN";
BA_ "SignalLongName" SG_ 2154733568 LRDrOpen "Left Rear Door Open";
BA_ "VNSigAllNodes" SG_ 2154733568 LRDrOpen 1;
BA_ "SignalType" SG_ 2154733568 RFDrOpen "BLN";
BA_ "SignalLongName" SG_ 2154733568 RFDrOpen "Right Front Door Open";
BA_ "VNSigAllNodes" SG_ 2154733568 RFDrOpen 1;
BA_ "SignalType" SG_ 2154733568 RRPwrDrPosPlsblityFltAct "UNM";
BA_ "SignalLongName" SG_ 2154733568 RRPwrDrPosPlsblityFltAct "Right Rear Power Door Position Plausibility Fault";
BA_ "VNSigAllNodes" SG_ 2154733568 RRPwrDrPosPlsblityFltAct 1;
BA_ "SignalType" SG_ 2154733568 RFPwrDrPosPlsblityFltACt "UNM";
BA_ "SignalLongName" SG_ 2154733568 RFPwrDrPosPlsblityFltACt "Right Front Power Door Position Plausibility Fault";
BA_ "VNSigAllNodes" SG_ 2154733568 RFPwrDrPosPlsblityFltACt 1;
BA_ "SignalType" SG_ 2154733568 RRPwrDrPos "UNM";
BA_ "SignalLongName" SG_ 2154733568 RRPwrDrPos "Right Rear Power Door Position";
BA_ "VNSigAllNodes" SG_ 2154733568 RRPwrDrPos 1;
BA_ "SignalType" SG_ 2154733568 LRPwrDrPos "UNM";
BA_ "SignalLongName" SG_ 2154733568 LRPwrDrPos "Left Rear Power Door Position";
BA_ "VNSigAllNodes" SG_ 2154733568 LRPwrDrPos 1;
BA_ "SignalType" SG_ 2154733568 RFPwrDrPos "UNM";
BA_ "SignalLongName" SG_ 2154733568 RFPwrDrPos "Right Front Power Door Position";
BA_ "VNSigAllNodes" SG_ 2154733568 RFPwrDrPos 1;
BA_ "SignalType" SG_ 2154733568 RRPwrDrInMtn "BLN";
BA_ "SignalLongName" SG_ 2154733568 RRPwrDrInMtn "Right Rear Power Door In Motion";
BA_ "VNSigAllNodes" SG_ 2154733568 RRPwrDrInMtn 1;
BA_ "SignalType" SG_ 2154733568 LRPwrDrInMtn "BLN";
BA_ "SignalLongName" SG_ 2154733568 LRPwrDrInMtn "Left Rear Power Door In Motion";
BA_ "VNSigAllNodes" SG_ 2154733568 LRPwrDrInMtn 1;
BA_ "SignalType" SG_ 2154733568 RFPwrDrInMtn "BLN";
BA_ "SignalLongName" SG_ 2154733568 RFPwrDrInMtn "Right Front Power Door In Motion";
BA_ "VNSigAllNodes" SG_ 2154733568 RFPwrDrInMtn 1;
BA_ "SignalType" SG_ 2154733568 DrClsgMtrRRStllDtd "BLN";
BA_ "SignalLongName" SG_ 2154733568 DrClsgMtrRRStllDtd "Door Closing Motor Right Rear Stall Detected";
BA_ "VNSigAllNodes" SG_ 2154733568 DrClsgMtrRRStllDtd 1;
BA_ "SignalType" SG_ 2154733568 DrClsgMtrLRStllDtd "BLN";
BA_ "SignalLongName" SG_ 2154733568 DrClsgMtrLRStllDtd "Door Closing Motor Left Rear Stall Detected";
BA_ "VNSigAllNodes" SG_ 2154733568 DrClsgMtrLRStllDtd 1;
BA_ "SignalType" SG_ 2154733568 DrClsgMtrRLStllDtd "BLN";
BA_ "SignalLongName" SG_ 2154733568 DrClsgMtrRLStllDtd "Door Closing Motor Right Front Stall Detected";
BA_ "VNSigAllNodes" SG_ 2154733568 DrClsgMtrRLStllDtd 1;
BA_ "GenSigSendType" SG_ 2151342080 PrkAstRtSysStat 10;
BA_ "SignalType" SG_ 2151342080 PrkAstRtSysStat "ENM";
BA_ "SignalLongName" SG_ 2151342080 PrkAstRtSysStat "Parking Assistance Right System Status";
BA_ "VNSigAllNodes" SG_ 2151342080 PrkAstRtSysStat 1;
BA_ "GenSigSendType" SG_ 2151342080 PARtRgn3ObjStat 10;
BA_ "SignalType" SG_ 2151342080 PARtRgn3ObjStat "ENM";
BA_ "SignalLongName" SG_ 2151342080 PARtRgn3ObjStat "Parking Assistance Right Region 3 Object Status";
BA_ "VNSigAllNodes" SG_ 2151342080 PARtRgn3ObjStat 1;
BA_ "GenSigSendType" SG_ 2151342080 PARtRgn2ObjStat 10;
BA_ "SignalType" SG_ 2151342080 PARtRgn2ObjStat "ENM";
BA_ "SignalLongName" SG_ 2151342080 PARtRgn2ObjStat "Parking Assistance Right Region 2 Object Status";
BA_ "VNSigAllNodes" SG_ 2151342080 PARtRgn2ObjStat 1;
BA_ "GenSigSendType" SG_ 2151342080 PARtRgn1ObjStat 10;
BA_ "SignalType" SG_ 2151342080 PARtRgn1ObjStat "ENM";
BA_ "SignalLongName" SG_ 2151342080 PARtRgn1ObjStat "Parking Assistance Right Region 1 Object Status";
BA_ "VNSigAllNodes" SG_ 2151342080 PARtRgn1ObjStat 1;
BA_ "GenSigSendType" SG_ 2151325696 PrkAstLtSysStat 10;
BA_ "SignalType" SG_ 2151325696 PrkAstLtSysStat "ENM";
BA_ "SignalLongName" SG_ 2151325696 PrkAstLtSysStat "Parking Assistance Left System Status";
BA_ "VNSigAllNodes" SG_ 2151325696 PrkAstLtSysStat 1;
BA_ "GenSigSendType" SG_ 2151325696 PALtRgn3ObjStat 10;
BA_ "SignalType" SG_ 2151325696 PALtRgn3ObjStat "ENM";
BA_ "SignalLongName" SG_ 2151325696 PALtRgn3ObjStat "Parking Assistance Left Region 3 Object Status";
BA_ "VNSigAllNodes" SG_ 2151325696 PALtRgn3ObjStat 1;
BA_ "GenSigSendType" SG_ 2151325696 PALtRgn2ObjStat 10;
BA_ "SignalType" SG_ 2151325696 PALtRgn2ObjStat "ENM";
BA_ "SignalLongName" SG_ 2151325696 PALtRgn2ObjStat "Parking Assistance Left Region 2 Object Status";
BA_ "VNSigAllNodes" SG_ 2151325696 PALtRgn2ObjStat 1;
BA_ "GenSigSendType" SG_ 2151325696 PALtRgn1ObjStat 10;
BA_ "SignalType" SG_ 2151325696 PALtRgn1ObjStat "ENM";
BA_ "SignalLongName" SG_ 2151325696 PALtRgn1ObjStat "Parking Assistance Left Region 1 Object Status";
BA_ "VNSigAllNodes" SG_ 2151325696 PALtRgn1ObjStat 1;
BA_ "GenSigDeltaValue" SG_ 2151809024 ElecEngyEconAvg 1;
BA_ "GenSigSendType" SG_ 2151809024 ElecEngyEconAvg 12;
BA_ "SignalType" SG_ 2151809024 ElecEngyEconAvg "UNM";
BA_ "SignalLongName" SG_ 2151809024 ElecEngyEconAvg "Electrical Energy Economy Average";
BA_ "VNSigAllNodes" SG_ 2151809024 ElecEngyEconAvg 1;
BA_ "GenSigDeltaValue" SG_ 2151809024 DrvCycElecEngySt5 1;
BA_ "GenSigSendType" SG_ 2151809024 DrvCycElecEngySt5 12;
BA_ "GenSigSendOnInit" SG_ 2151809024 DrvCycElecEngySt5 1;
BA_ "VNSigInfotainment" SG_ 2151809024 DrvCycElecEngySt5 1;
BA_ "SignalType" SG_ 2151809024 DrvCycElecEngySt5 "UNM";
BA_ "SignalLongName" SG_ 2151809024 DrvCycElecEngySt5 "Drive Cycle Electrical Energy State 5";
BA_ "VNSigAllNodes" SG_ 2151809024 DrvCycElecEngySt5 1;
BA_ "GenSigDeltaValue" SG_ 2151809024 DCEEC_EngyPct4 1;
BA_ "GenSigSendType" SG_ 2151809024 DCEEC_EngyPct4 12;
BA_ "GenSigSendOnInit" SG_ 2151809024 DCEEC_EngyPct4 1;
BA_ "VNSigInfotainment" SG_ 2151809024 DCEEC_EngyPct4 1;
BA_ "SignalType" SG_ 2151809024 DCEEC_EngyPct4 "UNM";
BA_ "PacketOrder" SG_ 2151809024 DCEEC_EngyPct4 4;
BA_ "SignalLongName" SG_ 2151809024 DCEEC_EngyPct4 "Drive Cycle Electrical Energy Consumed : Energy Percent 4";
BA_ "VNSigAllNodes" SG_ 2151809024 DCEEC_EngyPct4 1;
BA_ "GenSigDeltaValue" SG_ 2151809024 DCEEC_EngyPct3 1;
BA_ "GenSigSendType" SG_ 2151809024 DCEEC_EngyPct3 12;
BA_ "GenSigSendOnInit" SG_ 2151809024 DCEEC_EngyPct3 1;
BA_ "VNSigInfotainment" SG_ 2151809024 DCEEC_EngyPct3 1;
BA_ "SignalType" SG_ 2151809024 DCEEC_EngyPct3 "UNM";
BA_ "PacketOrder" SG_ 2151809024 DCEEC_EngyPct3 3;
BA_ "SignalLongName" SG_ 2151809024 DCEEC_EngyPct3 "Drive Cycle Electrical Energy Consumed : Energy Percent 3";
BA_ "VNSigAllNodes" SG_ 2151809024 DCEEC_EngyPct3 1;
BA_ "GenSigDeltaValue" SG_ 2151809024 DCEEC_EngyPct2 1;
BA_ "GenSigSendType" SG_ 2151809024 DCEEC_EngyPct2 12;
BA_ "GenSigSendOnInit" SG_ 2151809024 DCEEC_EngyPct2 1;
BA_ "VNSigInfotainment" SG_ 2151809024 DCEEC_EngyPct2 1;
BA_ "SignalType" SG_ 2151809024 DCEEC_EngyPct2 "UNM";
BA_ "PacketOrder" SG_ 2151809024 DCEEC_EngyPct2 2;
BA_ "SignalLongName" SG_ 2151809024 DCEEC_EngyPct2 "Drive Cycle Electrical Energy Consumed : Energy Percent 2";
BA_ "VNSigAllNodes" SG_ 2151809024 DCEEC_EngyPct2 1;
BA_ "GenSigDeltaValue" SG_ 2151809024 DCEEC_EngyPct1 1;
BA_ "GenSigSendType" SG_ 2151809024 DCEEC_EngyPct1 12;
BA_ "GenSigSendOnInit" SG_ 2151809024 DCEEC_EngyPct1 1;
BA_ "VNSigInfotainment" SG_ 2151809024 DCEEC_EngyPct1 1;
BA_ "SignalType" SG_ 2151809024 DCEEC_EngyPct1 "UNM";
BA_ "PacketOrder" SG_ 2151809024 DCEEC_EngyPct1 1;
BA_ "SignalLongName" SG_ 2151809024 DCEEC_EngyPct1 "Drive Cycle Electrical Energy Consumed : Energy Percent 1";
BA_ "VNSigAllNodes" SG_ 2151809024 DCEEC_EngyPct1 1;
BA_ "GenSigDeltaValue" SG_ 2151858176 DrvCycElecEngySt4 1;
BA_ "GenSigSendType" SG_ 2151858176 DrvCycElecEngySt4 12;
BA_ "GenSigSendOnInit" SG_ 2151858176 DrvCycElecEngySt4 1;
BA_ "VNSigInfotainment" SG_ 2151858176 DrvCycElecEngySt4 1;
BA_ "SignalType" SG_ 2151858176 DrvCycElecEngySt4 "UNM";
BA_ "SignalLongName" SG_ 2151858176 DrvCycElecEngySt4 "Drive Cycle Electrical Energy State 4";
BA_ "VNSigAllNodes" SG_ 2151858176 DrvCycElecEngySt4 1;
BA_ "GenSigDeltaValue" SG_ 2151858176 DrvCycElecEngySt3 1;
BA_ "GenSigSendType" SG_ 2151858176 DrvCycElecEngySt3 12;
BA_ "GenSigSendOnInit" SG_ 2151858176 DrvCycElecEngySt3 1;
BA_ "VNSigInfotainment" SG_ 2151858176 DrvCycElecEngySt3 1;
BA_ "SignalType" SG_ 2151858176 DrvCycElecEngySt3 "UNM";
BA_ "SignalLongName" SG_ 2151858176 DrvCycElecEngySt3 "Drive Cycle Electrical Energy State 3";
BA_ "VNSigAllNodes" SG_ 2151858176 DrvCycElecEngySt3 1;
BA_ "GenSigDeltaValue" SG_ 2151858176 DrvCycElecEngySt2 1;
BA_ "GenSigSendType" SG_ 2151858176 DrvCycElecEngySt2 12;
BA_ "GenSigSendOnInit" SG_ 2151858176 DrvCycElecEngySt2 1;
BA_ "VNSigInfotainment" SG_ 2151858176 DrvCycElecEngySt2 1;
BA_ "SignalType" SG_ 2151858176 DrvCycElecEngySt2 "UNM";
BA_ "SignalLongName" SG_ 2151858176 DrvCycElecEngySt2 "Drive Cycle Electrical Energy State 2";
BA_ "VNSigAllNodes" SG_ 2151858176 DrvCycElecEngySt2 1;
BA_ "GenSigDeltaValue" SG_ 2151858176 DrvCycElecEngySt1 1;
BA_ "GenSigSendType" SG_ 2151858176 DrvCycElecEngySt1 12;
BA_ "GenSigSendOnInit" SG_ 2151858176 DrvCycElecEngySt1 1;
BA_ "VNSigInfotainment" SG_ 2151858176 DrvCycElecEngySt1 1;
BA_ "SignalType" SG_ 2151858176 DrvCycElecEngySt1 "UNM";
BA_ "SignalLongName" SG_ 2151858176 DrvCycElecEngySt1 "Drive Cycle Electrical Energy State 1";
BA_ "VNSigAllNodes" SG_ 2151858176 DrvCycElecEngySt1 1;
BA_ "GenSigDeltaValue" SG_ 2150547456 HVDpltnMdCnfdcTrndg 1;
BA_ "GenSigSendType" SG_ 2150547456 HVDpltnMdCnfdcTrndg 12;
BA_ "SignalType" SG_ 2150547456 HVDpltnMdCnfdcTrndg "SNM";
BA_ "SignalLongName" SG_ 2150547456 HVDpltnMdCnfdcTrndg "High Voltage Depletion Mode Confidence Trending";
BA_ "VNSigAllNodes" SG_ 2150547456 HVDpltnMdCnfdcTrndg 1;
BA_ "GenSigSendType" SG_ 2150547456 OffBrdHVCVehPwrLvl 10;
BA_ "GenSigSendOnInit" SG_ 2150547456 OffBrdHVCVehPwrLvl 1;
BA_ "VNSigInfotainment" SG_ 2150547456 OffBrdHVCVehPwrLvl 1;
BA_ "SignalType" SG_ 2150547456 OffBrdHVCVehPwrLvl "ENM";
BA_ "SignalLongName" SG_ 2150547456 OffBrdHVCVehPwrLvl "Off Board High Voltage Charging Vehicle Power Level";
BA_ "VNSigAllNodes" SG_ 2150547456 OffBrdHVCVehPwrLvl 1;
BA_ "GenSigSendType" SG_ 2150547456 OffBrdHVCVehPwrDrtd 10;
BA_ "GenSigSendOnInit" SG_ 2150547456 OffBrdHVCVehPwrDrtd 1;
BA_ "VNSigInfotainment" SG_ 2150547456 OffBrdHVCVehPwrDrtd 1;
BA_ "SignalType" SG_ 2150547456 OffBrdHVCVehPwrDrtd "BLN";
BA_ "SignalLongName" SG_ 2150547456 OffBrdHVCVehPwrDrtd "Off Board High Voltage Charging Vehicle Power Derated";
BA_ "VNSigAllNodes" SG_ 2150547456 OffBrdHVCVehPwrDrtd 1;
BA_ "GenSigSendType" SG_ 2150547456 OffBrdHVCVehCplrLkd 10;
BA_ "GenSigSendOnInit" SG_ 2150547456 OffBrdHVCVehCplrLkd 1;
BA_ "VNSigInfotainment" SG_ 2150547456 OffBrdHVCVehCplrLkd 1;
BA_ "SignalType" SG_ 2150547456 OffBrdHVCVehCplrLkd "BLN";
BA_ "SignalLongName" SG_ 2150547456 OffBrdHVCVehCplrLkd "Off Board High Voltage Charging Vehicle Coupler Locked";
BA_ "VNSigAllNodes" SG_ 2150547456 OffBrdHVCVehCplrLkd 1;
BA_ "GenSigSendType" SG_ 2150547456 OffBrdHVBlkChrgCmp 10;
BA_ "SignalType" SG_ 2150547456 OffBrdHVBlkChrgCmp "BLN";
BA_ "SignalLongName" SG_ 2150547456 OffBrdHVBlkChrgCmp "Off Board High Voltage Bulk Charging Complete";
BA_ "VNSigAllNodes" SG_ 2150547456 OffBrdHVBlkChrgCmp 1;
BA_ "GenSigDeltaValue" SG_ 2150547456 OBHVBCCT_MinofHr 1;
BA_ "GenSigSendType" SG_ 2150547456 OBHVBCCT_MinofHr 12;
BA_ "GenSigSendOnInit" SG_ 2150547456 OBHVBCCT_MinofHr 1;
BA_ "VNSigInfotainment" SG_ 2150547456 OBHVBCCT_MinofHr 1;
BA_ "SignalType" SG_ 2150547456 OBHVBCCT_MinofHr "UNM";
BA_ "PacketOrder" SG_ 2150547456 OBHVBCCT_MinofHr 3;
BA_ "SignalLongName" SG_ 2150547456 OBHVBCCT_MinofHr "Off Board High Voltage Bulk Charging Complete Time : Minute of Hour";
BA_ "VNSigAllNodes" SG_ 2150547456 OBHVBCCT_MinofHr 1;
BA_ "GenSigDeltaValue" SG_ 2150547456 OBHVBCCT_HrofDay 1;
BA_ "GenSigSendType" SG_ 2150547456 OBHVBCCT_HrofDay 12;
BA_ "GenSigSendOnInit" SG_ 2150547456 OBHVBCCT_HrofDay 1;
BA_ "VNSigInfotainment" SG_ 2150547456 OBHVBCCT_HrofDay 1;
BA_ "SignalType" SG_ 2150547456 OBHVBCCT_HrofDay "UNM";
BA_ "PacketOrder" SG_ 2150547456 OBHVBCCT_HrofDay 2;
BA_ "SignalLongName" SG_ 2150547456 OBHVBCCT_HrofDay "Off Board High Voltage Bulk Charging Complete Time : Hour of Day";
BA_ "VNSigAllNodes" SG_ 2150547456 OBHVBCCT_HrofDay 1;
BA_ "GenSigDeltaValue" SG_ 2150547456 OBHVBCCT_DayofWk 1;
BA_ "GenSigSendType" SG_ 2150547456 OBHVBCCT_DayofWk 12;
BA_ "GenSigSendOnInit" SG_ 2150547456 OBHVBCCT_DayofWk 1;
BA_ "VNSigInfotainment" SG_ 2150547456 OBHVBCCT_DayofWk 1;
BA_ "SignalType" SG_ 2150547456 OBHVBCCT_DayofWk "UNM";
BA_ "PacketOrder" SG_ 2150547456 OBHVBCCT_DayofWk 1;
BA_ "SignalLongName" SG_ 2150547456 OBHVBCCT_DayofWk "Off Board High Voltage Bulk Charging Complete Time : Day of Week";
BA_ "VNSigAllNodes" SG_ 2150547456 OBHVBCCT_DayofWk 1;
BA_ "GenSigSendType" SG_ 2150547456 ElecPrplsnMtrOvrSpdIO 10;
BA_ "SignalType" SG_ 2150547456 ElecPrplsnMtrOvrSpdIO "BLN";
BA_ "SignalLongName" SG_ 2150547456 ElecPrplsnMtrOvrSpdIO "Electric Propulsion Motor Over Speed Indication On";
BA_ "VNSigAllNodes" SG_ 2150547456 ElecPrplsnMtrOvrSpdIO 1;
BA_ "GenSigSendType" SG_ 2150547456 HVBatOutOfEnrgyInd 10;
BA_ "VNSigInfotainment" SG_ 2150547456 HVBatOutOfEnrgyInd 1;
BA_ "SignalType" SG_ 2150547456 HVBatOutOfEnrgyInd "ENM";
BA_ "SignalLongName" SG_ 2150547456 HVBatOutOfEnrgyInd "High Voltage Battery Out of Energy Indication";
BA_ "VNSigAllNodes" SG_ 2150547456 HVBatOutOfEnrgyInd 1;
BA_ "GenSigSendType" SG_ 2150547456 CntrsOpnUndrTmpIO 10;
BA_ "VNSigInfotainment" SG_ 2150547456 CntrsOpnUndrTmpIO 1;
BA_ "SignalType" SG_ 2150547456 CntrsOpnUndrTmpIO "BLN";
BA_ "SignalLongName" SG_ 2150547456 CntrsOpnUndrTmpIO "Contactors Open Under Temperature Indication On";
BA_ "VNSigAllNodes" SG_ 2150547456 CntrsOpnUndrTmpIO 1;
BA_ "GenSigSendType" SG_ 2150547456 HVBatCntctrsOpnIO 10;
BA_ "SignalType" SG_ 2150547456 HVBatCntctrsOpnIO "BLN";
BA_ "SignalLongName" SG_ 2150547456 HVBatCntctrsOpnIO "High Voltage Battery Contactors Open Indication On";
BA_ "VNSigAllNodes" SG_ 2150547456 HVBatCntctrsOpnIO 1;
BA_ "GenSigSendType" SG_ 2150547456 GrnAudQueReq 10;
BA_ "VNSigInfotainment" SG_ 2150547456 GrnAudQueReq 1;
BA_ "SignalType" SG_ 2150547456 GrnAudQueReq "BLN";
BA_ "SignalLongName" SG_ 2150547456 GrnAudQueReq "Green Audio Queue Request";
BA_ "VNSigAllNodes" SG_ 2150547456 GrnAudQueReq 1;
BA_ "GenSigSendType" SG_ 2150547456 SvcHybChrgSysIO 10;
BA_ "VNSigInfotainment" SG_ 2150547456 SvcHybChrgSysIO 1;
BA_ "SignalType" SG_ 2150547456 SvcHybChrgSysIO "BLN";
BA_ "SignalLongName" SG_ 2150547456 SvcHybChrgSysIO "Service Hybrid Charging System Indication On";
BA_ "VNSigAllNodes" SG_ 2150547456 SvcHybChrgSysIO 1;
BA_ "GenSigSendType" SG_ 2150547456 HVChrgrSysStat 10;
BA_ "VNSigInfotainment" SG_ 2150547456 HVChrgrSysStat 1;
BA_ "SignalType" SG_ 2150547456 HVChrgrSysStat "ENM";
BA_ "SignalLongName" SG_ 2150547456 HVChrgrSysStat "High Voltage Charger System Status";
BA_ "VNSigAllNodes" SG_ 2150547456 HVChrgrSysStat 1;
BA_ "GenSigSendType" SG_ 2150547456 HVChrgrCplrStat 10;
BA_ "VNSigInfotainment" SG_ 2150547456 HVChrgrCplrStat 1;
BA_ "SignalType" SG_ 2150547456 HVChrgrCplrStat "ENM";
BA_ "SignalLongName" SG_ 2150547456 HVChrgrCplrStat "High Voltage Charger Coupler Status";
BA_ "VNSigAllNodes" SG_ 2150547456 HVChrgrCplrStat 1;
BA_ "GenSigSendType" SG_ 2150547456 HVBatLimDTmpInd 10;
BA_ "GenSigSendOnInit" SG_ 2150547456 HVBatLimDTmpInd 2;
BA_ "VNSigInfotainment" SG_ 2150547456 HVBatLimDTmpInd 1;
BA_ "SignalType" SG_ 2150547456 HVBatLimDTmpInd "ENM";
BA_ "SignalLongName" SG_ 2150547456 HVBatLimDTmpInd "High Voltage Battery Limitation Due to Temperature Indication";
BA_ "VNSigAllNodes" SG_ 2150547456 HVBatLimDTmpInd 1;
BA_ "GenSigSendType" SG_ 2150547456 HVBatChrgCrdConnIO 10;
BA_ "GenSigSendOnInit" SG_ 2150547456 HVBatChrgCrdConnIO 2;
BA_ "VNSigInfotainment" SG_ 2150547456 HVBatChrgCrdConnIO 1;
BA_ "SignalType" SG_ 2150547456 HVBatChrgCrdConnIO "BLN";
BA_ "SignalLongName" SG_ 2150547456 HVBatChrgCrdConnIO "High Voltage Battery Charge Cord Connected Indication On";
BA_ "VNSigAllNodes" SG_ 2150547456 HVBatChrgCrdConnIO 1;
BA_ "GenSigSendType" SG_ 2150547456 VehChrgMdSt 10;
BA_ "GenSigSendOnInit" SG_ 2150547456 VehChrgMdSt 2;
BA_ "VNSigInfotainment" SG_ 2150547456 VehChrgMdSt 1;
BA_ "SignalType" SG_ 2150547456 VehChrgMdSt "ENM";
BA_ "SignalLongName" SG_ 2150547456 VehChrgMdSt "Vehicle Charge Mode State";
BA_ "VNSigAllNodes" SG_ 2150547456 VehChrgMdSt 1;
BA_ "GenSigDeltaValue" SG_ 2150547456 HVDpltnMdRng 1;
BA_ "GenSigSendType" SG_ 2150547456 HVDpltnMdRng 12;
BA_ "GenSigSendOnInit" SG_ 2150547456 HVDpltnMdRng 1;
BA_ "VNSigInfotainment" SG_ 2150547456 HVDpltnMdRng 1;
BA_ "SignalType" SG_ 2150547456 HVDpltnMdRng "UNM";
BA_ "SignalLongName" SG_ 2150547456 HVDpltnMdRng "High Voltage Depletion Mode Range";
BA_ "VNSigAllNodes" SG_ 2150547456 HVDpltnMdRng 1;
BA_ "GenSigSendType" SG_ 2150547456 ChgrSysAdblIndReq 10;
BA_ "VNSigInfotainment" SG_ 2150547456 ChgrSysAdblIndReq 1;
BA_ "SignalType" SG_ 2150547456 ChgrSysAdblIndReq "ENM";
BA_ "SignalLongName" SG_ 2150547456 ChgrSysAdblIndReq "Charger System Audible Indication Request";
BA_ "VNSigAllNodes" SG_ 2150547456 ChgrSysAdblIndReq 1;
BA_ "GenSigSendType" SG_ 2154708992 ASS2AudSrcStatCode 10;
BA_ "VNSigInfotainment" SG_ 2154708992 ASS2AudSrcStatCode 1;
BA_ "SignalType" SG_ 2154708992 ASS2AudSrcStatCode "ENM";
BA_ "PacketOrder" SG_ 2154708992 ASS2AudSrcStatCode 3;
BA_ "SignalLongName" SG_ 2154708992 ASS2AudSrcStatCode "Audio Source Status 2 : Audio Source Status Code";
BA_ "VNSigAllNodes" SG_ 2154708992 ASS2AudSrcStatCode 1;
BA_ "GenSigSendType" SG_ 2154708992 ASS2AudSrcChType 10;
BA_ "VNSigInfotainment" SG_ 2154708992 ASS2AudSrcChType 1;
BA_ "SignalType" SG_ 2154708992 ASS2AudSrcChType "ENM";
BA_ "PacketOrder" SG_ 2154708992 ASS2AudSrcChType 2;
BA_ "SignalLongName" SG_ 2154708992 ASS2AudSrcChType "Audio Source Status 2 : Audio Source Channel Type";
BA_ "VNSigAllNodes" SG_ 2154708992 ASS2AudSrcChType 1;
BA_ "GenSigSendType" SG_ 2154708992 ASS2AudSrcType 10;
BA_ "VNSigInfotainment" SG_ 2154708992 ASS2AudSrcType 1;
BA_ "SignalType" SG_ 2154708992 ASS2AudSrcType "ENM";
BA_ "PacketOrder" SG_ 2154708992 ASS2AudSrcType 1;
BA_ "SignalLongName" SG_ 2154708992 ASS2AudSrcType "Audio Source Status 2 : Audio Source Type";
BA_ "VNSigAllNodes" SG_ 2154708992 ASS2AudSrcType 1;
BA_ "GenSigSendType" SG_ 2154471424 RrClsrSnwLdIO 10;
BA_ "SignalType" SG_ 2154471424 RrClsrSnwLdIO "BLN";
BA_ "SignalLongName" SG_ 2154471424 RrClsrSnwLdIO "Rear Closure Snow Load Indication On";
BA_ "VNSigAllNodes" SG_ 2154471424 RrClsrSnwLdIO 1;
BA_ "GenSigSendType" SG_ 2154471424 RrClosAjarSwAct 10;
BA_ "GenSigSendOnInit" SG_ 2154471424 RrClosAjarSwAct 1;
BA_ "SignalType" SG_ 2154471424 RrClosAjarSwAct "BLN";
BA_ "SignalLongName" SG_ 2154471424 RrClosAjarSwAct "Rear Closure Ajar Switch Active";
BA_ "VNSigAllNodes" SG_ 2154471424 RrClosAjarSwAct 1;
BA_ "GenSigSendType" SG_ 2158796800 ODII_ODIInd55 10;
BA_ "GenSigSendOnInit" SG_ 2158796800 ODII_ODIInd55 1;
BA_ "VNSigInfotainment" SG_ 2158796800 ODII_ODIInd55 1;
BA_ "SignalType" SG_ 2158796800 ODII_ODIInd55 "BLN";
BA_ "PacketOrder" SG_ 2158796800 ODII_ODIInd55 56;
BA_ "SignalLongName" SG_ 2158796800 ODII_ODIInd55 "Open Display Interface Indication : Open Display Interface Indication 55";
BA_ "VNSigAllNodes" SG_ 2158796800 ODII_ODIInd55 1;
BA_ "GenSigSendType" SG_ 2158796800 ODII_ODIInd54 10;
BA_ "GenSigSendOnInit" SG_ 2158796800 ODII_ODIInd54 1;
BA_ "VNSigInfotainment" SG_ 2158796800 ODII_ODIInd54 1;
BA_ "SignalType" SG_ 2158796800 ODII_ODIInd54 "BLN";
BA_ "PacketOrder" SG_ 2158796800 ODII_ODIInd54 55;
BA_ "SignalLongName" SG_ 2158796800 ODII_ODIInd54 "Open Display Interface Indication : Open Display Interface Indication 54";
BA_ "VNSigAllNodes" SG_ 2158796800 ODII_ODIInd54 1;
BA_ "GenSigSendType" SG_ 2158796800 ODII_ODIInd53 10;
BA_ "GenSigSendOnInit" SG_ 2158796800 ODII_ODIInd53 1;
BA_ "VNSigInfotainment" SG_ 2158796800 ODII_ODIInd53 1;
BA_ "SignalType" SG_ 2158796800 ODII_ODIInd53 "BLN";
BA_ "PacketOrder" SG_ 2158796800 ODII_ODIInd53 54;
BA_ "SignalLongName" SG_ 2158796800 ODII_ODIInd53 "Open Display Interface Indication : Open Display Interface Indication 53";
BA_ "VNSigAllNodes" SG_ 2158796800 ODII_ODIInd53 1;
BA_ "GenSigSendType" SG_ 2158796800 ODII_ODIInd52 10;
BA_ "GenSigSendOnInit" SG_ 2158796800 ODII_ODIInd52 1;
BA_ "VNSigInfotainment" SG_ 2158796800 ODII_ODIInd52 1;
BA_ "SignalType" SG_ 2158796800 ODII_ODIInd52 "BLN";
BA_ "PacketOrder" SG_ 2158796800 ODII_ODIInd52 53;
BA_ "SignalLongName" SG_ 2158796800 ODII_ODIInd52 "Open Display Interface Indication : Open Display Interface Indication 52";
BA_ "VNSigAllNodes" SG_ 2158796800 ODII_ODIInd52 1;
BA_ "GenSigSendType" SG_ 2158796800 ODII_ODIInd51 10;
BA_ "GenSigSendOnInit" SG_ 2158796800 ODII_ODIInd51 1;
BA_ "VNSigInfotainment" SG_ 2158796800 ODII_ODIInd51 1;
BA_ "SignalType" SG_ 2158796800 ODII_ODIInd51 "BLN";
BA_ "PacketOrder" SG_ 2158796800 ODII_ODIInd51 52;
BA_ "SignalLongName" SG_ 2158796800 ODII_ODIInd51 "Open Display Interface Indication : Open Display Interface Indication 51";
BA_ "VNSigAllNodes" SG_ 2158796800 ODII_ODIInd51 1;
BA_ "GenSigSendType" SG_ 2158796800 ODII_ODIInd50 10;
BA_ "GenSigSendOnInit" SG_ 2158796800 ODII_ODIInd50 1;
BA_ "VNSigInfotainment" SG_ 2158796800 ODII_ODIInd50 1;
BA_ "SignalType" SG_ 2158796800 ODII_ODIInd50 "BLN";
BA_ "PacketOrder" SG_ 2158796800 ODII_ODIInd50 51;
BA_ "SignalLongName" SG_ 2158796800 ODII_ODIInd50 "Open Display Interface Indication : Open Display Interface Indication 50";
BA_ "VNSigAllNodes" SG_ 2158796800 ODII_ODIInd50 1;
BA_ "GenSigSendType" SG_ 2158796800 ODII_ODIInd27 10;
BA_ "GenSigSendOnInit" SG_ 2158796800 ODII_ODIInd27 1;
BA_ "VNSigInfotainment" SG_ 2158796800 ODII_ODIInd27 1;
BA_ "SignalType" SG_ 2158796800 ODII_ODIInd27 "BLN";
BA_ "PacketOrder" SG_ 2158796800 ODII_ODIInd27 28;
BA_ "SignalLongName" SG_ 2158796800 ODII_ODIInd27 "Open Display Interface Indication : Open Display Interface Indication 27";
BA_ "VNSigAllNodes" SG_ 2158796800 ODII_ODIInd27 1;
BA_ "GenSigSendType" SG_ 2158796800 ODII_ODIInd26 10;
BA_ "GenSigSendOnInit" SG_ 2158796800 ODII_ODIInd26 1;
BA_ "VNSigInfotainment" SG_ 2158796800 ODII_ODIInd26 1;
BA_ "SignalType" SG_ 2158796800 ODII_ODIInd26 "BLN";
BA_ "PacketOrder" SG_ 2158796800 ODII_ODIInd26 27;
BA_ "SignalLongName" SG_ 2158796800 ODII_ODIInd26 "Open Display Interface Indication : Open Display Interface Indication 26";
BA_ "VNSigAllNodes" SG_ 2158796800 ODII_ODIInd26 1;
BA_ "GenSigSendType" SG_ 2158796800 ODII_ODIInd25 10;
BA_ "GenSigSendOnInit" SG_ 2158796800 ODII_ODIInd25 1;
BA_ "VNSigInfotainment" SG_ 2158796800 ODII_ODIInd25 1;
BA_ "SignalType" SG_ 2158796800 ODII_ODIInd25 "BLN";
BA_ "PacketOrder" SG_ 2158796800 ODII_ODIInd25 26;
BA_ "SignalLongName" SG_ 2158796800 ODII_ODIInd25 "Open Display Interface Indication : Open Display Interface Indication 25";
BA_ "VNSigAllNodes" SG_ 2158796800 ODII_ODIInd25 1;
BA_ "GenSigSendType" SG_ 2158796800 ODII_ODIInd24 10;
BA_ "GenSigSendOnInit" SG_ 2158796800 ODII_ODIInd24 1;
BA_ "VNSigInfotainment" SG_ 2158796800 ODII_ODIInd24 1;
BA_ "SignalType" SG_ 2158796800 ODII_ODIInd24 "BLN";
BA_ "PacketOrder" SG_ 2158796800 ODII_ODIInd24 25;
BA_ "SignalLongName" SG_ 2158796800 ODII_ODIInd24 "Open Display Interface Indication : Open Display Interface Indication 24";
BA_ "VNSigAllNodes" SG_ 2158796800 ODII_ODIInd24 1;
BA_ "GenSigSendType" SG_ 2158796800 ODII_ODIInd23 10;
BA_ "GenSigSendOnInit" SG_ 2158796800 ODII_ODIInd23 1;
BA_ "VNSigInfotainment" SG_ 2158796800 ODII_ODIInd23 1;
BA_ "SignalType" SG_ 2158796800 ODII_ODIInd23 "BLN";
BA_ "PacketOrder" SG_ 2158796800 ODII_ODIInd23 24;
BA_ "SignalLongName" SG_ 2158796800 ODII_ODIInd23 "Open Display Interface Indication : Open Display Interface Indication 23";
BA_ "VNSigAllNodes" SG_ 2158796800 ODII_ODIInd23 1;
BA_ "GenSigSendType" SG_ 2158796800 ODII_ODIInd22 10;
BA_ "GenSigSendOnInit" SG_ 2158796800 ODII_ODIInd22 1;
BA_ "VNSigInfotainment" SG_ 2158796800 ODII_ODIInd22 1;
BA_ "SignalType" SG_ 2158796800 ODII_ODIInd22 "BLN";
BA_ "PacketOrder" SG_ 2158796800 ODII_ODIInd22 23;
BA_ "SignalLongName" SG_ 2158796800 ODII_ODIInd22 "Open Display Interface Indication : Open Display Interface Indication 22";
BA_ "VNSigAllNodes" SG_ 2158796800 ODII_ODIInd22 1;
BA_ "GenSigSendType" SG_ 2158796800 ODII_ODIInd21 10;
BA_ "GenSigSendOnInit" SG_ 2158796800 ODII_ODIInd21 1;
BA_ "VNSigInfotainment" SG_ 2158796800 ODII_ODIInd21 1;
BA_ "SignalType" SG_ 2158796800 ODII_ODIInd21 "BLN";
BA_ "PacketOrder" SG_ 2158796800 ODII_ODIInd21 22;
BA_ "SignalLongName" SG_ 2158796800 ODII_ODIInd21 "Open Display Interface Indication : Open Display Interface Indication 21";
BA_ "VNSigAllNodes" SG_ 2158796800 ODII_ODIInd21 1;
BA_ "GenSigSendType" SG_ 2158796800 ODII_ODIInd20 10;
BA_ "GenSigSendOnInit" SG_ 2158796800 ODII_ODIInd20 1;
BA_ "VNSigInfotainment" SG_ 2158796800 ODII_ODIInd20 1;
BA_ "SignalType" SG_ 2158796800 ODII_ODIInd20 "BLN";
BA_ "PacketOrder" SG_ 2158796800 ODII_ODIInd20 21;
BA_ "SignalLongName" SG_ 2158796800 ODII_ODIInd20 "Open Display Interface Indication : Open Display Interface Indication 20";
BA_ "VNSigAllNodes" SG_ 2158796800 ODII_ODIInd20 1;
BA_ "GenSigSendType" SG_ 2158796800 ODII_ODIInd19 10;
BA_ "GenSigSendOnInit" SG_ 2158796800 ODII_ODIInd19 1;
BA_ "VNSigInfotainment" SG_ 2158796800 ODII_ODIInd19 1;
BA_ "SignalType" SG_ 2158796800 ODII_ODIInd19 "BLN";
BA_ "PacketOrder" SG_ 2158796800 ODII_ODIInd19 20;
BA_ "SignalLongName" SG_ 2158796800 ODII_ODIInd19 "Open Display Interface Indication : Open Display Interface Indication 19";
BA_ "VNSigAllNodes" SG_ 2158796800 ODII_ODIInd19 1;
BA_ "GenSigSendType" SG_ 2158796800 ODII_ODIInd18 10;
BA_ "GenSigSendOnInit" SG_ 2158796800 ODII_ODIInd18 1;
BA_ "VNSigInfotainment" SG_ 2158796800 ODII_ODIInd18 1;
BA_ "SignalType" SG_ 2158796800 ODII_ODIInd18 "BLN";
BA_ "PacketOrder" SG_ 2158796800 ODII_ODIInd18 19;
BA_ "SignalLongName" SG_ 2158796800 ODII_ODIInd18 "Open Display Interface Indication : Open Display Interface Indication 18";
BA_ "VNSigAllNodes" SG_ 2158796800 ODII_ODIInd18 1;
BA_ "GenSigSendType" SG_ 2158796800 ODII_ODIInd17 10;
BA_ "GenSigSendOnInit" SG_ 2158796800 ODII_ODIInd17 1;
BA_ "VNSigInfotainment" SG_ 2158796800 ODII_ODIInd17 1;
BA_ "SignalType" SG_ 2158796800 ODII_ODIInd17 "BLN";
BA_ "PacketOrder" SG_ 2158796800 ODII_ODIInd17 18;
BA_ "SignalLongName" SG_ 2158796800 ODII_ODIInd17 "Open Display Interface Indication : Open Display Interface Indication 17";
BA_ "VNSigAllNodes" SG_ 2158796800 ODII_ODIInd17 1;
BA_ "GenSigSendType" SG_ 2158796800 ODII_ODIInd16 10;
BA_ "GenSigSendOnInit" SG_ 2158796800 ODII_ODIInd16 1;
BA_ "VNSigInfotainment" SG_ 2158796800 ODII_ODIInd16 1;
BA_ "SignalType" SG_ 2158796800 ODII_ODIInd16 "BLN";
BA_ "PacketOrder" SG_ 2158796800 ODII_ODIInd16 17;
BA_ "SignalLongName" SG_ 2158796800 ODII_ODIInd16 "Open Display Interface Indication : Open Display Interface Indication 16";
BA_ "VNSigAllNodes" SG_ 2158796800 ODII_ODIInd16 1;
BA_ "GenSigSendType" SG_ 2158796800 ODII_ODIInd15 10;
BA_ "GenSigSendOnInit" SG_ 2158796800 ODII_ODIInd15 1;
BA_ "VNSigInfotainment" SG_ 2158796800 ODII_ODIInd15 1;
BA_ "SignalType" SG_ 2158796800 ODII_ODIInd15 "BLN";
BA_ "PacketOrder" SG_ 2158796800 ODII_ODIInd15 16;
BA_ "SignalLongName" SG_ 2158796800 ODII_ODIInd15 "Open Display Interface Indication : Open Display Interface Indication 15";
BA_ "VNSigAllNodes" SG_ 2158796800 ODII_ODIInd15 1;
BA_ "GenSigSendType" SG_ 2158796800 ODII_ODIInd14 10;
BA_ "GenSigSendOnInit" SG_ 2158796800 ODII_ODIInd14 1;
BA_ "VNSigInfotainment" SG_ 2158796800 ODII_ODIInd14 1;
BA_ "SignalType" SG_ 2158796800 ODII_ODIInd14 "BLN";
BA_ "PacketOrder" SG_ 2158796800 ODII_ODIInd14 15;
BA_ "SignalLongName" SG_ 2158796800 ODII_ODIInd14 "Open Display Interface Indication : Open Display Interface Indication 14";
BA_ "VNSigAllNodes" SG_ 2158796800 ODII_ODIInd14 1;
BA_ "GenSigSendType" SG_ 2158796800 ODII_ODIInd13 10;
BA_ "GenSigSendOnInit" SG_ 2158796800 ODII_ODIInd13 1;
BA_ "VNSigInfotainment" SG_ 2158796800 ODII_ODIInd13 1;
BA_ "SignalType" SG_ 2158796800 ODII_ODIInd13 "BLN";
BA_ "PacketOrder" SG_ 2158796800 ODII_ODIInd13 14;
BA_ "SignalLongName" SG_ 2158796800 ODII_ODIInd13 "Open Display Interface Indication : Open Display Interface Indication 13";
BA_ "VNSigAllNodes" SG_ 2158796800 ODII_ODIInd13 1;
BA_ "GenSigSendType" SG_ 2158796800 ODII_ODIInd12 10;
BA_ "GenSigSendOnInit" SG_ 2158796800 ODII_ODIInd12 1;
BA_ "VNSigInfotainment" SG_ 2158796800 ODII_ODIInd12 1;
BA_ "SignalType" SG_ 2158796800 ODII_ODIInd12 "BLN";
BA_ "PacketOrder" SG_ 2158796800 ODII_ODIInd12 13;
BA_ "SignalLongName" SG_ 2158796800 ODII_ODIInd12 "Open Display Interface Indication : Open Display Interface Indication 12";
BA_ "VNSigAllNodes" SG_ 2158796800 ODII_ODIInd12 1;
BA_ "GenSigSendType" SG_ 2158796800 ODII_ODIInd11 10;
BA_ "GenSigSendOnInit" SG_ 2158796800 ODII_ODIInd11 1;
BA_ "VNSigInfotainment" SG_ 2158796800 ODII_ODIInd11 1;
BA_ "SignalType" SG_ 2158796800 ODII_ODIInd11 "BLN";
BA_ "PacketOrder" SG_ 2158796800 ODII_ODIInd11 12;
BA_ "SignalLongName" SG_ 2158796800 ODII_ODIInd11 "Open Display Interface Indication : Open Display Interface Indication 11";
BA_ "VNSigAllNodes" SG_ 2158796800 ODII_ODIInd11 1;
BA_ "GenSigSendType" SG_ 2158796800 ODII_ODIInd10 10;
BA_ "GenSigSendOnInit" SG_ 2158796800 ODII_ODIInd10 1;
BA_ "VNSigInfotainment" SG_ 2158796800 ODII_ODIInd10 1;
BA_ "SignalType" SG_ 2158796800 ODII_ODIInd10 "BLN";
BA_ "PacketOrder" SG_ 2158796800 ODII_ODIInd10 11;
BA_ "SignalLongName" SG_ 2158796800 ODII_ODIInd10 "Open Display Interface Indication : Open Display Interface Indication 10";
BA_ "VNSigAllNodes" SG_ 2158796800 ODII_ODIInd10 1;
BA_ "GenSigSendType" SG_ 2158796800 ODII_ODIInd9 10;
BA_ "GenSigSendOnInit" SG_ 2158796800 ODII_ODIInd9 1;
BA_ "VNSigInfotainment" SG_ 2158796800 ODII_ODIInd9 1;
BA_ "SignalType" SG_ 2158796800 ODII_ODIInd9 "BLN";
BA_ "PacketOrder" SG_ 2158796800 ODII_ODIInd9 10;
BA_ "SignalLongName" SG_ 2158796800 ODII_ODIInd9 "Open Display Interface Indication : Open Display Interface Indication 9";
BA_ "VNSigAllNodes" SG_ 2158796800 ODII_ODIInd9 1;
BA_ "GenSigSendType" SG_ 2158796800 ODII_ODIInd8 10;
BA_ "GenSigSendOnInit" SG_ 2158796800 ODII_ODIInd8 1;
BA_ "VNSigInfotainment" SG_ 2158796800 ODII_ODIInd8 1;
BA_ "SignalType" SG_ 2158796800 ODII_ODIInd8 "BLN";
BA_ "PacketOrder" SG_ 2158796800 ODII_ODIInd8 9;
BA_ "SignalLongName" SG_ 2158796800 ODII_ODIInd8 "Open Display Interface Indication : Open Display Interface Indication 8";
BA_ "VNSigAllNodes" SG_ 2158796800 ODII_ODIInd8 1;
BA_ "GenSigSendType" SG_ 2158796800 ODII_ODIInd7 10;
BA_ "GenSigSendOnInit" SG_ 2158796800 ODII_ODIInd7 1;
BA_ "VNSigInfotainment" SG_ 2158796800 ODII_ODIInd7 1;
BA_ "SignalType" SG_ 2158796800 ODII_ODIInd7 "BLN";
BA_ "PacketOrder" SG_ 2158796800 ODII_ODIInd7 8;
BA_ "SignalLongName" SG_ 2158796800 ODII_ODIInd7 "Open Display Interface Indication : Open Display Interface Indication 7";
BA_ "VNSigAllNodes" SG_ 2158796800 ODII_ODIInd7 1;
BA_ "GenSigSendType" SG_ 2158796800 ODII_ODIInd6 10;
BA_ "GenSigSendOnInit" SG_ 2158796800 ODII_ODIInd6 1;
BA_ "VNSigInfotainment" SG_ 2158796800 ODII_ODIInd6 1;
BA_ "SignalType" SG_ 2158796800 ODII_ODIInd6 "BLN";
BA_ "PacketOrder" SG_ 2158796800 ODII_ODIInd6 7;
BA_ "SignalLongName" SG_ 2158796800 ODII_ODIInd6 "Open Display Interface Indication : Open Display Interface Indication 6";
BA_ "VNSigAllNodes" SG_ 2158796800 ODII_ODIInd6 1;
BA_ "GenSigSendType" SG_ 2158796800 ODII_ODIInd5 10;
BA_ "GenSigSendOnInit" SG_ 2158796800 ODII_ODIInd5 1;
BA_ "VNSigInfotainment" SG_ 2158796800 ODII_ODIInd5 1;
BA_ "SignalType" SG_ 2158796800 ODII_ODIInd5 "BLN";
BA_ "PacketOrder" SG_ 2158796800 ODII_ODIInd5 6;
BA_ "SignalLongName" SG_ 2158796800 ODII_ODIInd5 "Open Display Interface Indication : Open Display Interface Indication 5";
BA_ "VNSigAllNodes" SG_ 2158796800 ODII_ODIInd5 1;
BA_ "GenSigSendType" SG_ 2158796800 ODII_ODIInd4 10;
BA_ "GenSigSendOnInit" SG_ 2158796800 ODII_ODIInd4 1;
BA_ "VNSigInfotainment" SG_ 2158796800 ODII_ODIInd4 1;
BA_ "SignalType" SG_ 2158796800 ODII_ODIInd4 "BLN";
BA_ "PacketOrder" SG_ 2158796800 ODII_ODIInd4 5;
BA_ "SignalLongName" SG_ 2158796800 ODII_ODIInd4 "Open Display Interface Indication : Open Display Interface Indication 4";
BA_ "VNSigAllNodes" SG_ 2158796800 ODII_ODIInd4 1;
BA_ "GenSigSendType" SG_ 2158796800 ODII_ODIInd3 10;
BA_ "GenSigSendOnInit" SG_ 2158796800 ODII_ODIInd3 1;
BA_ "VNSigInfotainment" SG_ 2158796800 ODII_ODIInd3 1;
BA_ "SignalType" SG_ 2158796800 ODII_ODIInd3 "BLN";
BA_ "PacketOrder" SG_ 2158796800 ODII_ODIInd3 4;
BA_ "SignalLongName" SG_ 2158796800 ODII_ODIInd3 "Open Display Interface Indication : Open Display Interface Indication 3";
BA_ "VNSigAllNodes" SG_ 2158796800 ODII_ODIInd3 1;
BA_ "GenSigSendType" SG_ 2158796800 ODII_ODIInd2 10;
BA_ "GenSigSendOnInit" SG_ 2158796800 ODII_ODIInd2 1;
BA_ "VNSigInfotainment" SG_ 2158796800 ODII_ODIInd2 1;
BA_ "SignalType" SG_ 2158796800 ODII_ODIInd2 "BLN";
BA_ "PacketOrder" SG_ 2158796800 ODII_ODIInd2 3;
BA_ "SignalLongName" SG_ 2158796800 ODII_ODIInd2 "Open Display Interface Indication : Open Display Interface Indication 2";
BA_ "VNSigAllNodes" SG_ 2158796800 ODII_ODIInd2 1;
BA_ "GenSigSendType" SG_ 2158796800 ODII_ODIInd1 10;
BA_ "GenSigSendOnInit" SG_ 2158796800 ODII_ODIInd1 1;
BA_ "VNSigInfotainment" SG_ 2158796800 ODII_ODIInd1 1;
BA_ "SignalType" SG_ 2158796800 ODII_ODIInd1 "BLN";
BA_ "PacketOrder" SG_ 2158796800 ODII_ODIInd1 2;
BA_ "SignalLongName" SG_ 2158796800 ODII_ODIInd1 "Open Display Interface Indication : Open Display Interface Indication 1";
BA_ "VNSigAllNodes" SG_ 2158796800 ODII_ODIInd1 1;
BA_ "GenSigSendType" SG_ 2158796800 ODII_ODIInd56 10;
BA_ "GenSigSendOnInit" SG_ 2158796800 ODII_ODIInd56 1;
BA_ "VNSigInfotainment" SG_ 2158796800 ODII_ODIInd56 1;
BA_ "SignalType" SG_ 2158796800 ODII_ODIInd56 "BLN";
BA_ "PacketOrder" SG_ 2158796800 ODII_ODIInd56 57;
BA_ "SignalLongName" SG_ 2158796800 ODII_ODIInd56 "Open Display Interface Indication : Open Display Interface Indication 56";
BA_ "VNSigAllNodes" SG_ 2158796800 ODII_ODIInd56 1;
BA_ "GenSigSendType" SG_ 2158796800 ODII_ODIInd49 10;
BA_ "GenSigSendOnInit" SG_ 2158796800 ODII_ODIInd49 1;
BA_ "VNSigInfotainment" SG_ 2158796800 ODII_ODIInd49 1;
BA_ "SignalType" SG_ 2158796800 ODII_ODIInd49 "BLN";
BA_ "PacketOrder" SG_ 2158796800 ODII_ODIInd49 50;
BA_ "SignalLongName" SG_ 2158796800 ODII_ODIInd49 "Open Display Interface Indication : Open Display Interface Indication 49";
BA_ "VNSigAllNodes" SG_ 2158796800 ODII_ODIInd49 1;
BA_ "GenSigSendType" SG_ 2158796800 ODII_ODIInd48 10;
BA_ "GenSigSendOnInit" SG_ 2158796800 ODII_ODIInd48 1;
BA_ "VNSigInfotainment" SG_ 2158796800 ODII_ODIInd48 1;
BA_ "SignalType" SG_ 2158796800 ODII_ODIInd48 "BLN";
BA_ "PacketOrder" SG_ 2158796800 ODII_ODIInd48 49;
BA_ "SignalLongName" SG_ 2158796800 ODII_ODIInd48 "Open Display Interface Indication : Open Display Interface Indication 48";
BA_ "VNSigAllNodes" SG_ 2158796800 ODII_ODIInd48 1;
BA_ "GenSigSendType" SG_ 2158796800 ODII_ODIInd47 10;
BA_ "GenSigSendOnInit" SG_ 2158796800 ODII_ODIInd47 1;
BA_ "VNSigInfotainment" SG_ 2158796800 ODII_ODIInd47 1;
BA_ "SignalType" SG_ 2158796800 ODII_ODIInd47 "BLN";
BA_ "PacketOrder" SG_ 2158796800 ODII_ODIInd47 48;
BA_ "SignalLongName" SG_ 2158796800 ODII_ODIInd47 "Open Display Interface Indication : Open Display Interface Indication 47";
BA_ "VNSigAllNodes" SG_ 2158796800 ODII_ODIInd47 1;
BA_ "GenSigSendType" SG_ 2158796800 ODII_ODIInd46 10;
BA_ "GenSigSendOnInit" SG_ 2158796800 ODII_ODIInd46 1;
BA_ "VNSigInfotainment" SG_ 2158796800 ODII_ODIInd46 1;
BA_ "SignalType" SG_ 2158796800 ODII_ODIInd46 "BLN";
BA_ "PacketOrder" SG_ 2158796800 ODII_ODIInd46 47;
BA_ "SignalLongName" SG_ 2158796800 ODII_ODIInd46 "Open Display Interface Indication : Open Display Interface Indication 46";
BA_ "VNSigAllNodes" SG_ 2158796800 ODII_ODIInd46 1;
BA_ "GenSigSendType" SG_ 2158796800 ODII_ODIInd45 10;
BA_ "GenSigSendOnInit" SG_ 2158796800 ODII_ODIInd45 1;
BA_ "VNSigInfotainment" SG_ 2158796800 ODII_ODIInd45 1;
BA_ "SignalType" SG_ 2158796800 ODII_ODIInd45 "BLN";
BA_ "PacketOrder" SG_ 2158796800 ODII_ODIInd45 46;
BA_ "SignalLongName" SG_ 2158796800 ODII_ODIInd45 "Open Display Interface Indication : Open Display Interface Indication 45";
BA_ "VNSigAllNodes" SG_ 2158796800 ODII_ODIInd45 1;
BA_ "GenSigSendType" SG_ 2158796800 ODII_ODIInd44 10;
BA_ "GenSigSendOnInit" SG_ 2158796800 ODII_ODIInd44 1;
BA_ "VNSigInfotainment" SG_ 2158796800 ODII_ODIInd44 1;
BA_ "SignalType" SG_ 2158796800 ODII_ODIInd44 "BLN";
BA_ "PacketOrder" SG_ 2158796800 ODII_ODIInd44 45;
BA_ "SignalLongName" SG_ 2158796800 ODII_ODIInd44 "Open Display Interface Indication : Open Display Interface Indication 44";
BA_ "VNSigAllNodes" SG_ 2158796800 ODII_ODIInd44 1;
BA_ "GenSigSendType" SG_ 2158796800 ODII_ODIInd43 10;
BA_ "GenSigSendOnInit" SG_ 2158796800 ODII_ODIInd43 1;
BA_ "VNSigInfotainment" SG_ 2158796800 ODII_ODIInd43 1;
BA_ "SignalType" SG_ 2158796800 ODII_ODIInd43 "BLN";
BA_ "PacketOrder" SG_ 2158796800 ODII_ODIInd43 44;
BA_ "SignalLongName" SG_ 2158796800 ODII_ODIInd43 "Open Display Interface Indication : Open Display Interface Indication 43";
BA_ "VNSigAllNodes" SG_ 2158796800 ODII_ODIInd43 1;
BA_ "GenSigSendType" SG_ 2158796800 ODII_ODIInd42 10;
BA_ "GenSigSendOnInit" SG_ 2158796800 ODII_ODIInd42 1;
BA_ "VNSigInfotainment" SG_ 2158796800 ODII_ODIInd42 1;
BA_ "SignalType" SG_ 2158796800 ODII_ODIInd42 "BLN";
BA_ "PacketOrder" SG_ 2158796800 ODII_ODIInd42 43;
BA_ "SignalLongName" SG_ 2158796800 ODII_ODIInd42 "Open Display Interface Indication : Open Display Interface Indication 42";
BA_ "VNSigAllNodes" SG_ 2158796800 ODII_ODIInd42 1;
BA_ "GenSigSendType" SG_ 2158796800 ODII_ODIInd41 10;
BA_ "GenSigSendOnInit" SG_ 2158796800 ODII_ODIInd41 1;
BA_ "VNSigInfotainment" SG_ 2158796800 ODII_ODIInd41 1;
BA_ "SignalType" SG_ 2158796800 ODII_ODIInd41 "BLN";
BA_ "PacketOrder" SG_ 2158796800 ODII_ODIInd41 42;
BA_ "SignalLongName" SG_ 2158796800 ODII_ODIInd41 "Open Display Interface Indication : Open Display Interface Indication 41";
BA_ "VNSigAllNodes" SG_ 2158796800 ODII_ODIInd41 1;
BA_ "GenSigSendType" SG_ 2158796800 ODII_ODIInd40 10;
BA_ "GenSigSendOnInit" SG_ 2158796800 ODII_ODIInd40 1;
BA_ "VNSigInfotainment" SG_ 2158796800 ODII_ODIInd40 1;
BA_ "SignalType" SG_ 2158796800 ODII_ODIInd40 "BLN";
BA_ "PacketOrder" SG_ 2158796800 ODII_ODIInd40 41;
BA_ "SignalLongName" SG_ 2158796800 ODII_ODIInd40 "Open Display Interface Indication : Open Display Interface Indication 40";
BA_ "VNSigAllNodes" SG_ 2158796800 ODII_ODIInd40 1;
BA_ "GenSigSendType" SG_ 2158796800 ODII_ODIInd39 10;
BA_ "GenSigSendOnInit" SG_ 2158796800 ODII_ODIInd39 1;
BA_ "VNSigInfotainment" SG_ 2158796800 ODII_ODIInd39 1;
BA_ "SignalType" SG_ 2158796800 ODII_ODIInd39 "BLN";
BA_ "PacketOrder" SG_ 2158796800 ODII_ODIInd39 40;
BA_ "SignalLongName" SG_ 2158796800 ODII_ODIInd39 "Open Display Interface Indication : Open Display Interface Indication 39";
BA_ "VNSigAllNodes" SG_ 2158796800 ODII_ODIInd39 1;
BA_ "GenSigSendType" SG_ 2158796800 ODII_ODIInd38 10;
BA_ "GenSigSendOnInit" SG_ 2158796800 ODII_ODIInd38 1;
BA_ "VNSigInfotainment" SG_ 2158796800 ODII_ODIInd38 1;
BA_ "SignalType" SG_ 2158796800 ODII_ODIInd38 "BLN";
BA_ "PacketOrder" SG_ 2158796800 ODII_ODIInd38 39;
BA_ "SignalLongName" SG_ 2158796800 ODII_ODIInd38 "Open Display Interface Indication : Open Display Interface Indication 38";
BA_ "VNSigAllNodes" SG_ 2158796800 ODII_ODIInd38 1;
BA_ "GenSigSendType" SG_ 2158796800 ODII_ODIInd37 10;
BA_ "GenSigSendOnInit" SG_ 2158796800 ODII_ODIInd37 1;
BA_ "VNSigInfotainment" SG_ 2158796800 ODII_ODIInd37 1;
BA_ "SignalType" SG_ 2158796800 ODII_ODIInd37 "BLN";
BA_ "PacketOrder" SG_ 2158796800 ODII_ODIInd37 38;
BA_ "SignalLongName" SG_ 2158796800 ODII_ODIInd37 "Open Display Interface Indication : Open Display Interface Indication 37";
BA_ "VNSigAllNodes" SG_ 2158796800 ODII_ODIInd37 1;
BA_ "GenSigSendType" SG_ 2158796800 ODII_ODIInd36 10;
BA_ "GenSigSendOnInit" SG_ 2158796800 ODII_ODIInd36 1;
BA_ "VNSigInfotainment" SG_ 2158796800 ODII_ODIInd36 1;
BA_ "SignalType" SG_ 2158796800 ODII_ODIInd36 "BLN";
BA_ "PacketOrder" SG_ 2158796800 ODII_ODIInd36 37;
BA_ "SignalLongName" SG_ 2158796800 ODII_ODIInd36 "Open Display Interface Indication : Open Display Interface Indication 36";
BA_ "VNSigAllNodes" SG_ 2158796800 ODII_ODIInd36 1;
BA_ "GenSigSendType" SG_ 2158796800 ODII_ODIInd35 10;
BA_ "GenSigSendOnInit" SG_ 2158796800 ODII_ODIInd35 1;
BA_ "VNSigInfotainment" SG_ 2158796800 ODII_ODIInd35 1;
BA_ "SignalType" SG_ 2158796800 ODII_ODIInd35 "BLN";
BA_ "PacketOrder" SG_ 2158796800 ODII_ODIInd35 36;
BA_ "SignalLongName" SG_ 2158796800 ODII_ODIInd35 "Open Display Interface Indication : Open Display Interface Indication 35";
BA_ "VNSigAllNodes" SG_ 2158796800 ODII_ODIInd35 1;
BA_ "GenSigSendType" SG_ 2158796800 ODII_ODIInd34 10;
BA_ "GenSigSendOnInit" SG_ 2158796800 ODII_ODIInd34 1;
BA_ "VNSigInfotainment" SG_ 2158796800 ODII_ODIInd34 1;
BA_ "SignalType" SG_ 2158796800 ODII_ODIInd34 "BLN";
BA_ "PacketOrder" SG_ 2158796800 ODII_ODIInd34 35;
BA_ "SignalLongName" SG_ 2158796800 ODII_ODIInd34 "Open Display Interface Indication : Open Display Interface Indication 34";
BA_ "VNSigAllNodes" SG_ 2158796800 ODII_ODIInd34 1;
BA_ "GenSigSendType" SG_ 2158796800 ODII_ODIInd33 10;
BA_ "GenSigSendOnInit" SG_ 2158796800 ODII_ODIInd33 1;
BA_ "VNSigInfotainment" SG_ 2158796800 ODII_ODIInd33 1;
BA_ "SignalType" SG_ 2158796800 ODII_ODIInd33 "BLN";
BA_ "PacketOrder" SG_ 2158796800 ODII_ODIInd33 34;
BA_ "SignalLongName" SG_ 2158796800 ODII_ODIInd33 "Open Display Interface Indication : Open Display Interface Indication 33";
BA_ "VNSigAllNodes" SG_ 2158796800 ODII_ODIInd33 1;
BA_ "GenSigSendType" SG_ 2158796800 ODII_ODIInd32 10;
BA_ "GenSigSendOnInit" SG_ 2158796800 ODII_ODIInd32 1;
BA_ "VNSigInfotainment" SG_ 2158796800 ODII_ODIInd32 1;
BA_ "SignalType" SG_ 2158796800 ODII_ODIInd32 "BLN";
BA_ "PacketOrder" SG_ 2158796800 ODII_ODIInd32 33;
BA_ "SignalLongName" SG_ 2158796800 ODII_ODIInd32 "Open Display Interface Indication : Open Display Interface Indication 32";
BA_ "VNSigAllNodes" SG_ 2158796800 ODII_ODIInd32 1;
BA_ "GenSigSendType" SG_ 2158796800 ODII_ODIInd31 10;
BA_ "GenSigSendOnInit" SG_ 2158796800 ODII_ODIInd31 1;
BA_ "VNSigInfotainment" SG_ 2158796800 ODII_ODIInd31 1;
BA_ "SignalType" SG_ 2158796800 ODII_ODIInd31 "BLN";
BA_ "PacketOrder" SG_ 2158796800 ODII_ODIInd31 32;
BA_ "SignalLongName" SG_ 2158796800 ODII_ODIInd31 "Open Display Interface Indication : Open Display Interface Indication 31";
BA_ "VNSigAllNodes" SG_ 2158796800 ODII_ODIInd31 1;
BA_ "GenSigSendType" SG_ 2158796800 ODII_ODIInd30 10;
BA_ "GenSigSendOnInit" SG_ 2158796800 ODII_ODIInd30 1;
BA_ "VNSigInfotainment" SG_ 2158796800 ODII_ODIInd30 1;
BA_ "SignalType" SG_ 2158796800 ODII_ODIInd30 "BLN";
BA_ "PacketOrder" SG_ 2158796800 ODII_ODIInd30 31;
BA_ "SignalLongName" SG_ 2158796800 ODII_ODIInd30 "Open Display Interface Indication : Open Display Interface Indication 30";
BA_ "VNSigAllNodes" SG_ 2158796800 ODII_ODIInd30 1;
BA_ "GenSigSendType" SG_ 2158796800 ODII_ODIInd29 10;
BA_ "GenSigSendOnInit" SG_ 2158796800 ODII_ODIInd29 1;
BA_ "VNSigInfotainment" SG_ 2158796800 ODII_ODIInd29 1;
BA_ "SignalType" SG_ 2158796800 ODII_ODIInd29 "BLN";
BA_ "PacketOrder" SG_ 2158796800 ODII_ODIInd29 30;
BA_ "SignalLongName" SG_ 2158796800 ODII_ODIInd29 "Open Display Interface Indication : Open Display Interface Indication 29";
BA_ "VNSigAllNodes" SG_ 2158796800 ODII_ODIInd29 1;
BA_ "GenSigSendType" SG_ 2158796800 ODII_ODIInd28 10;
BA_ "GenSigSendOnInit" SG_ 2158796800 ODII_ODIInd28 1;
BA_ "VNSigInfotainment" SG_ 2158796800 ODII_ODIInd28 1;
BA_ "SignalType" SG_ 2158796800 ODII_ODIInd28 "BLN";
BA_ "PacketOrder" SG_ 2158796800 ODII_ODIInd28 29;
BA_ "SignalLongName" SG_ 2158796800 ODII_ODIInd28 "Open Display Interface Indication : Open Display Interface Indication 28";
BA_ "VNSigAllNodes" SG_ 2158796800 ODII_ODIInd28 1;
BA_ "GenSigDeltaValue" SG_ 2158796800 ODII_FUCID 1;
BA_ "GenSigSendType" SG_ 2158796800 ODII_FUCID 12;
BA_ "GenSigSendOnInit" SG_ 2158796800 ODII_FUCID 1;
BA_ "VNSigInfotainment" SG_ 2158796800 ODII_FUCID 1;
BA_ "SignalType" SG_ 2158796800 ODII_FUCID "UNM";
BA_ "PacketOrder" SG_ 2158796800 ODII_FUCID 1;
BA_ "SignalLongName" SG_ 2158796800 ODII_FUCID "Open Display Interface Indication : Functional Unit Class ID";
BA_ "VNSigAllNodes" SG_ 2158796800 ODII_FUCID 1;
BA_ "GenSigDeltaValue" SG_ 2158755840 ODIE_MultiFrRetCh 1;
BA_ "GenSigSendType" SG_ 2158755840 ODIE_MultiFrRetCh 12;
BA_ "VNSigInfotainment" SG_ 2158755840 ODIE_MultiFrRetCh 1;
BA_ "SignalType" SG_ 2158755840 ODIE_MultiFrRetCh "UNM";
BA_ "PacketOrder" SG_ 2158755840 ODIE_MultiFrRetCh 3;
BA_ "SignalLongName" SG_ 2158755840 ODIE_MultiFrRetCh "Open Display Interface Event Packet : MultiFrameReturnChannel";
BA_ "VNSigAllNodes" SG_ 2158755840 ODIE_MultiFrRetCh 1;
BA_ "GenSigDeltaValue" SG_ 2158755840 ODIE_FUCID 1;
BA_ "GenSigSendType" SG_ 2158755840 ODIE_FUCID 12;
BA_ "VNSigInfotainment" SG_ 2158755840 ODIE_FUCID 1;
BA_ "SignalType" SG_ 2158755840 ODIE_FUCID "UNM";
BA_ "PacketOrder" SG_ 2158755840 ODIE_FUCID 2;
BA_ "SignalLongName" SG_ 2158755840 ODIE_FUCID "Open Display Interface Event Packet : Functional Unit Class ID";
BA_ "VNSigAllNodes" SG_ 2158755840 ODIE_FUCID 1;
BA_ "GenSigDeltaValue" SG_ 2158755840 ODIE_EvID 1;
BA_ "GenSigSendType" SG_ 2158755840 ODIE_EvID 12;
BA_ "VNSigInfotainment" SG_ 2158755840 ODIE_EvID 1;
BA_ "SignalType" SG_ 2158755840 ODIE_EvID "UNM";
BA_ "PacketOrder" SG_ 2158755840 ODIE_EvID 1;
BA_ "SignalLongName" SG_ 2158755840 ODIE_EvID "Open Display Interface Event Packet : Event ID";
BA_ "VNSigAllNodes" SG_ 2158755840 ODIE_EvID 1;
BA_REL_ "GenSigSuprvResp" BU_SG_REL_ UPA_LS SG_ 2149769216 WRSLDWhlRotStatRst 1;
BA_REL_ "GenSigSuprvResp" BU_SG_REL_ UPA_LS SG_ 2149769216 WRSLDWhlDisTpRC 1;
BA_REL_ "GenSigVDAFailComment" BU_SG_REL_ UPA_LS SG_ 2149769216 WRSLDSeqNum "BrkSysVDA";
BA_REL_ "GenSigVDAFailResp" BU_SG_REL_ UPA_LS SG_ 2149769216 WRSLDSeqNum 1;
BA_REL_ "GenSigSuprvResp" BU_SG_REL_ UPA_LS SG_ 2149769216 WRSLDSeqNum 1;
BA_REL_ "GenSigVDAFailComment" BU_SG_REL_ UPA_LS SG_ 2149769216 WRSLDWhlDistVal "BrkSysVDA";
BA_REL_ "GenSigVDAFailResp" BU_SG_REL_ UPA_LS SG_ 2149769216 WRSLDWhlDistVal 1;
BA_REL_ "GenSigSuprvResp" BU_SG_REL_ UPA_LS SG_ 2149769216 WRSLDWhlDistVal 1;
BA_REL_ "GenSigVDAFailComment" BU_SG_REL_ UPA_LS SG_ 2149769216 WRSLDWhlDistTmstm "BrkSysVDA";
BA_REL_ "GenSigVDAFailResp" BU_SG_REL_ UPA_LS SG_ 2149769216 WRSLDWhlDistTmstm 1;
BA_REL_ "GenSigSuprvResp" BU_SG_REL_ UPA_LS SG_ 2149769216 WRSLDWhlDistTmstm 1;
BA_REL_ "GenSigVDAFailComment" BU_SG_REL_ UPA_LS SG_ 2149769216 WRSLDWhlDistPlsCntr "BrkSysVDA";
BA_REL_ "GenSigVDAFailResp" BU_SG_REL_ UPA_LS SG_ 2149769216 WRSLDWhlDistPlsCntr 1;
BA_REL_ "GenSigSuprvResp" BU_SG_REL_ UPA_LS SG_ 2149769216 WRSLDWhlDistPlsCntr 1;
BA_REL_ "GenSigSuprvResp" BU_SG_REL_ UPA_LS SG_ 2149769216 WRSRDWhlDisTpRC 1;
BA_REL_ "GenSigVDAFailComment" BU_SG_REL_ UPA_LS SG_ 2149769216 WRSRDSeqNum "BrkSysVDA";
BA_REL_ "GenSigVDAFailResp" BU_SG_REL_ UPA_LS SG_ 2149769216 WRSRDSeqNum 1;
BA_REL_ "GenSigSuprvResp" BU_SG_REL_ UPA_LS SG_ 2149769216 WRSRDSeqNum 1;
BA_REL_ "GenSigVDAFailComment" BU_SG_REL_ UPA_LS SG_ 2149769216 WRSRDWhlRotStatRst "BrkSysVDA";
BA_REL_ "GenSigVDAFailResp" BU_SG_REL_ UPA_LS SG_ 2149769216 WRSRDWhlRotStatRst 1;
BA_REL_ "GenSigSuprvResp" BU_SG_REL_ UPA_LS SG_ 2149769216 WRSRDWhlRotStatRst 1;
BA_REL_ "GenSigVDAFailComment" BU_SG_REL_ UPA_LS SG_ 2149769216 WRSRDWhlDistVal "BrkSysVDA";
BA_REL_ "GenSigVDAFailResp" BU_SG_REL_ UPA_LS SG_ 2149769216 WRSRDWhlDistVal 1;
BA_REL_ "GenSigSuprvResp" BU_SG_REL_ UPA_LS SG_ 2149769216 WRSRDWhlDistVal 1;
BA_REL_ "GenSigVDAFailComment" BU_SG_REL_ UPA_LS SG_ 2149769216 WRSRDWhlDistTmstm "BrkSysVDA";
BA_REL_ "GenSigVDAFailResp" BU_SG_REL_ UPA_LS SG_ 2149769216 WRSRDWhlDistTmstm 1;
BA_REL_ "GenSigSuprvResp" BU_SG_REL_ UPA_LS SG_ 2149769216 WRSRDWhlDistTmstm 1;
BA_REL_ "GenSigVDAFailComment" BU_SG_REL_ UPA_LS SG_ 2149769216 WRSRDWhlDistPlsCntr "BrkSysVDA";
BA_REL_ "GenSigVDAFailResp" BU_SG_REL_ UPA_LS SG_ 2149769216 WRSRDWhlDistPlsCntr 1;
BA_REL_ "GenSigSuprvResp" BU_SG_REL_ UPA_LS SG_ 2149769216 WRSRDWhlDistPlsCntr 1;
BA_REL_ "GenSigSuprvResp" BU_SG_REL_ EOCM2cp_K1_LS SG_ 2156789760 TimeDispFormat 1;
BA_REL_ "GenSigSuprvResp" BU_SG_REL_ EOCM2cp_K1_LS SG_ 2156789760 CldrYr 1;
BA_REL_ "GenSigSuprvResp" BU_SG_REL_ EOCM2cp_K1_LS SG_ 2156789760 CldrMth 1;
BA_REL_ "GenSigSuprvResp" BU_SG_REL_ EOCM2cp_K1_LS SG_ 2156789760 CldrDay 1;
BA_REL_ "GenSigSuprvResp" BU_SG_REL_ EOCM2cp_K1_LS SG_ 2156789760 TOD_SecofMin 1;
BA_REL_ "GenSigSuprvResp" BU_SG_REL_ EOCM2cp_K1_LS SG_ 2156789760 TOD_MinofHr 1;
BA_REL_ "GenSigSuprvResp" BU_SG_REL_ EOCM2cp_K1_LS SG_ 2156789760 TOD_HrofDay 1;
BA_REL_ "GenSigSuprvResp" BU_SG_REL_ ECC_LS SG_ 2150432768 EngManfldAirTempCrtd 1;
BA_REL_ "GenSigSuprvResp" BU_SG_REL_ BCM_LS SG_ 2155298816 TrPrsMntrTrLdRstRqstd 1;
BA_REL_ "GenSigSuprvResp" BU_SG_REL_ MCTM_LS SG_ 2151112704 FrPasSeatbltRemOccSt 1;
BA_REL_ "GenSigSuprvResp" BU_SG_REL_ ADIMb_LS SG_ 2151112704 FrPasSeatbltRemOccSt 1;
BA_REL_ "GenSigSuprvResp" BU_SG_REL_ SDM_PR_LS SG_ 2151112704 FrPasSeatbltRemOccSt 1;
BA_REL_ "GenSigSuprvResp" BU_SG_REL_ SDM_PR_LS SG_ 2151112704 FrPasSeatResCtrlOccStV 1;
BA_REL_ "GenSigVBitResp" BU_SG_REL_ MCTM_LS SG_ 2151112704 FrPasSeatResCtrlOccSt 1;
BA_REL_ "GenSigSuprvResp" BU_SG_REL_ MCTM_LS SG_ 2151112704 FrPasSeatResCtrlOccSt 1;
BA_REL_ "GenSigVBitResp" BU_SG_REL_ SDM_PR_LS SG_ 2151112704 FrPasSeatResCtrlOccSt 1;
BA_REL_ "GenSigSuprvResp" BU_SG_REL_ SDM_PR_LS SG_ 2151112704 FrPasSeatResCtrlOccSt 1;
BA_REL_ "GenSigSuprvResp" BU_SG_REL_ SDM_PR_LS SG_ 2151112704 FrPsSeatOccSnsOpMd 1;
BA_REL_ "GenSigSuprvResp" BU_SG_REL_ MCTM_LS SG_ 2151112704 FrPsSeatOccFltSt 1;
BA_REL_ "GenSigSuprvResp" BU_SG_REL_ SDM_PR_LS SG_ 2151112704 FrPsSeatOccFltSt 1;
BA_REL_ "GenSigSuprvResp" BU_SG_REL_ MCTM_LS SG_ 2151112704 FrntPassClass 1;
BA_REL_ "GenSigSuprvResp" BU_SG_REL_ SDM_PR_LS SG_ 2151112704 FrntPassClass 1;
BA_REL_ "GenSigSuprvResp" BU_SG_REL_ BCM_LS SG_ 2153938944 RmtRflshMdReqtd 1;
BA_REL_ "GenSigVBitResp" BU_SG_REL_ MCTM_LS SG_ 2150850560 ScndRwRtPsSbltAtc 1;
BA_REL_ "GenSigSuprvResp" BU_SG_REL_ MCTM_LS SG_ 2150850560 ScndRwRtPsSbltAtc 1;
BA_REL_ "GenSigVBitResp" BU_SG_REL_ EOCM2cp_K2_LS SG_ 2150850560 ScndRwRtPsSbltAtc 1;
BA_REL_ "GenSigSuprvResp" BU_SG_REL_ EOCM2cp_K2_LS SG_ 2150850560 ScndRwRtPsSbltAtc 1;
BA_REL_ "GenSigVBitResp" BU_SG_REL_ ADIMb_LS SG_ 2150850560 ScndRwRtPsSbltAtc 1;
BA_REL_ "GenSigSuprvResp" BU_SG_REL_ ADIMb_LS SG_ 2150850560 ScndRwRtPsSbltAtc 1;
BA_REL_ "GenSigVBitResp" BU_SG_REL_ BCM_LS SG_ 2150850560 ScndRwRtPsSbltAtc 1;
BA_REL_ "GenSigVBitResp" BU_SG_REL_ ECC_LS SG_ 2150850560 ScndRwRtPsSbltAtc 1;
BA_REL_ "GenSigSuprvResp" BU_SG_REL_ ECC_LS SG_ 2150850560 ScndRwRtPsSbltAtc 1;
BA_REL_ "GenSigVBitResp" BU_SG_REL_ MCTM_LS SG_ 2150850560 ScndRwCtrPsSbltAtc 1;
BA_REL_ "GenSigSuprvResp" BU_SG_REL_ MCTM_LS SG_ 2150850560 ScndRwCtrPsSbltAtc 1;
BA_REL_ "GenSigVBitResp" BU_SG_REL_ EOCM2cp_K2_LS SG_ 2150850560 ScndRwCtrPsSbltAtc 1;
BA_REL_ "GenSigSuprvResp" BU_SG_REL_ EOCM2cp_K2_LS SG_ 2150850560 ScndRwCtrPsSbltAtc 1;
BA_REL_ "GenSigVBitResp" BU_SG_REL_ ADIMb_LS SG_ 2150850560 ScndRwCtrPsSbltAtc 1;
BA_REL_ "GenSigSuprvResp" BU_SG_REL_ ADIMb_LS SG_ 2150850560 ScndRwCtrPsSbltAtc 1;
BA_REL_ "GenSigVBitResp" BU_SG_REL_ BCM_LS SG_ 2150850560 ScndRwCtrPsSbltAtc 1;
BA_REL_ "GenSigVBitResp" BU_SG_REL_ ECC_LS SG_ 2150850560 ScndRwCtrPsSbltAtc 1;
BA_REL_ "GenSigSuprvResp" BU_SG_REL_ ECC_LS SG_ 2150850560 ScndRwCtrPsSbltAtc 1;
BA_REL_ "GenSigVBitResp" BU_SG_REL_ MCTM_LS SG_ 2150850560 ScndRwLtPsSbltAtc 1;
BA_REL_ "GenSigSuprvResp" BU_SG_REL_ MCTM_LS SG_ 2150850560 ScndRwLtPsSbltAtc 1;
BA_REL_ "GenSigVBitResp" BU_SG_REL_ EOCM2cp_K2_LS SG_ 2150850560 ScndRwLtPsSbltAtc 1;
BA_REL_ "GenSigSuprvResp" BU_SG_REL_ EOCM2cp_K2_LS SG_ 2150850560 ScndRwLtPsSbltAtc 1;
BA_REL_ "GenSigVBitResp" BU_SG_REL_ ADIMb_LS SG_ 2150850560 ScndRwLtPsSbltAtc 1;
BA_REL_ "GenSigSuprvResp" BU_SG_REL_ ADIMb_LS SG_ 2150850560 ScndRwLtPsSbltAtc 1;
BA_REL_ "GenSigVBitResp" BU_SG_REL_ BCM_LS SG_ 2150850560 ScndRwLtPsSbltAtc 1;
BA_REL_ "GenSigVBitResp" BU_SG_REL_ ECC_LS SG_ 2150850560 ScndRwLtPsSbltAtc 1;
BA_REL_ "GenSigSuprvResp" BU_SG_REL_ ECC_LS SG_ 2150850560 ScndRwLtPsSbltAtc 1;
BA_REL_ "GenSigVBitResp" BU_SG_REL_ ADIMb_LS SG_ 2150850560 ScndRwRtPsOccStat 1;
BA_REL_ "GenSigVBitResp" BU_SG_REL_ ADIMb_LS SG_ 2150850560 ScndRwLtPsOccStat 1;
BA_REL_ "GenSigVBitResp" BU_SG_REL_ ADIMb_LS SG_ 2150850560 ScndRwCtrPsOccStat 1;
BA_REL_ "GenSigVBitResp" BU_SG_REL_ MCTM_LS SG_ 2150850560 PsSbltAtc 1;
BA_REL_ "GenSigSuprvResp" BU_SG_REL_ MCTM_LS SG_ 2150850560 PsSbltAtc 1;
BA_REL_ "GenSigSuprvResp" BU_SG_REL_ ECC_LS SG_ 2150850560 PsSbltAtc 1;
BA_REL_ "GenSigVBitResp" BU_SG_REL_ AOS_LS SG_ 2150850560 PsSbltAtc 1;
BA_REL_ "GenSigSuprvResp" BU_SG_REL_ AOS_LS SG_ 2150850560 PsSbltAtc 1;
BA_REL_ "GenSigVBitResp" BU_SG_REL_ MCTM_LS SG_ 2150850560 DrSbltAtc 1;
BA_REL_ "GenSigSuprvResp" BU_SG_REL_ MCTM_LS SG_ 2150850560 DrSbltAtc 1;
BA_REL_ "GenSigVBitResp" BU_SG_REL_ BCM_LS SG_ 2150850560 DrSbltAtc 1;
BA_REL_ "GenSigSuprvResp" BU_SG_REL_ BCM_LS SG_ 2155249664 RRHCSMInd3 1;
BA_REL_ "GenSigSuprvResp" BU_SG_REL_ ECC_LS SG_ 2155249664 RRHCSMInd3 1;
BA_REL_ "GenSigSuprvResp" BU_SG_REL_ BCM_LS SG_ 2155249664 RRHCSMInd2 1;
BA_REL_ "GenSigSuprvResp" BU_SG_REL_ ECC_LS SG_ 2155249664 RRHCSMInd2 1;
BA_REL_ "GenSigSuprvResp" BU_SG_REL_ BCM_LS SG_ 2155249664 RRHCSMInd1 1;
BA_REL_ "GenSigSuprvResp" BU_SG_REL_ ECC_LS SG_ 2155249664 RRHCSMInd1 1;
BA_REL_ "GenSigSuprvResp" BU_SG_REL_ BCM_LS SG_ 2155249664 RRHCSMIndReq 1;
BA_REL_ "GenSigSuprvResp" BU_SG_REL_ ECC_LS SG_ 2155249664 RRHCSMIndReq 1;
BA_REL_ "GenSigSuprvResp" BU_SG_REL_ BCM_LS SG_ 2155249664 RRHCSLSeatLev5 1;
BA_REL_ "GenSigSuprvResp" BU_SG_REL_ ECC_LS SG_ 2155249664 RRHCSLSeatLev5 1;
BA_REL_ "GenSigSuprvResp" BU_SG_REL_ BCM_LS SG_ 2155249664 RRHCSLSeatLev4 1;
BA_REL_ "GenSigSuprvResp" BU_SG_REL_ ECC_LS SG_ 2155249664 RRHCSLSeatLev4 1;
BA_REL_ "GenSigSuprvResp" BU_SG_REL_ BCM_LS SG_ 2155249664 RRHCSLSeatLev3 1;
BA_REL_ "GenSigSuprvResp" BU_SG_REL_ ECC_LS SG_ 2155249664 RRHCSLSeatLev3 1;
BA_REL_ "GenSigSuprvResp" BU_SG_REL_ BCM_LS SG_ 2155249664 RRHCSLSeatLev2 1;
BA_REL_ "GenSigSuprvResp" BU_SG_REL_ ECC_LS SG_ 2155249664 RRHCSLSeatLev2 1;
BA_REL_ "GenSigSuprvResp" BU_SG_REL_ BCM_LS SG_ 2155249664 RRHCSLSeatLev1 1;
BA_REL_ "GenSigSuprvResp" BU_SG_REL_ ECC_LS SG_ 2155249664 RRHCSLSeatLev1 1;
BA_REL_ "GenSigSuprvResp" BU_SG_REL_ BCM_LS SG_ 2155249664 RRHCSLIndReq 1;
BA_REL_ "GenSigSuprvResp" BU_SG_REL_ ECC_LS SG_ 2155249664 RRHCSLIndReq 1;
BA_REL_ "GenSigSuprvResp" BU_SG_REL_ BCM_LS SG_ 2155249664 RLHCSMInd3 1;
BA_REL_ "GenSigSuprvResp" BU_SG_REL_ ECC_LS SG_ 2155249664 RLHCSMInd3 1;
BA_REL_ "GenSigSuprvResp" BU_SG_REL_ BCM_LS SG_ 2155249664 RLHCSMInd2 1;
BA_REL_ "GenSigSuprvResp" BU_SG_REL_ ECC_LS SG_ 2155249664 RLHCSMInd2 1;
BA_REL_ "GenSigSuprvResp" BU_SG_REL_ BCM_LS SG_ 2155249664 RLHCSMInd1 1;
BA_REL_ "GenSigSuprvResp" BU_SG_REL_ ECC_LS SG_ 2155249664 RLHCSMInd1 1;
BA_REL_ "GenSigSuprvResp" BU_SG_REL_ BCM_LS SG_ 2155249664 RLHCSMIndReq 1;
BA_REL_ "GenSigSuprvResp" BU_SG_REL_ ECC_LS SG_ 2155249664 RLHCSMIndReq 1;
BA_REL_ "GenSigSuprvResp" BU_SG_REL_ BCM_LS SG_ 2155249664 RLHCSLSeatLev5 1;
BA_REL_ "GenSigSuprvResp" BU_SG_REL_ ECC_LS SG_ 2155249664 RLHCSLSeatLev5 1;
BA_REL_ "GenSigSuprvResp" BU_SG_REL_ BCM_LS SG_ 2155249664 RLHCSLSeatLev4 1;
BA_REL_ "GenSigSuprvResp" BU_SG_REL_ ECC_LS SG_ 2155249664 RLHCSLSeatLev4 1;
BA_REL_ "GenSigSuprvResp" BU_SG_REL_ BCM_LS SG_ 2155249664 RLHCSLSeatLev3 1;
BA_REL_ "GenSigSuprvResp" BU_SG_REL_ ECC_LS SG_ 2155249664 RLHCSLSeatLev3 1;
BA_REL_ "GenSigSuprvResp" BU_SG_REL_ BCM_LS SG_ 2155249664 RLHCSLSeatLev2 1;
BA_REL_ "GenSigSuprvResp" BU_SG_REL_ ECC_LS SG_ 2155249664 RLHCSLSeatLev2 1;
BA_REL_ "GenSigSuprvResp" BU_SG_REL_ BCM_LS SG_ 2155249664 RLHCSLSeatLev1 1;
BA_REL_ "GenSigSuprvResp" BU_SG_REL_ ECC_LS SG_ 2155249664 RLHCSLSeatLev1 1;
BA_REL_ "GenSigSuprvResp" BU_SG_REL_ BCM_LS SG_ 2155249664 RLHCSLIndReq 1;
BA_REL_ "GenSigSuprvResp" BU_SG_REL_ ECC_LS SG_ 2155249664 RLHCSLIndReq 1;
BA_REL_ "GenSigVDAFailComment" BU_SG_REL_ SDM_PR_LS SG_ 2155184128 CrsCntrlSwStCanSwAct "Engine Virtual Device Availability";
BA_REL_ "GenSigVDAFailResp" BU_SG_REL_ SDM_PR_LS SG_ 2155184128 CrsCntrlSwStCanSwAct 1;
BA_REL_ "GenSigSuprvResp" BU_SG_REL_ SDM_PR_LS SG_ 2155184128 CrsCntrlSwStCanSwAct 1;
BA_REL_ "GenSigVDAFailComment" BU_SG_REL_ SDM_PR_LS SG_ 2155184128 CrsCntrlSwStSwDataIntgty "Engine Virtual Device Availability";
BA_REL_ "GenSigVDAFailResp" BU_SG_REL_ SDM_PR_LS SG_ 2155184128 CrsCntrlSwStSwDataIntgty 1;
BA_REL_ "GenSigSuprvResp" BU_SG_REL_ SDM_PR_LS SG_ 2155184128 CrsCntrlSwStSwDataIntgty 1;
BA_REL_ "GenSigVDAFailComment" BU_SG_REL_ SDM_PR_LS SG_ 2155184128 CrsCntrlSwStSpdInSwAct "Engine Virtual Device Availability";
BA_REL_ "GenSigVDAFailResp" BU_SG_REL_ SDM_PR_LS SG_ 2155184128 CrsCntrlSwStSpdInSwAct 1;
BA_REL_ "GenSigSuprvResp" BU_SG_REL_ SDM_PR_LS SG_ 2155184128 CrsCntrlSwStSpdInSwAct 1;
BA_REL_ "GenSigVDAFailComment" BU_SG_REL_ SDM_PR_LS SG_ 2155184128 CrsCntrlSwStSpDcSwAct "Engine Virtual Device Availability";
BA_REL_ "GenSigVDAFailResp" BU_SG_REL_ SDM_PR_LS SG_ 2155184128 CrsCntrlSwStSpDcSwAct 1;
BA_REL_ "GenSigSuprvResp" BU_SG_REL_ SDM_PR_LS SG_ 2155184128 CrsCntrlSwStSpDcSwAct 1;
BA_REL_ "GenSigVDAFailComment" BU_SG_REL_ SDM_PR_LS SG_ 2155184128 CrsCntrlSwStSetSwAct "Engine Virtual Device Availability";
BA_REL_ "GenSigVDAFailResp" BU_SG_REL_ SDM_PR_LS SG_ 2155184128 CrsCntrlSwStSetSwAct 1;
BA_REL_ "GenSigSuprvResp" BU_SG_REL_ SDM_PR_LS SG_ 2155184128 CrsCntrlSwStSetSwAct 1;
BA_REL_ "GenSigVDAFailComment" BU_SG_REL_ SDM_PR_LS SG_ 2155184128 CrsCntrlSwStResSwAct "Engine Virtual Device Availability";
BA_REL_ "GenSigVDAFailResp" BU_SG_REL_ SDM_PR_LS SG_ 2155184128 CrsCntrlSwStResSwAct 1;
BA_REL_ "GenSigSuprvResp" BU_SG_REL_ SDM_PR_LS SG_ 2155184128 CrsCntrlSwStResSwAct 1;
BA_REL_ "GenSigVDAFailComment" BU_SG_REL_ SDM_PR_LS SG_ 2155184128 CrsCntrlSwStOnSwAct "Engine Virtual Device Availability";
BA_REL_ "GenSigVDAFailResp" BU_SG_REL_ SDM_PR_LS SG_ 2155184128 CrsCntrlSwStOnSwAct 1;
BA_REL_ "GenSigSuprvResp" BU_SG_REL_ SDM_PR_LS SG_ 2155184128 CrsCntrlSwStOnSwAct 1;
BA_REL_ "GenSigVDAFailComment" BU_SG_REL_ SDM_PR_LS SG_ 2155184128 CrsCntAtv "Engine Virtual Device Availability";
BA_REL_ "GenSigVDAFailResp" BU_SG_REL_ SDM_PR_LS SG_ 2155184128 CrsCntAtv 1;
BA_REL_ "GenSigSuprvResp" BU_SG_REL_ SDM_PR_LS SG_ 2155184128 CrsCntAtv 1;
BA_REL_ "GenSigRxStartValue" BU_SG_REL_ PEPS_LS SG_ 2155167744 VehMovState "Parked";
BA_REL_ "GenSigSuprvResp" BU_SG_REL_ MCTM_LS SG_ 2155167744 VehMovState 1;
BA_REL_ "GenSigSuprvResp" BU_SG_REL_ UPA_LS SG_ 2155167744 VehMovState 1;
BA_REL_ "GenSigRxStartValue" BU_SG_REL_ SCCM_2_LS SG_ 2155167744 TrStLgMdAtv "False";
BA_REL_ "GenSigRxStartValue" BU_SG_REL_ SCCM_1_LS SG_ 2155167744 TrStLgMdAtv "False";
BA_REL_ "GenSigSuprvResp" BU_SG_REL_ PEPS_LS SG_ 2154921984 RFRmtCntFobNm 1;
BA_REL_ "GenSigSuprvResp" BU_SG_REL_ PEPS_LS SG_ 2154921984 RFRmtCntrlFobFnc 1;
BA_REL_ "GenSigSuprvResp" BU_SG_REL_ PEPS_LS SG_ 2154921984 RFRmtCntFobBatLw 1;
BA_REL_ "GenSigSuprvResp" BU_SG_REL_ BCM_LS SG_ 2151301120 PrkAstAdvSysAct 1;
BA_REL_ "GenSigSuprvResp" BU_SG_REL_ EOCM2cp_K2_LS SG_ 2151301120 PrkAstAdvSysAct 1;
BA_REL_ "GenSigSuprvResp" BU_SG_REL_ EOCM2cp_K2_LS SG_ 2151301120 PrkAstFrSysStat 1;
BA_REL_ "GenSigSuprvResp" BU_SG_REL_ EOCM2cp_K2_LS SG_ 2151301120 PAFrtRgn4ObjStat 1;
BA_REL_ "GenSigSuprvResp" BU_SG_REL_ EOCM2cp_K2_LS SG_ 2151301120 PAFrtRgn3ObjStat 1;
BA_REL_ "GenSigSuprvResp" BU_SG_REL_ EOCM2cp_K2_LS SG_ 2151301120 PAFrtRgn2ObjStat 1;
BA_REL_ "GenSigSuprvResp" BU_SG_REL_ EOCM2cp_K2_LS SG_ 2151301120 PAFrtRgn1ObjStat 1;
BA_REL_ "GenSigSuprvResp" BU_SG_REL_ EOCM2cp_K2_LS SG_ 2151301120 PrkAsstFrtExtdDist 1;
BA_REL_ "GenSigSuprvResp" BU_SG_REL_ VICM_LS SG_ 2153922560 HtrVlvRqstdPstn 1;
BA_REL_ "GenSigRxStartValue" BU_SG_REL_ DLM_LS SG_ 2153922560 ClntHtrElecPwrRatV "Valid";
BA_REL_ "GenSigVBitResp" BU_SG_REL_ DLM_LS SG_ 2153922560 ClntHtrElecPwrRat 1;
BA_REL_ "GenSigRxStartValue" BU_SG_REL_ DLM_LS SG_ 2153922560 ClntHtrElecPwrRat "0";
BA_REL_ "GenSigSuprvResp" BU_SG_REL_ VICM_LS SG_ 2153922560 ClntHtrElecPwrRat 1;
BA_REL_ "GenSigSuprvResp" BU_SG_REL_ VICM_LS SG_ 2153922560 ClmCtrHiVltPwrRqtd 1;
BA_REL_ "GenSigSuprvResp" BU_SG_REL_ BCM_LS SG_ 2153922560 ClmtCtrlHtrEngRunRq 1;
BA_REL_ "GenSigSuprvResp" BU_SG_REL_ BCM_LS SG_ 2153922560 ClimCtrlVoltBstModReq 1;
BA_REL_ "GenSigVBitResp" BU_SG_REL_ BCM_LS SG_ 2153807872 PsDoorOpenSwAct 1;
BA_REL_ "GenSigSuprvResp" BU_SG_REL_ BCM_LS SG_ 2153807872 PsDoorOpenSwAct 1;
BA_REL_ "GenSigSuprvResp" BU_SG_REL_ BCM_LS SG_ 2153807872 DrDoorOpenSwAct 1;
BA_REL_ "GenSigVBitResp" BU_SG_REL_ BCM_LS SG_ 2153807872 DrDoorOpenSwAct 1;
BA_REL_ "GenSigSuprvResp" BU_SG_REL_ BCM_LS SG_ 2153807872 DrDoorOpenSwAct 1;
BA_REL_ "GenSigSuprvRespSubValue" BU_SG_REL_ BCM_LS SG_ 2151399424 WshFldLw 1;
BA_REL_ "GenSigSuprvResp" BU_SG_REL_ BCM_LS SG_ 2151399424 WshFldLw 1;
BA_REL_ "GenSigSuprvResp" BU_SG_REL_ ADIMb_LS SG_ 2154733568 LFPwrDrPos 1;
BA_REL_ "GenSigSuprvResp" BU_SG_REL_ ADIMb_LS SG_ 2154733568 LFPwrDrInMtn 1;
BA_REL_ "GenSigSuprvResp" BU_SG_REL_ ADIMb_LS SG_ 2154733568 LFDrOpen 1;
BA_REL_ "GenSigRxStartValue" BU_SG_REL_ ADIMb_LS SG_ 2154733568 RRDrOpen "False";
BA_REL_ "GenSigSuprvResp" BU_SG_REL_ ADIMb_LS SG_ 2154733568 RRDrOpen 1;
BA_REL_ "GenSigRxStartValue" BU_SG_REL_ ADIMb_LS SG_ 2154733568 LRDrOpen "False";
BA_REL_ "GenSigSuprvResp" BU_SG_REL_ ADIMb_LS SG_ 2154733568 LRDrOpen 1;
BA_REL_ "GenSigRxStartValue" BU_SG_REL_ ADIMb_LS SG_ 2154733568 RFDrOpen "False";
BA_REL_ "GenSigSuprvResp" BU_SG_REL_ ADIMb_LS SG_ 2154733568 RFDrOpen 1;
BA_REL_ "GenSigRxStartValue" BU_SG_REL_ ADIMb_LS SG_ 2154733568 RRPwrDrPosPlsblityFltAct "Valid";
BA_REL_ "GenSigRxStartValue" BU_SG_REL_ ADIMb_LS SG_ 2154733568 RFPwrDrPosPlsblityFltACt "Valid";
BA_REL_ "GenSigVBitResp" BU_SG_REL_ ADIMb_LS SG_ 2154733568 RRPwrDrPos 1;
BA_REL_ "GenSigRxStartValue" BU_SG_REL_ ADIMb_LS SG_ 2154733568 RRPwrDrPos "0";
BA_REL_ "GenSigSuprvResp" BU_SG_REL_ ADIMb_LS SG_ 2154733568 RRPwrDrPos 1;
BA_REL_ "GenSigVBitResp" BU_SG_REL_ ADIMb_LS SG_ 2154733568 LRPwrDrPos 1;
BA_REL_ "GenSigRxStartValue" BU_SG_REL_ ADIMb_LS SG_ 2154733568 LRPwrDrPos "0";
BA_REL_ "GenSigSuprvResp" BU_SG_REL_ ADIMb_LS SG_ 2154733568 LRPwrDrPos 1;
BA_REL_ "GenSigVBitResp" BU_SG_REL_ ADIMb_LS SG_ 2154733568 RFPwrDrPos 1;
BA_REL_ "GenSigRxStartValue" BU_SG_REL_ ADIMb_LS SG_ 2154733568 RFPwrDrPos "0";
BA_REL_ "GenSigSuprvResp" BU_SG_REL_ ADIMb_LS SG_ 2154733568 RFPwrDrPos 1;
BA_REL_ "GenSigRxStartValue" BU_SG_REL_ ADIMb_LS SG_ 2154733568 RRPwrDrInMtn "False";
BA_REL_ "GenSigSuprvResp" BU_SG_REL_ ADIMb_LS SG_ 2154733568 RRPwrDrInMtn 1;
BA_REL_ "GenSigRxStartValue" BU_SG_REL_ ADIMb_LS SG_ 2154733568 LRPwrDrInMtn "False";
BA_REL_ "GenSigSuprvResp" BU_SG_REL_ ADIMb_LS SG_ 2154733568 LRPwrDrInMtn 1;
BA_REL_ "GenSigSuprvResp" BU_SG_REL_ ADIMb_LS SG_ 2154733568 RFPwrDrInMtn 1;
BA_REL_ "GenSigRxStartValue" BU_SG_REL_ ADIMb_LS SG_ 2154733568 RFPwrDrInMtn "False";
BA_REL_ "GenSigSuprvResp" BU_SG_REL_ ADIMb_LS SG_ 2154733568 RFPwrDrInMtn 1;
BA_REL_ "GenSigRxStartValue" BU_SG_REL_ ADIMb_LS SG_ 2154733568 DrClsgMtrRRStllDtd "False";
BA_REL_ "GenSigSuprvResp" BU_SG_REL_ ADIMb_LS SG_ 2154733568 DrClsgMtrRRStllDtd 1;
BA_REL_ "GenSigSuprvResp" BU_SG_REL_ ADIMb_LS SG_ 2154733568 DrClsgMtrLRStllDtd 1;
BA_REL_ "GenSigRxStartValue" BU_SG_REL_ ADIMb_LS SG_ 2154733568 DrClsgMtrLRStllDtd "False";
BA_REL_ "GenSigSuprvResp" BU_SG_REL_ ADIMb_LS SG_ 2154733568 DrClsgMtrLRStllDtd 1;
BA_REL_ "GenSigSuprvResp" BU_SG_REL_ ADIMb_LS SG_ 2154733568 DrClsgMtrRLStllDtd 1;
BA_REL_ "GenSigRxStartValue" BU_SG_REL_ ADIMb_LS SG_ 2154733568 DrClsgMtrRLStllDtd "False";
BA_REL_ "GenSigSuprvResp" BU_SG_REL_ ADIMb_LS SG_ 2154733568 DrClsgMtrRLStllDtd 1;
BA_REL_ "GenSigSuprvResp" BU_SG_REL_ BCM_LS SG_ 2150547456 HVBatChrgCrdConnIO 1;
BA_REL_ "GenSigSuprvResp" BU_SG_REL_ MCTM_LS SG_ 2154471424 RrClosAjarSwAct 1;
BA_REL_ "GenSigSuprvResp" BU_SG_REL_ ECC_LS SG_ 2154471424 RrClosAjarSwAct 2;
BA_REL_ "GenSigSuprvResp" BU_SG_REL_ PEPS_LS SG_ 2154471424 RrClosAjarSwAct 2;
BA_REL_ "GenSigSuprvResp" BU_SG_REL_ BCM_LS SG_ 2154471424 RrClosAjarSwAct 1;
BA_REL_ "GenSigSuprvResp" BU_SG_REL_ BCM_LS SG_ 2154471424 RrClosAjarSwAct 1;
BA_REL_ "GenSigRxStartValue" BU_SG_REL_ BCM_LS SG_ 2154471424 RrClosAjarSwAct "False";
BA_REL_ "GenSigSuprvResp" BU_SG_REL_ BCM_LS SG_ 2154471424 RrClosAjarSwAct 1;
BA_REL_ "GenSigSuprvResp" BU_SG_REL_ BCM_LS SG_ 2154471424 RrClosAjarSwAct 1;
BA_REL_ "GenSigRxStartValue" BU_SG_REL_ BCM_LS SG_ 2154471424 RrClosAjarSwAct "False";
BA_REL_ "GenSigSuprvResp" BU_SG_REL_ BCM_LS SG_ 2154471424 RrClosAjarSwAct 1;
BA_REL_ "GenSigRxStartValue" BU_SG_REL_ BCM_LS SG_ 2154471424 RrClosAjarSwAct "False";
BA_REL_ "GenSigSuprvResp" BU_SG_REL_ BCM_LS SG_ 2154471424 RrClosAjarSwAct 1;
BA_REL_ "GenSigSuprvResp" BU_SG_REL_ BCM_LS SG_ 2154471424 RrClosAjarSwAct 1;
BA_REL_ "GenSigSuprvResp" BU_SG_REL_ BCM_LS SG_ 2154471424 RrClosAjarSwAct 1;
BA_REL_ "GenSigSuprvResp" BU_SG_REL_ BCM_LS SG_ 2154471424 RrClosAjarSwAct 1;
BA_REL_ "GenSigRxStartValue" BU_SG_REL_ MCTM_LS SG_ 2158796800 ODII_ODIInd55 "0";
BA_REL_ "GenSigRxStartValue" BU_SG_REL_ MCTM_LS SG_ 2158796800 ODII_ODIInd54 "0";
BA_REL_ "GenSigRxStartValue" BU_SG_REL_ MCTM_LS SG_ 2158796800 ODII_ODIInd53 "0";
BA_REL_ "GenSigRxStartValue" BU_SG_REL_ MCTM_LS SG_ 2158796800 ODII_ODIInd52 "0";
BA_REL_ "GenSigRxStartValue" BU_SG_REL_ MCTM_LS SG_ 2158796800 ODII_ODIInd51 "0";
BA_REL_ "GenSigRxStartValue" BU_SG_REL_ MCTM_LS SG_ 2158796800 ODII_ODIInd50 "0";
BA_REL_ "GenSigRxStartValue" BU_SG_REL_ MCTM_LS SG_ 2158796800 ODII_ODIInd27 "0";
BA_REL_ "GenSigRxStartValue" BU_SG_REL_ MCTM_LS SG_ 2158796800 ODII_ODIInd26 "0";
BA_REL_ "GenSigRxStartValue" BU_SG_REL_ MCTM_LS SG_ 2158796800 ODII_ODIInd25 "0";
BA_REL_ "GenSigRxStartValue" BU_SG_REL_ MCTM_LS SG_ 2158796800 ODII_ODIInd24 "0";
BA_REL_ "GenSigRxStartValue" BU_SG_REL_ MCTM_LS SG_ 2158796800 ODII_ODIInd23 "0";
BA_REL_ "GenSigRxStartValue" BU_SG_REL_ MCTM_LS SG_ 2158796800 ODII_ODIInd22 "0";
BA_REL_ "GenSigRxStartValue" BU_SG_REL_ MCTM_LS SG_ 2158796800 ODII_ODIInd21 "0";
BA_REL_ "GenSigRxStartValue" BU_SG_REL_ MCTM_LS SG_ 2158796800 ODII_ODIInd20 "0";
BA_REL_ "GenSigRxStartValue" BU_SG_REL_ MCTM_LS SG_ 2158796800 ODII_ODIInd19 "0";
BA_REL_ "GenSigRxStartValue" BU_SG_REL_ MCTM_LS SG_ 2158796800 ODII_ODIInd18 "0";
BA_REL_ "GenSigRxStartValue" BU_SG_REL_ MCTM_LS SG_ 2158796800 ODII_ODIInd17 "0";
BA_REL_ "GenSigRxStartValue" BU_SG_REL_ MCTM_LS SG_ 2158796800 ODII_ODIInd16 "0";
BA_REL_ "GenSigRxStartValue" BU_SG_REL_ MCTM_LS SG_ 2158796800 ODII_ODIInd15 "0";
BA_REL_ "GenSigRxStartValue" BU_SG_REL_ MCTM_LS SG_ 2158796800 ODII_ODIInd14 "0";
BA_REL_ "GenSigRxStartValue" BU_SG_REL_ MCTM_LS SG_ 2158796800 ODII_ODIInd13 "0";
BA_REL_ "GenSigRxStartValue" BU_SG_REL_ MCTM_LS SG_ 2158796800 ODII_ODIInd12 "0";
BA_REL_ "GenSigRxStartValue" BU_SG_REL_ MCTM_LS SG_ 2158796800 ODII_ODIInd11 "0";
BA_REL_ "GenSigRxStartValue" BU_SG_REL_ MCTM_LS SG_ 2158796800 ODII_ODIInd10 "0";
BA_REL_ "GenSigRxStartValue" BU_SG_REL_ MCTM_LS SG_ 2158796800 ODII_ODIInd9 "0";
BA_REL_ "GenSigRxStartValue" BU_SG_REL_ MCTM_LS SG_ 2158796800 ODII_ODIInd8 "0";
BA_REL_ "GenSigRxStartValue" BU_SG_REL_ MCTM_LS SG_ 2158796800 ODII_ODIInd7 "0";
BA_REL_ "GenSigRxStartValue" BU_SG_REL_ MCTM_LS SG_ 2158796800 ODII_ODIInd6 "0";
BA_REL_ "GenSigRxStartValue" BU_SG_REL_ MCTM_LS SG_ 2158796800 ODII_ODIInd5 "0";
BA_REL_ "GenSigRxStartValue" BU_SG_REL_ MCTM_LS SG_ 2158796800 ODII_ODIInd4 "0";
BA_REL_ "GenSigRxStartValue" BU_SG_REL_ MCTM_LS SG_ 2158796800 ODII_ODIInd3 "0";
BA_REL_ "GenSigRxStartValue" BU_SG_REL_ MCTM_LS SG_ 2158796800 ODII_ODIInd2 "0";
BA_REL_ "GenSigRxStartValue" BU_SG_REL_ MCTM_LS SG_ 2158796800 ODII_ODIInd1 "0";
BA_REL_ "GenSigRxStartValue" BU_SG_REL_ MCTM_LS SG_ 2158796800 ODII_ODIInd56 "0";
BA_REL_ "GenSigRxStartValue" BU_SG_REL_ MCTM_LS SG_ 2158796800 ODII_ODIInd49 "0";
BA_REL_ "GenSigRxStartValue" BU_SG_REL_ MCTM_LS SG_ 2158796800 ODII_ODIInd48 "0";
BA_REL_ "GenSigRxStartValue" BU_SG_REL_ MCTM_LS SG_ 2158796800 ODII_ODIInd47 "0";
BA_REL_ "GenSigRxStartValue" BU_SG_REL_ MCTM_LS SG_ 2158796800 ODII_ODIInd46 "0";
BA_REL_ "GenSigRxStartValue" BU_SG_REL_ MCTM_LS SG_ 2158796800 ODII_ODIInd45 "0";
BA_REL_ "GenSigRxStartValue" BU_SG_REL_ MCTM_LS SG_ 2158796800 ODII_ODIInd44 "0";
BA_REL_ "GenSigRxStartValue" BU_SG_REL_ MCTM_LS SG_ 2158796800 ODII_ODIInd43 "0";
BA_REL_ "GenSigRxStartValue" BU_SG_REL_ MCTM_LS SG_ 2158796800 ODII_ODIInd42 "0";
BA_REL_ "GenSigRxStartValue" BU_SG_REL_ MCTM_LS SG_ 2158796800 ODII_ODIInd41 "0";
BA_REL_ "GenSigRxStartValue" BU_SG_REL_ MCTM_LS SG_ 2158796800 ODII_ODIInd40 "0";
BA_REL_ "GenSigRxStartValue" BU_SG_REL_ MCTM_LS SG_ 2158796800 ODII_ODIInd39 "0";
BA_REL_ "GenSigRxStartValue" BU_SG_REL_ MCTM_LS SG_ 2158796800 ODII_ODIInd38 "0";
BA_REL_ "GenSigRxStartValue" BU_SG_REL_ MCTM_LS SG_ 2158796800 ODII_ODIInd37 "0";
BA_REL_ "GenSigRxStartValue" BU_SG_REL_ MCTM_LS SG_ 2158796800 ODII_ODIInd36 "0";
BA_REL_ "GenSigRxStartValue" BU_SG_REL_ MCTM_LS SG_ 2158796800 ODII_ODIInd35 "0";
BA_REL_ "GenSigRxStartValue" BU_SG_REL_ MCTM_LS SG_ 2158796800 ODII_ODIInd34 "0";
BA_REL_ "GenSigRxStartValue" BU_SG_REL_ MCTM_LS SG_ 2158796800 ODII_ODIInd33 "0";
BA_REL_ "GenSigRxStartValue" BU_SG_REL_ MCTM_LS SG_ 2158796800 ODII_ODIInd32 "0";
BA_REL_ "GenSigRxStartValue" BU_SG_REL_ MCTM_LS SG_ 2158796800 ODII_ODIInd31 "0";
BA_REL_ "GenSigRxStartValue" BU_SG_REL_ MCTM_LS SG_ 2158796800 ODII_ODIInd30 "0";
BA_REL_ "GenSigRxStartValue" BU_SG_REL_ MCTM_LS SG_ 2158796800 ODII_ODIInd29 "0";
BA_REL_ "GenSigRxStartValue" BU_SG_REL_ MCTM_LS SG_ 2158796800 ODII_ODIInd28 "0";
BA_REL_ "GenSigRxStartValue" BU_SG_REL_ MCTM_LS SG_ 2158796800 ODII_FUCID "0";
BA_REL_ "GenSigRxStartValue" BU_SG_REL_ MCTM_LS SG_ 2158755840 ODIE_MultiFrRetCh "0";
BA_REL_ "GenSigRxStartValue" BU_SG_REL_ MCTM_LS SG_ 2158755840 ODIE_FUCID "0";
BA_REL_ "GenSigRxStartValue" BU_SG_REL_ MCTM_LS SG_ 2158755840 ODIE_EvID "0";
VAL_ 2149769216 WRSLDWhlRotStatRst 1 "true" 0 "false" ;
VAL_ 2149769216 WRSLDWhlDistVal 1 "Invalid" 0 "Valid" ;
VAL_ 2149769216 WRSRDWhlRotStatRst 1 "true" 0 "false" ;
VAL_ 2149769216 WRSRDWhlDistVal 1 "Invalid" 0 "Valid" ;
VAL_ 2156789760 FrPedDetCsStReq 3 "Alert and Brake" 2 "Alert" 1 "Off" 0 "No Action" ;
VAL_ 2156789760 SmrtHgBmAstCstSetReq 7 "Unused and Reserved 5" 6 "Unused and Reserved 4" 5 "Unused and Reserved 3" 4 "Unused and Reserved 2" 3 "Unused and Reserved 1" 2 "Adaptive High Beam" 1 "Auto High Beam" 0 "No Action" ;
VAL_ 2156789760 TimeDispFormat 1 "24 hour mode" 0 "12 hour mode" ;
VAL_ 2156789760 CldrMth 12 "December" 11 "November" 10 "October" 9 "September" 8 "August" 7 "July" 6 "June" 5 "May" 4 "April" 3 "March" 2 "February" 1 "January" 0 "Unknown" ;
VAL_ 2150432768 EngManfldAirTempCrtdV 1 "Invalid" 0 "Valid" ;
VAL_ 2150432768 GrdBrkgAct 1 "true" 0 "false" ;
VAL_ 2150432768 FuelFltLifRstPerf 1 "true" 0 "false" ;
VAL_ 2150432768 EngShtdwnPndgIO 1 "true" 0 "false" ;
VAL_ 2150432768 GenFldDutCycV 1 "Invalid" 0 "Valid" ;
VAL_ 2150432768 TransOilTempSensPres 1 "true" 0 "false" ;
VAL_ 2150432768 TrnsNEmsRltMalfActv 1 "true" 0 "false" ;
VAL_ 2150432768 TrnEmsMlfAtv 1 "true" 0 "false" ;
VAL_ 2150432768 TrnsThrmlMngmntStat 2 "Driver Intervention Requested" 1 "Countermeasures Active" 0 "Normal" ;
VAL_ 2150432768 PTHiElecLdReqd 1 "true" 0 "false" ;
VAL_ 2155298816 TrPrsMntrTrLdRstRqstd 0 "Unknown" 1 "Light Load" 2 "Best Economy Load" 3 "Max Load" ;
VAL_ 2155298816 TrPrsSnsProgEvntRqd 1 "true" 0 "false" ;
VAL_ 2158878720 ODDLC_WrpArnd 1 "true" 0 "false" ;
VAL_ 2158878720 ODDLC_ReqType 0 "Subscribe: FU sends DynData back and then on change) " 1 "Unsubscribe: cancel previous Subscribe" ;
VAL_ 2158878720 ODDLC_ReqDir 1 "true" 0 "false" ;
VAL_ 2158878720 ODDLC_DspMID 128 "Reserved" 64 "Reserved" 32 "OTIM" 16 "RearDisplayTwo" 8 "RearDisplayOne" 4 "AuxIP" 2 "CenterStack" 1 "IPC" ;
VAL_ 2158878720 ODDLC_BckgndFlag 1 "Background response" 0 "Immediate response required" ;
VAL_ 2151112704 FrPasSeatbltRemOccSt 1 "Occupied" 0 "Empty" ;
VAL_ 2151112704 FrPasSeatResCtrlOccStV 1 "Invalid" 0 "Valid" ;
VAL_ 2151112704 FrPasSeatResCtrlOccSt 2 "Occupied" 1 "Empty" 0 "Unknown" ;
VAL_ 2151112704 FrPsSeatOccSnsOpMd 3 "SystemInitMod" 2 "BarrierMod" 1 "ZeroSetCheckMod" 0 "FieldMod" ;
VAL_ 2151112704 FrPsSeatOccFltSt 2 "Fault Present - Vehicle Mismatch" 1 "Fault Present" 0 "No Faults Present" ;
VAL_ 2151112704 FrntPassClass 7 "Large Adult" 6 "Small Adult" 5 "Large Child" 4 "Small Child" 3 "Child Seat Unknown" 2 "Child Seat Forward" 1 "Child Seat Rearward" 0 "Classification Not Applicable" ;
VAL_ 2153947136 RmtRflshMdAct 1 "true" 0 "false" ;
VAL_ 2153938944 RmtRflshMdReqtd 1 "true" 0 "false" ;
VAL_ 2150662144 EnvIdRspSt3 3 "Environment_id_request" 2 "Incorrect_immo_id" 1 "Info_valid" 0 "No_info" ;
VAL_ 2150653952 EnvIdRspSt2 3 "Environment_id_request" 2 "Incorrect_immo_id" 1 "Info_valid" 0 "No_info" ;
VAL_ 2150850560 ScndRwRtPsSbltAtcV 1 "Invalid" 0 "Valid" ;
VAL_ 2150850560 ScndRwRtPsSbltAtc 1 "true" 0 "false" ;
VAL_ 2150850560 ScndRwCtrPsSbltAtcV 1 "Invalid" 0 "Valid" ;
VAL_ 2150850560 ScndRwCtrPsSbltAtc 1 "true" 0 "false" ;
VAL_ 2150850560 ScndRwLtPsSbltAtcV 1 "Invalid" 0 "Valid" ;
VAL_ 2150850560 ScndRwLtPsSbltAtc 1 "true" 0 "false" ;
VAL_ 2150850560 ScndRwRtPsOccStatV 1 "Invalid" 0 "Valid" ;
VAL_ 2150850560 ScndRwRtPsOccStat 2 "Occupied" 1 "Empty" 0 "Unknown" ;
VAL_ 2150850560 ScndRwLtPsOccStatV 1 "Invalid" 0 "Valid" ;
VAL_ 2150850560 ScndRwLtPsOccStat 2 "Occupied" 1 "Empty" 0 "Unknown" ;
VAL_ 2150850560 ScndRwCtrPsOccStatV 1 "Invalid" 0 "Valid" ;
VAL_ 2150850560 ScndRwCtrPsOccStat 2 "Occupied" 1 "Empty" 0 "Unknown" ;
VAL_ 2150850560 PsSbltAtcV 1 "Invalid" 0 "Valid" ;
VAL_ 2150850560 PsSbltAtc 1 "true" 0 "false" ;
VAL_ 2150850560 DrSbltAtcV 1 "Invalid" 0 "Valid" ;
VAL_ 2150850560 DrSbltAtc 1 "true" 0 "false" ;
VAL_ 2154938368 FobProgMdStat 2 "Complete" 1 "Active" 0 "Inactive" ;
VAL_ 2155266048 RRHCSeatSw3Act 1 "true" 0 "false" ;
VAL_ 2155266048 RRHCSeatSw2Act 1 "true" 0 "false" ;
VAL_ 2155266048 RRHCSeatSw1Act 1 "true" 0 "false" ;
VAL_ 2155266048 RLHCSeatSw3Act 1 "true" 0 "false" ;
VAL_ 2155266048 RLHCSeatSw2Act 1 "true" 0 "false" ;
VAL_ 2155266048 RLHCSeatSw1Act 1 "true" 0 "false" ;
VAL_ 2155249664 RRHCSMInd3 1 "true" 0 "false" ;
VAL_ 2155249664 RRHCSMInd2 1 "true" 0 "false" ;
VAL_ 2155249664 RRHCSMInd1 1 "true" 0 "false" ;
VAL_ 2155249664 RRHCSMIndReq 3 "Flash Rate #2 Indication" 2 "Flash Rate #1 Indication" 1 "Continuous Indication" 0 "Off" ;
VAL_ 2155249664 RRHCSLSeatLev5 1 "true" 0 "false" ;
VAL_ 2155249664 RRHCSLSeatLev4 1 "true" 0 "false" ;
VAL_ 2155249664 RRHCSLSeatLev3 1 "true" 0 "false" ;
VAL_ 2155249664 RRHCSLSeatLev2 1 "true" 0 "false" ;
VAL_ 2155249664 RRHCSLSeatLev1 1 "true" 0 "false" ;
VAL_ 2155249664 RRHCSLIndReq 3 "Flash Rate #2 Indication" 2 "Flash Rate #1 Indication" 1 "Continuous Indication" 0 "Off" ;
VAL_ 2155249664 RLHCSMInd3 1 "true" 0 "false" ;
VAL_ 2155249664 RLHCSMInd2 1 "true" 0 "false" ;
VAL_ 2155249664 RLHCSMInd1 1 "true" 0 "false" ;
VAL_ 2155249664 RLHCSMIndReq 3 "Flash Rate #2 Indication" 2 "Flash Rate #1 Indication" 1 "Continuous Indication" 0 "Off" ;
VAL_ 2155249664 RLHCSLSeatLev5 1 "true" 0 "false" ;
VAL_ 2155249664 RLHCSLSeatLev4 1 "true" 0 "false" ;
VAL_ 2155249664 RLHCSLSeatLev3 1 "true" 0 "false" ;
VAL_ 2155249664 RLHCSLSeatLev2 1 "true" 0 "false" ;
VAL_ 2155249664 RLHCSLSeatLev1 1 "true" 0 "false" ;
VAL_ 2155249664 RLHCSLIndReq 3 "Flash Rate #2 Indication" 2 "Flash Rate #1 Indication" 1 "Continuous Indication" 0 "Off" ;
VAL_ 2155184128 IdlRecmndToClEngIO 1 "true" 0 "false" ;
VAL_ 2155184128 RrStRmndrIO 1 "true" 0 "false" ;
VAL_ 2155184128 RrStRmndrCstCurrSetVal 2 "On" 1 "Off" 0 "No Action" ;
VAL_ 2155184128 RrStRmndrCstSetAvail 1 "true" 0 "false" ;
VAL_ 2155184128 SmPhRmFunCstStAval 1 "true" 0 "false" ;
VAL_ 2155184128 SmPhRmFunCstCurStVal 7 "Unused and Reserved 5" 6 "Unused and Reserved 4" 5 "Unused and Reserved 3" 4 "Unused and Reserved 2" 3 "Unused and Reserved 1" 2 "On" 1 "Off" 0 "No Action" ;
VAL_ 2155184128 TrnsShftLvrLckStat 0 "Locked" 1 "Unlocked" ;
VAL_ 2155184128 CrsSpdLmtrSwStat 9 "Between Ranges" 8 "Short to Power" 7 "Open/Short to Ground" 6 "Cancel" 5 "Cruise On/Off" 4 "SL/SW On/Off/GAP" 3 "Set" 2 "Resume" 1 "No Activation" 0 "Indeterminate" ;
VAL_ 2155184128 CrsCntrlSwStCanSwAct 1 "true" 0 "false" ;
VAL_ 2155184128 CrsCntrlSwStSwDataIntgty 3 "Illegal Range" 2 "Failure Detected" 1 "Data Invalid" 0 "Data Valid" ;
VAL_ 2155184128 CrsCntrlSwStSpdInSwAct 1 "true" 0 "false" ;
VAL_ 2155184128 CrsCntrlSwStSpDcSwAct 1 "true" 0 "false" ;
VAL_ 2155184128 CrsCntrlSwStSetSwAct 1 "true" 0 "false" ;
VAL_ 2155184128 CrsCntrlSwStResSwAct 1 "true" 0 "false" ;
VAL_ 2155184128 CrsCntrlSwStOnSwAct 1 "true" 0 "false" ;
VAL_ 2155184128 CrsCntAtv 1 "true" 0 "false" ;
VAL_ 2155167744 ShftToNtrlIO 1 "true" 0 "false" ;
VAL_ 2155167744 AppPrkBrkIO 1 "true" 0 "false" ;
VAL_ 2155167744 NRmtDtctdRstrtAllwd 1 "true" 0 "false" ;
VAL_ 2155167744 NRmtDtdPsCluRstIO 1 "true" 0 "false" ;
VAL_ 2155167744 SecPwrMdPshBtnAtv 1 "true" 0 "false" ;
VAL_ 2155167744 TSLgMdPwrCtOWAtv 1 "true" 0 "false" ;
VAL_ 2155167744 PrsBtnAgnTTrnEngOffIO 1 "true" 0 "false" ;
VAL_ 2155167744 NRmtDtdPsBrkRstIO 1 "true" 0 "false" ;
VAL_ 2155167744 NoReDetInOn 1 "true" 0 "false" ;
VAL_ 2155167744 ApplyCltPdlIO 1 "true" 0 "false" ;
VAL_ 2155167744 VehMovState 4 "Invalid" 3 "Reverse" 2 "Forward" 1 "Neutral" 0 "Parked" ;
VAL_ 2155167744 TrStLgMdAtv 1 "true" 0 "false" ;
VAL_ 2155167744 TransModInactIO 1 "true" 0 "false" ;
VAL_ 2155167744 TransModActIO 1 "true" 0 "false" ;
VAL_ 2155167744 ApplyBrkPdlIO 1 "true" 0 "false" ;
VAL_ 2155167744 Ky_IdDevPr 1 "true" 0 "false" ;
VAL_ 2155167744 KylsStrtUseTxPckIO 1 "true" 0 "false" ;
VAL_ 2155167744 ShftPrkIO 1 "true" 0 "false" ;
VAL_ 2154921984 RFRmtCntFobNm 5 "Remote Control Fob #5" 4 "Remote Control Fob #4" 3 "Remote Control Fob #3" 2 "Remote Control Fob #2" 1 "Remote Control Fob #1" 0 "No Fob" ;
VAL_ 2154921984 RFRmtCntrlFobFnc 31 "Charge Termination" 30 "Pwr Top Control Start Motion Contrl" 29 "Pwr Top Control Stop Motion Control" 28 "Comfort Close 2" 27 "Comfort Open 2" 26 "Connectivity Request" 25 "Comfort Close" 24 "Comfort Open" 23 "Right Sliding Dr Stop Motion Contrl" 22 "Left Sliding Dr Stop Motion Control" 21 "Pwr Rr Closure Start Motion Control" 20 "Pwr Rr Closure Stop Motion Control" 19 "All Door Double Lock" 18 "Pwr Rr Closure Stop While Opening" 17 "Pwr Rr Closure Stop While Closing" 16 "Power Rear Closure Open Control" 15 "Power Rear Closure Close Control" 14 "Locator Alarm Control" 13 "Fob Programmed" 12 "Engine Stop" 11 "Engine Run" 10 "Power Top Control" 9 "Power Window Control" 8 "Fuel Door Control" 7 "Panic Alarm Control" 6 "Right Sliding Door Control" 5 "Left Sliding Door Control" 4 "Rear Closure Control" 3 "All Door Unlock" 2 "Driver Door Unlock" 1 "Lock" 0 "No Activation" ;
VAL_ 2154921984 RFRmtCntFobBatLw 1 "true" 0 "false" ;
VAL_ 2154921984 FobPogLimRchdIndOn 1 "true" 0 "false" ;
VAL_ 2151317504 PrkAstRrSysStat 3 "Failed" 2 "Inhibited" 1 "Enabled" 0 "Disabled" ;
VAL_ 2151317504 PARrRgn4ObjStat 15 "Zone 15" 14 "Zone 14" 13 "Zone 13" 12 "Zone 12" 11 "Zone 11" 10 "Zone 10" 9 "Zone 9" 8 "Zone 8" 7 "Zone 7" 6 "Zone 6" 5 "Zone 5" 4 "Zone 4" 3 "Zone 3" 2 "Zone 2" 1 "Zone 1" 0 "No Object" ;
VAL_ 2151317504 PARrRgn3ObjStat 15 "Zone 15" 14 "Zone 14" 13 "Zone 13" 12 "Zone 12" 11 "Zone 11" 10 "Zone 10" 9 "Zone 9" 8 "Zone 8" 7 "Zone 7" 6 "Zone 6" 5 "Zone 5" 4 "Zone 4" 3 "Zone 3" 2 "Zone 2" 1 "Zone 1" 0 "No Object" ;
VAL_ 2151317504 PARrRgn2ObjStat 15 "Zone 15" 14 "Zone 14" 13 "Zone 13" 12 "Zone 12" 11 "Zone 11" 10 "Zone 10" 9 "Zone 9" 8 "Zone 8" 7 "Zone 7" 6 "Zone 6" 5 "Zone 5" 4 "Zone 4" 3 "Zone 3" 2 "Zone 2" 1 "Zone 1" 0 "No Object" ;
VAL_ 2151317504 PARrRgn1ObjStat 15 "Zone 15" 14 "Zone 14" 13 "Zone 13" 12 "Zone 12" 11 "Zone 11" 10 "Zone 10" 9 "Zone 9" 8 "Zone 8" 7 "Zone 7" 6 "Zone 6" 5 "Zone 5" 4 "Zone 4" 3 "Zone 3" 2 "Zone 2" 1 "Zone 1" 0 "No Object" ;
VAL_ 2151301120 PrkAsstRrOffIO 1 "true" 0 "false" ;
VAL_ 2151301120 PrkAstAdvSysAct 1 "true" 0 "false" ;
VAL_ 2151301120 PrkAstFrSysStat 3 "Failed" 2 "Inhibited" 1 "Enabled" 0 "Disabled" ;
VAL_ 2151301120 PAFrtRgn4ObjStat 15 "Zone 15" 14 "Zone 14" 13 "Zone 13" 12 "Zone 12" 11 "Zone 11" 10 "Zone 10" 9 "Zone 9" 8 "Zone 8" 7 "Zone 7" 6 "Zone 6" 5 "Zone 5" 4 "Zone 4" 3 "Zone 3" 2 "Zone 2" 1 "Zone 1" 0 "No Object" ;
VAL_ 2151301120 PAFrtRgn3ObjStat 15 "Zone 15" 14 "Zone 14" 13 "Zone 13" 12 "Zone 12" 11 "Zone 11" 10 "Zone 10" 9 "Zone 9" 8 "Zone 8" 7 "Zone 7" 6 "Zone 6" 5 "Zone 5" 4 "Zone 4" 3 "Zone 3" 2 "Zone 2" 1 "Zone 1" 0 "No Object" ;
VAL_ 2151301120 PAFrtRgn2ObjStat 15 "Zone 15" 14 "Zone 14" 13 "Zone 13" 12 "Zone 12" 11 "Zone 11" 10 "Zone 10" 9 "Zone 9" 8 "Zone 8" 7 "Zone 7" 6 "Zone 6" 5 "Zone 5" 4 "Zone 4" 3 "Zone 3" 2 "Zone 2" 1 "Zone 1" 0 "No Object" ;
VAL_ 2151301120 PAFrtRgn1ObjStat 15 "Zone 15" 14 "Zone 14" 13 "Zone 13" 12 "Zone 12" 11 "Zone 11" 10 "Zone 10" 9 "Zone 9" 8 "Zone 8" 7 "Zone 7" 6 "Zone 6" 5 "Zone 5" 4 "Zone 4" 3 "Zone 3" 2 "Zone 2" 1 "Zone 1" 0 "No Object" ;
VAL_ 2153922560 HtrVlvRqstdPstn 0 "No Request" 1 "Engine Bypass" 2 "Engine Link" 3 "Hold Current Position" ;
VAL_ 2153922560 ClntHtrElecPwrRatV 1 "Invalid" 0 "Valid" ;
VAL_ 2153922560 ClmtCtrlHtrEngRunRq 1 "Engine Run Requested" 0 "No Action" ;
VAL_ 2153922560 ClimCtrlVoltBstModReq 1 "true" 0 "false" ;
VAL_ 2153807872 PsvStrtStrngClmnLckTT 2 "Flashing Indication" 1 "Continous Indication" 0 "No indication" ;
VAL_ 2153807872 ClmSysAuxFlrIndOn 1 "true" 0 "false" ;
VAL_ 2153807872 PsDoorOpenSwActV 1 "Invalid" 0 "Valid" ;
VAL_ 2153807872 PsDoorOpenSwAct 1 "true" 0 "false" ;
VAL_ 2153807872 DrDoorOpenSwActV 1 "Invalid" 0 "Valid" ;
VAL_ 2153807872 DrDoorOpenSwAct 1 "true" 0 "false" ;
VAL_ 2151399424 WshFldLw 1 "true" 0 "false" ;
VAL_ 2154733568 LRPwrDrPosPlsblityFltAct 1 "true" 0 "false" 1 "Invalid" 0 "Valid" ;
VAL_ 2154733568 LFPwrDrPosPlsblityFltAct 1 "true" 0 "false" ;
VAL_ 2154733568 LFPwrDrInMtn 1 "true" 0 "false" ;
VAL_ 2154733568 LFDrOpen 1 "true" 0 "false" ;
VAL_ 2154733568 DrClsgMtrLFStllDtd 1 "true" 0 "false" ;
VAL_ 2154733568 RRDrOpen 1 "true" 0 "false" ;
VAL_ 2154733568 LRDrOpen 1 "true" 0 "false" ;
VAL_ 2154733568 RFDrOpen 1 "true" 0 "false" ;
VAL_ 2154733568 RRPwrDrPosPlsblityFltAct 1 "Invalid" 0 "Valid" ;
VAL_ 2154733568 RFPwrDrPosPlsblityFltACt 1 "true" 0 "false" ;
VAL_ 2154733568 RRPwrDrInMtn 1 "true" 0 "false" ;
VAL_ 2154733568 LRPwrDrInMtn 1 "true" 0 "false" ;
VAL_ 2154733568 RFPwrDrInMtn 1 "true" 0 "false" ;
VAL_ 2154733568 DrClsgMtrRRStllDtd 1 "true" 0 "false" ;
VAL_ 2154733568 DrClsgMtrLRStllDtd 1 "true" 0 "false" ;
VAL_ 2154733568 DrClsgMtrRLStllDtd 1 "true" 0 "false" ;
VAL_ 2151342080 PrkAstRtSysStat 0 "Disabled" 1 "Enabled" 2 "Inhibited" 3 "Failed" ;
VAL_ 2151342080 PARtRgn3ObjStat 0 "No Object" 1 "Zone 1" 2 "Zone 2" 3 "Zone 3" 4 "Zone 4" 5 "Zone 5" 6 "Zone 6" 7 "Zone 7" 8 "Zone 8" 9 "Zone 9" 10 "Zone 10" 11 "Zone 11" 12 "Zone 12" 13 "Zone 13" 14 "Zone 14" 15 "Zone 15" ;
VAL_ 2151342080 PARtRgn2ObjStat 0 "No Object" 1 "Zone 1" 2 "Zone 2" 3 "Zone 3" 4 "Zone 4" 5 "Zone 5" 6 "Zone 6" 7 "Zone 7" 8 "Zone 8" 9 "Zone 9" 10 "Zone 10" 11 "Zone 11" 12 "Zone 12" 13 "Zone 13" 14 "Zone 14" 15 "Zone 15" ;
VAL_ 2151342080 PARtRgn1ObjStat 0 "No Object" 1 "Zone 1" 2 "Zone 2" 3 "Zone 3" 4 "Zone 4" 5 "Zone 5" 6 "Zone 6" 7 "Zone 7" 8 "Zone 8" 9 "Zone 9" 10 "Zone 10" 11 "Zone 11" 12 "Zone 12" 13 "Zone 13" 14 "Zone 14" 15 "Zone 15" ;
VAL_ 2151325696 PrkAstLtSysStat 3 "Failed" 2 "Inhibited" 1 "Enabled" 0 "Disabled" ;
VAL_ 2151325696 PALtRgn3ObjStat 0 "No Object" 1 "Zone 1" 2 "Zone 2" 3 "Zone 3" 4 "Zone 4" 5 "Zone 5" 6 "Zone 6" 7 "Zone 7" 8 "Zone 8" 9 "Zone 9" 10 "Zone 10" 11 "Zone 11" 12 "Zone 12" 13 "Zone 13" 14 "Zone 14" 15 "Zone 15" ;
VAL_ 2151325696 PALtRgn2ObjStat 0 "No Object" 1 "Zone 1" 2 "Zone 2" 3 "Zone 3" 4 "Zone 4" 5 "Zone 5" 6 "Zone 6" 7 "Zone 7" 8 "Zone 8" 9 "Zone 9" 10 "Zone 10" 11 "Zone 11" 12 "Zone 12" 13 "Zone 13" 14 "Zone 14" 15 "Zone 15" ;
VAL_ 2151325696 PALtRgn1ObjStat 0 "No Object" 1 "Zone 1" 2 "Zone 2" 3 "Zone 3" 4 "Zone 4" 5 "Zone 5" 6 "Zone 6" 7 "Zone 7" 8 "Zone 8" 9 "Zone 9" 10 "Zone 10" 11 "Zone 11" 12 "Zone 12" 13 "Zone 13" 14 "Zone 14" 15 "Zone 15" ;
VAL_ 2150547456 OffBrdHVCVehPwrLvl 0 "None" 1 "Low" 2 "Medium" 3 "High" ;
VAL_ 2150547456 OffBrdHVCVehPwrDrtd 1 "true" 0 "false" ;
VAL_ 2150547456 OffBrdHVCVehCplrLkd 1 "true" 0 "false" ;
VAL_ 2150547456 OffBrdHVBlkChrgCmp 1 "true" 0 "false" ;
VAL_ 2150547456 ElecPrplsnMtrOvrSpdIO 1 "true" 0 "false" ;
VAL_ 2150547456 HVBatOutOfEnrgyInd 0 "No Action" 1 "Charge Vehicle Soon" 2 "Charge Vehicle Now" 3 "Out of Energy" ;
VAL_ 2150547456 CntrsOpnUndrTmpIO 1 "true" 0 "false" ;
VAL_ 2150547456 HVBatCntctrsOpnIO 1 "true" 0 "false" ;
VAL_ 2150547456 GrnAudQueReq 1 "true" 0 "false" ;
VAL_ 2150547456 SvcHybChrgSysIO 1 "true" 0 "false" ;
VAL_ 2150547456 HVChrgrSysStat 0 "Default" 1 "Idle" 2 "Initializing" 3 "Active" 4 "Complete" 5 "Aborted" ;
VAL_ 2150547456 HVChrgrCplrStat 0 "No Action" 1 "Disconnected" 2 "Connected" ;
VAL_ 2150547456 HVBatLimDTmpInd 0 "Normal" 1 "Cold" 2 "Hot" ;
VAL_ 2150547456 HVBatChrgCrdConnIO 1 "true" 0 "false" ;
VAL_ 2150547456 VehChrgMdSt 0 "Charge Depletion" 1 "Hold Charge Sustaining" 2 "Low SOC Charge Sustaining" ;
VAL_ 2150547456 ChgrSysAdblIndReq 0 "Inactive" 1 "Sequence 1" 2 "Sequence 2" 3 "Sequence 3" ;
VAL_ 2154708992 ASS2AudSrcStatCode 5 "Producing Audio" 4 "Producing Silence" 3 "Reserved" 2 "Audio Not Available" 1 "Audio Available" 0 "Device Present" ;
VAL_ 2154708992 ASS2AudSrcChType 4 "Mono Emergency" 3 "Mixed" 2 "Stereo" 1 "Mono" 0 "No Action" ;
VAL_ 2154708992 ASS2AudSrcType 28 "Phone" 24 "Sat. Digital Audio Receiver System" 20 "Digital Audio Broadcast" 16 "Remote CD Changer" 12 "Remote Digital Video Disk" 8 "Auxiliary Device" 1 "Television Tuner" ;
VAL_ 2154471424 RrClsrSnwLdIO 1 "true" 0 "false" ;
VAL_ 2154471424 RrClosAjarSwAct 1 "true" 0 "false" ;
VAL_ 2158796800 ODII_ODIInd55 1 "true" 0 "false" ;
VAL_ 2158796800 ODII_ODIInd54 1 "true" 0 "false" ;
VAL_ 2158796800 ODII_ODIInd53 1 "true" 0 "false" ;
VAL_ 2158796800 ODII_ODIInd52 1 "true" 0 "false" ;
VAL_ 2158796800 ODII_ODIInd51 1 "true" 0 "false" ;
VAL_ 2158796800 ODII_ODIInd50 1 "true" 0 "false" ;
VAL_ 2158796800 ODII_ODIInd27 1 "true" 0 "false" ;
VAL_ 2158796800 ODII_ODIInd26 1 "true" 0 "false" ;
VAL_ 2158796800 ODII_ODIInd25 1 "true" 0 "false" ;
VAL_ 2158796800 ODII_ODIInd24 1 "true" 0 "false" ;
VAL_ 2158796800 ODII_ODIInd23 1 "true" 0 "false" ;
VAL_ 2158796800 ODII_ODIInd22 1 "true" 0 "false" ;
VAL_ 2158796800 ODII_ODIInd21 1 "true" 0 "false" ;
VAL_ 2158796800 ODII_ODIInd20 1 "true" 0 "false" ;
VAL_ 2158796800 ODII_ODIInd19 1 "true" 0 "false" ;
VAL_ 2158796800 ODII_ODIInd18 1 "true" 0 "false" ;
VAL_ 2158796800 ODII_ODIInd17 1 "true" 0 "false" ;
VAL_ 2158796800 ODII_ODIInd16 1 "true" 0 "false" ;
VAL_ 2158796800 ODII_ODIInd15 1 "true" 0 "false" ;
VAL_ 2158796800 ODII_ODIInd14 1 "true" 0 "false" ;
VAL_ 2158796800 ODII_ODIInd13 1 "true" 0 "false" ;
VAL_ 2158796800 ODII_ODIInd12 1 "true" 0 "false" ;
VAL_ 2158796800 ODII_ODIInd11 1 "true" 0 "false" ;
VAL_ 2158796800 ODII_ODIInd10 1 "true" 0 "false" ;
VAL_ 2158796800 ODII_ODIInd9 1 "true" 0 "false" ;
VAL_ 2158796800 ODII_ODIInd8 1 "true" 0 "false" ;
VAL_ 2158796800 ODII_ODIInd7 1 "true" 0 "false" ;
VAL_ 2158796800 ODII_ODIInd6 1 "true" 0 "false" ;
VAL_ 2158796800 ODII_ODIInd5 1 "true" 0 "false" ;
VAL_ 2158796800 ODII_ODIInd4 1 "true" 0 "false" ;
VAL_ 2158796800 ODII_ODIInd3 1 "true" 0 "false" ;
VAL_ 2158796800 ODII_ODIInd2 1 "true" 0 "false" ;
VAL_ 2158796800 ODII_ODIInd1 1 "true" 0 "false" ;
VAL_ 2158796800 ODII_ODIInd56 1 "true" 0 "false" ;
VAL_ 2158796800 ODII_ODIInd49 1 "true" 0 "false" ;
VAL_ 2158796800 ODII_ODIInd48 1 "true" 0 "false" ;
VAL_ 2158796800 ODII_ODIInd47 1 "true" 0 "false" ;
VAL_ 2158796800 ODII_ODIInd46 1 "true" 0 "false" ;
VAL_ 2158796800 ODII_ODIInd45 1 "true" 0 "false" ;
VAL_ 2158796800 ODII_ODIInd44 1 "true" 0 "false" ;
VAL_ 2158796800 ODII_ODIInd43 1 "true" 0 "false" ;
VAL_ 2158796800 ODII_ODIInd42 1 "true" 0 "false" ;
VAL_ 2158796800 ODII_ODIInd41 1 "true" 0 "false" ;
VAL_ 2158796800 ODII_ODIInd40 1 "true" 0 "false" ;
VAL_ 2158796800 ODII_ODIInd39 1 "true" 0 "false" ;
VAL_ 2158796800 ODII_ODIInd38 1 "true" 0 "false" ;
VAL_ 2158796800 ODII_ODIInd37 1 "true" 0 "false" ;
VAL_ 2158796800 ODII_ODIInd36 1 "true" 0 "false" ;
VAL_ 2158796800 ODII_ODIInd35 1 "true" 0 "false" ;
VAL_ 2158796800 ODII_ODIInd34 1 "true" 0 "false" ;
VAL_ 2158796800 ODII_ODIInd33 1 "true" 0 "false" ;
VAL_ 2158796800 ODII_ODIInd32 1 "true" 0 "false" ;
VAL_ 2158796800 ODII_ODIInd31 1 "true" 0 "false" ;
VAL_ 2158796800 ODII_ODIInd30 1 "true" 0 "false" ;
VAL_ 2158796800 ODII_ODIInd29 1 "true" 0 "false" ;
VAL_ 2158796800 ODII_ODIInd28 1 "true" 0 "false" ;
SIG_GROUP_ 2149769216 WhlRotatStatLftDrvn 1 : WRSLDWhlRotStatRst WRSLDWhlDisTpRC WRSLDSeqNum WRSLDWhlDistVal WRSLDWhlDistTmstm WRSLDWhlDistPlsCntr;
SIG_GROUP_ 2149769216 WhlRotatStatRtDrvn 1 : WRSRDWhlDisTpRC WRSRDSeqNum WRSRDWhlRotStatRst WRSRDWhlDistVal WRSRDWhlDistTmstm WRSRDWhlDistPlsCntr;
SIG_GROUP_ 2156789760 TmofDay 1 : TOD_SecofMin TOD_MinofHr TOD_HrofDay;
SIG_GROUP_ 2158878720 ODIDynDataLstRq_CntrStck 1 : ODDLC_SubIdReqM ODDLC_WrpArnd ODDLC_ReqType ODDLC_ReqDir ODDLC_NmEntries ODDLC_Idx ODDLC_FUCID ODDLC_DspMID ODDLC_DataId ODDLC_BckgndFlag;
SIG_GROUP_ 2155249664 RRHCSModeIndCtrl 1 : RRHCSMInd3 RRHCSMInd2 RRHCSMInd1 RRHCSMIndReq;
SIG_GROUP_ 2155249664 RRHCSeatLevIndCtrl 1 : RRHCSLSeatLev5 RRHCSLSeatLev4 RRHCSLSeatLev3 RRHCSLSeatLev2 RRHCSLSeatLev1 RRHCSLIndReq;
SIG_GROUP_ 2155249664 RLHCSModeIndCtrl 1 : RLHCSMInd3 RLHCSMInd2 RLHCSMInd1 RLHCSMIndReq;
SIG_GROUP_ 2155249664 RLHCSeatLevIndCtrl 1 : RLHCSLSeatLev5 RLHCSLSeatLev4 RLHCSLSeatLev3 RLHCSLSeatLev2 RLHCSLSeatLev1 RLHCSLIndReq;
SIG_GROUP_ 2155184128 CrsCntrlSwStat 1 : CrsCntrlSwStCanSwAct CrsCntrlSwStSwDataIntgty CrsCntrlSwStSpdInSwAct CrsCntrlSwStSpDcSwAct CrsCntrlSwStSetSwAct CrsCntrlSwStResSwAct CrsCntrlSwStOnSwAct;
SIG_GROUP_ 2154921984 RFAFnc 1 : RFRmtCntFobNm RFRmtCntrlFobFnc RFRmtCntFobBatLw;
SIG_GROUP_ 2151809024 DrvCycElecEngyCnsmd 1 : DCEEC_EngyPct4 DCEEC_EngyPct3 DCEEC_EngyPct2 DCEEC_EngyPct1;
SIG_GROUP_ 2150547456 OffBrdHVBlkChgCpltTm 1 : OBHVBCCT_MinofHr OBHVBCCT_HrofDay OBHVBCCT_DayofWk;
SIG_GROUP_ 2154708992 AudSrcStat2 1 : ASS2AudSrcStatCode ASS2AudSrcChType ASS2AudSrcType;
SIG_GROUP_ 2158796800 ODIInd 1 : ODII_ODIInd55 ODII_ODIInd54 ODII_ODIInd53 ODII_ODIInd52 ODII_ODIInd51 ODII_ODIInd50 ODII_ODIInd27 ODII_ODIInd26 ODII_ODIInd25 ODII_ODIInd24 ODII_ODIInd23 ODII_ODIInd22 ODII_ODIInd21 ODII_ODIInd20 ODII_ODIInd19 ODII_ODIInd18 ODII_ODIInd17 ODII_ODIInd16 ODII_ODIInd15 ODII_ODIInd14 ODII_ODIInd13 ODII_ODIInd12 ODII_ODIInd11 ODII_ODIInd10 ODII_ODIInd9 ODII_ODIInd8 ODII_ODIInd7 ODII_ODIInd6 ODII_ODIInd5 ODII_ODIInd4 ODII_ODIInd3 ODII_ODIInd2 ODII_ODIInd1 ODII_ODIInd56 ODII_ODIInd49 ODII_ODIInd48 ODII_ODIInd47 ODII_ODIInd46 ODII_ODIInd45 ODII_ODIInd44 ODII_ODIInd43 ODII_ODIInd42 ODII_ODIInd41 ODII_ODIInd40 ODII_ODIInd39 ODII_ODIInd38 ODII_ODIInd37 ODII_ODIInd36 ODII_ODIInd35 ODII_ODIInd34 ODII_ODIInd33 ODII_ODIInd32 ODII_ODIInd31 ODII_ODIInd30 ODII_ODIInd29 ODII_ODIInd28 ODII_FUCID;
SIG_GROUP_ 2158755840 ODIEvntPkt 1 : ODIE_MultiFrRetCh ODIE_FUCID ODIE_EvID;
